[part 1 of 2: packages /CAN3/ISignalGroup to /CAN3/Cluster]
AUTOSAR XML (schema 4-3-0)
package /CAN3/ISignalGroup
  36 x i signal group:
    CAN3_SG_BMS1: i-signal=[CAN3_BMSChckSum_1, CAN3_BMSRolCnct_1, CAN3_HVBPwrAvailChrg, CAN3_HVBPwrAvailChrg30, CAN3_HVBPwrAvailChrg60, CAN3_HVBPwrAvailDchrg, CAN3_HVBPwrAvailDchrg30, CAN3_HVBPwrAvailDchrg60, CAN3_HVBattCurr, CAN3_HVBattVolt], system-signal-group=CAN3_SG_BMS1
    CAN3_SG_BMS3: i-signal=[CAN3_ACChrgCurrDis, CAN3_Battsystfail_Num, CAN3_CellType, CAN3_ChrgCurType, CAN3_ChrgLampSta, CAN3_FireDetErr, CAN3_HVBChrgPwr, CAN3_HVBChrgPwrTotal, CAN3_HVBDrvPwr, CAN3_HVBDrvPwrTotal, CAN3_HVBFullChrgPwr, CAN3_HVBIsoImpedenceN, CAN3_HVBIsoImpedenceP, CAN3_HVBSOH, CAN3_HVBattErr, CAN3_HVBattPackVolt, CAN3_HVBattSOC, CAN3_HVBattSOCDis, CAN3_RechrgCyc, CAN3_RemainChrgTime], system-signal-group=CAN3_SG_BMS3
    CAN3_SG_BMS4: i-signal=[CAN3_CellTempAvg, CAN3_HVBCellVoltMax, CAN3_HVBCellVoltMin, CAN3_HVBMTempMax, CAN3_HVBMTempMin, CAN3_MaxCellTemp_Num, CAN3_MaxCellVolt_Num, CAN3_MinCellTemp_Num, CAN3_MinCellVolt_Num, CAN3_Mtemp01, CAN3_Mtemp02, CAN3_Mtemp03, CAN3_Mtemp04, CAN3_Mtemp05, CAN3_Mtemp06, CAN3_Mtemp07, CAN3_Mtemp08, CAN3_Mtemp09, CAN3_Mtemp10, CAN3_Mtemp11, CAN3_Mtemp12, CAN3_Mtemp13, CAN3_Mtemp14, CAN3_Mtemp15, CAN3_Mtemp16, CAN3_Mtemp17, CAN3_Mtemp18, CAN3_Mtemp19, CAN3_Mtemp20], system-signal-group=CAN3_SG_BMS4
    CAN3_SG_BMS5: i-signal=[CAN3_DCPortNeg_Temp, CAN3_DCPortPos_Temp, CAN3_HVInVolt, CAN3_LVBattDet12V, CAN3_OBCACCSLimit, CAN3_OBCDCCurLm, CAN3_OBCDCVoltLm, CAN3_OBCEna, CAN3_ReChargerStaFromEvcc], system-signal-group=CAN3_SG_BMS5
    CAN3_SG_BMS6: i-signal=[CAN3_BMSChckSum, CAN3_BMSRolCnct, CAN3_BMS_READY, CAN3_BMS_Warn_1, CAN3_BMS_Warn_2, CAN3_BMS_Warn_3, CAN3_BMS_Warn_4, CAN3_BMS_Warn_5, CAN3_BMS_Warn_6, CAN3_BMS_Warn_7, CAN3_BMS_Warn_8, CAN3_CellUnconsistErr, CAN3_ChrgInLockReq, CAN3_ChrgPlugSta, CAN3_DCChrgSysShockErr, CAN3_DisChrgPlugErr, CAN3_ExtChrgSta, CAN3_HVBCellOvrVoltErr, CAN3_HVBCellOvrVoltWarn, CAN3_HVBCellUdrVoltWarn, CAN3_HVBCellUnbalanErr, CAN3_HVBCellUndrVoltErr, CAN3_HVBChrgErr, CAN3_HVBContactorSta, CAN3_HVBHVILErr, CAN3_HVBOvrChrgCurrErr, CAN3_HVBOvrDchrgCurErr, CAN3_HVBOvrSOCErr, CAN3_HVBOvrTempErr, CAN3_HVBOvrTempWarn, CAN3_HVBOvrVoltErr, CAN3_HVBPrechrgSta, CAN3_HVBPreheatPrecoolSta, CAN3_HVBSOCJumpError, CAN3_HVBShrtChrgCurrErr, CAN3_HVBShrtDischrgCurrErr, CAN3_HVBTempDiffErr, CAN3_HVBUndrSOCErr, CAN3_HVBUndrTempErr, CAN3_HVBUndrTempWarn, CAN3_HVBUndrVoltErr, CAN3_HVBattReady4Pre, CAN3_HVILSta, CAN3_IsoDetSta, CAN3_SystemUncomErr, CAN3_V2LSta], system-signal-group=CAN3_SG_BMS6
    CAN3_SG_BMS8: i-signal=[CAN3_ACChrgStop, CAN3_CurrentErrorID, CAN3_DCChrgCurrent, CAN3_DCChrgStop, CAN3_DCChrgVoltage, CAN3_G0standard, CAN3_MainChrgRlyNegDriReq, CAN3_MainChrgRlyNegOutterVoltage, CAN3_MainChrgRlyNegSta, CAN3_MainChrgRlyPosDriReq, CAN3_MainChrgRlyPosOutterVoltage, CAN3_MainChrgRlyPosSta, CAN3_MainPosstandard, CAN3_MainRlyNegDriReq, CAN3_MainRlyNegOutterVoltage, CAN3_MainRlyNegSta, CAN3_MainRlyPosDriReq, CAN3_MainRlyPosInnerVoltage, CAN3_MainRlyPosOutterVoltage, CAN3_MainRlyPosSta, CAN3_TherRunawayErrMask], system-signal-group=CAN3_SG_BMS8
    CAN3_SG_CCU1: i-signal=[CAN3_CS_CCU1, CAN3_DCDCAuxCur, CAN3_DCDCAuxVolt, CAN3_DCDCHVCur, CAN3_DCDCInVoltInf, CAN3_DCDCPreCompleted, CAN3_OBCDCCurrInf, CAN3_OBCDCVoltInf, CAN3_OBCPreCompleted, CAN3_OBCV2LINVOTP, CAN3_OBCV2LInsuFault, CAN3_OBCV2LVinOVP, CAN3_OBCV2LVinUVP, CAN3_OBCV2LVoutOCP, CAN3_OBCV2LVoutOVP, CAN3_OBCV2LVoutUVP, CAN3_OBCWakeup4Plugin, CAN3_RC_CCU1], system-signal-group=CAN3_SG_CCU1
    CAN3_SG_CCU2: i-signal=[CAN3_CS_CCU2, CAN3_DCDCEnaSta, CAN3_DCDCFaultSta, CAN3_DCDCReady4Pre, CAN3_DCDCTemp, CAN3_OBCACCurrInf, CAN3_OBCACVoltInf, CAN3_OBCDCP, CAN3_OBCEnaSta, CAN3_OBCFaultSta, CAN3_OBCPluginSta, CAN3_OBCReady4Pre, CAN3_OBCRlySta, CAN3_OBCTemp, CAN3_OBCV2LSta, CAN3_OBC_AC_Cur_Lim, CAN3_RC_CCU2], system-signal-group=CAN3_SG_CCU2
    CAN3_SG_EBM1: i-signal=[CAN3_EBM1_CS, CAN3_EBM1_RC, CAN3_EBMErrSta, CAN3_EBMRLampSta, CAN3_EBMSta], system-signal-group=CAN3_SG_EBM1
    CAN3_SG_FD3_BCM1: i-signal=[CAN3_AllDoorSW, CAN3_AntiTheftSeatFold, CAN3_AntitheftSta, CAN3_BCM_Buzzer_Req, CAN3_BCM_DoorLock_Sta, CAN3_BrakeLamp, CAN3_CTDCtrl, CAN3_CTDLockSW, CAN3_CTDUnlockSW, CAN3_CrashDetd, CAN3_Dimmer, CAN3_DimmerEN, CAN3_DoorLockIND, CAN3_DrDoorSW, CAN3_Fr_ChargingDoorCtrl, CAN3_Fr_FogLamp, CAN3_Fr_Wiper_H, CAN3_Fr_Wiper_L, CAN3_H_Beam, CAN3_HazardSW, CAN3_HoodSW, CAN3_HornCtrl, CAN3_LBSD, CAN3_LDRL, CAN3_LTurnLP, CAN3_L_APM_WdwEnable, CAN3_L_Beam, CAN3_LockSetting, CAN3_MirrorCtrl, CAN3_MirrorDefog, CAN3_PosLamp, CAN3_PsDoorSW, CAN3_RBSD, CAN3_RDRL, CAN3_RLDoorSW, CAN3_RRDoorSW, CAN3_RTurnLP, CAN3_ReverseLamp, CAN3_RoomLampH, CAN3_RoomLampL, CAN3_Rr_ChargingDoorCtrl, CAN3_Rr_Defog, CAN3_Rr_FogLamp, CAN3_Rr_Wiper, CAN3_TailgateHDSW, CAN3_TailgateRemote, CAN3_Tailgate_SW, CAN3_TrunkRel, CAN3_WasherCtrl, CAN3_WiperFixMode], system-signal-group=CAN3_SG_FD3_BCM1
    CAN3_SG_FD3_OTA1: i-signal=[CAN3_OTA_DL_Available, CAN3_OTA_DL_Speed, CAN3_OTA_Debug_Code, CAN3_OTA_Emergency_Sta, CAN3_OTA_InVehicle_FW, CAN3_OTA_Lock_Req, CAN3_OTA_MDA_Status, CAN3_OTA_Mode, CAN3_OTA_Network_Type, CAN3_OTA_Permit_Agreed, CAN3_OTA_Progress_Rate, CAN3_OTA_Remained_Time, CAN3_OTA_TBOXResetReq, CAN3_OTA_Update_Available, CAN3_OTA_Updating_ECU_8bit], system-signal-group=CAN3_SG_FD3_OTA1
    CAN3_SG_FD3_THCM1: i-signal=[CAN3_BatteryMode, CAN3_CCU_ACLampSts, CAN3_CCU_ACMaxLampSts, CAN3_CCU_AutoLampSts, CAN3_CCU_AutoMidLampSts, CAN3_CCU_Dispaly_Request, CAN3_CCU_EcoSts, CAN3_CCU_FrtOnOffLampSts, CAN3_CCU_HEATMaxLampSts, CAN3_CCU_RrOnOffLampSts, CAN3_CCU_SyncLampSts, CAN3_CabinMode, CAN3_EDriveMode, CAN3_FD_AGS_Cmd, CAN3_FD_RecyAuto_Cmd, CAN3_Fr_Coolantflow, CAN3_Fr_Coolanttemp, CAN3_HPThermalRecoveryReq, CAN3_Rr_Coolantflow, CAN3_Rr_Coolanttemp, CAN3_sigAirIntenZon1St, CAN3_sigAirIntenZon3St, CAN3_sigAmbAirT, CAN3_sigCbnAirT, CAN3_sigCbnPTCPwrAct, CAN3_sigCbnSolarLeft, CAN3_sigCbnSolarRight, CAN3_sigClmtCmprPwrAct, CAN3_sigClntTHvBattOut, CAN3_sigDfrstSt, CAN3_sigHvacSt, CAN3_sigRecircSt, CAN3_sigSetTempZon1St, CAN3_sigSetTempZon2St, CAN3_sigSetTempZon3St, CAN3_sigWindDirZon1St, CAN3_sigWindDirZon3St], system-signal-group=CAN3_SG_FD3_THCM1
    CAN3_SG_FD3_THCM2: i-signal=[CAN3_ACSubMode, CAN3_APTC_ActFrRiPwr, CAN3_BatLoopActWtFlw, CAN3_CCU_CbnPreACWkSts, CAN3_CCU_CbnPreEstimdTi, CAN3_CCU_CbnPreSts, CAN3_CCU_HiVoltageReq, CAN3_CoolgFanActDuty, CAN3_DeiceModReq, CAN3_FD_Blower_Cmd, CAN3_FD_Comp_Cmd, CAN3_FD_EWP1_Cmd, CAN3_FD_EWP2_Cmd, CAN3_FD_EWP3_Cmd, CAN3_FD_EXV1_Cmd, CAN3_FD_EXV2_Cmd, CAN3_FD_FWV_Cmd, CAN3_FD_FrLeAPTCHeatPwr_Cmd, CAN3_FD_FrRiAPTCHeatPwr_Cmd, CAN3_FD_FrWPTCHeatPwr_Cmd, CAN3_FD_RrAPTCHeatPwr_Cmd, CAN3_FD_SOTXV_Cmd, CAN3_FD_SOV1_Cmd, CAN3_FD_SOV2_Cmd, CAN3_FD_SOV3_Cmd, CAN3_FD_TWV_Cmd], system-signal-group=CAN3_SG_FD3_THCM2
    CAN3_SG_FD3_V2L1: i-signal=[CAN3_Req_OBCV2LEna, CAN3_Req_V2LSwOn, CAN3_Req_V2L_IVI_Popup], system-signal-group=CAN3_SG_FD3_V2L1
    CAN3_SG_FD3_VCU0: i-signal=[CAN3_EVCCAplusPwrUpReq, CAN3_FDADC12VDet, CAN3_FDADC12VDetAvg, CAN3_FDC_VCU_ActMaxSlideRate_Sta, CAN3_FDC_VCU_AllowMovThd_OTA_Sta, CAN3_FDC_VCU_DTCCarousel_Sta, CAN3_FDC_VCU_ForceP_Cmd, CAN3_FDC_VCU_OTAPwrReqOFFChk_Sta, CAN3_FDC_VCU_OTAPwrReqStdChk_Sta, CAN3_FDC_VCU_PwrReq_OTA_Sta, CAN3_FDC_VCU_RWDRDCActive_Sta, CAN3_FDC_VCU_RegenTqLimitEn_Sta, CAN3_FDC_VCU_SlideRegenLimTq_Sta, CAN3_FDC_VCU_VehActSpd_Sta, CAN3_FDC_VCU_VehMalfunLevel_Sta, CAN3_FDC_VMC_ActStESCYaw_Sta, CAN3_FDC_VMC_LongAcc_Sta, CAN3_FUSION_CMM1, CAN3_FUSION_CMM10, CAN3_FUSION_CMM2, CAN3_FUSION_CMM3, CAN3_FUSION_CMM4, CAN3_FUSION_CMM5, CAN3_FUSION_CMM6, CAN3_FUSION_CMM7, CAN3_FUSION_CMM8, CAN3_FUSION_CMM9, CAN3_Fr_TqSource, CAN3_HVRlyOpFail, CAN3_HVTHCMSysAvail, CAN3_LVBattChrgtimeAct, CAN3_LVBattVoltSta, CAN3_LVChrgHoldTAct, CAN3_LVSilentChrgLv, CAN3_LVSilentChrgReq, CAN3_LVSilentChrgSta, CAN3_MCUActDisFail, CAN3_PMMAllowECUSleep, CAN3_PmicBootReason, CAN3_PowerDownFault, CAN3_PowerDownState, CAN3_PowerUpFault, CAN3_PowerUpState, CAN3_PwrDownReq, CAN3_PwrStaConstraint, CAN3_PwrStaONTOIVIPopReq, CAN3_PwrStaONTOIVIPopT, CAN3_PwrStaSelect, CAN3_PwrStaTOSta, CAN3_PwrUpReq, CAN3_Rr_TqSource, CAN3_SchedChgTOSta, CAN3_SilentChkAllowSleep, CAN3_SysAllowReadySta, CAN3_SysPwrSta, CAN3_TCountSta, CAN3_TimerAllowSleep, CAN3_VCUBrkSWSta, CAN3_VCUFLDoorSta, CAN3_VCUFRDoorSta, CAN3_VCURLDoorSta, CAN3_VCURRDoorSta, CAN3_VehHVPwrAvail4THCM, CAN3_WisrBootReason], system-signal-group=CAN3_SG_FD3_VCU0
    CAN3_SG_FD3_VCU1:
      com-based-signal-group-transformations=E2E_PROFILE_01_CAN3_SG_FD3_VCU1
      i-signal=[CAN3_ActiveDischReq, CAN3_CS_VCU1, CAN3_CoastDwModeStaChk, CAN3_DCDCEnaReq, CAN3_DCDCVoltSetpoint, CAN3_DemoModeStaChk, CAN3_Dr_SeatSta, CAN3_DynoModeStaChk, CAN3_HVBatCnctReq, CAN3_HVSysReadyToCharge, CAN3_LVChrgFuncStaChk, CAN3_MSA_Crl_Sta, CAN3_P_Button_Sta, CAN3_PrkReq, CAN3_PrkReqValid, CAN3_PwrSta, CAN3_RC_VCU1, CAN3_ShiftGearPosn]
      system-signal-group=CAN3_SG_FD3_VCU1
      end-to-end-transformation-i-signal-props{transformer=Technology_E2E_PROFILE_01_CAN3_SG_FD3_VCU1, data-ids=17910, data-length=64}
    CAN3_SG_FD3_VCU1_toNIDEC:
      com-based-signal-group-transformations=E2E_PROFILE_01_CAN3_SG_FD3_VCU1_toNIDEC
      i-signal=[CAN3_ActiveDischReq_toNidec, CAN3_CS_VCU1_toNidec, CAN3_CoastDwModeStaChk_toNidec, CAN3_DCDCEnaReq_toNidec, CAN3_DCDCVoltSetpoint_toNidec, CAN3_DemoModeStaChk_toNidec, CAN3_Dr_SeatSta_toNidec, CAN3_DynoModeStaChk_toNidec, CAN3_Fr_ActvDmpDisabReq_toNidec, CAN3_Fr_MCUEnaReq_toNidec, CAN3_HVBatCnctReq_toNidec, CAN3_HVSysReadyToCharge_toNidec, CAN3_LVChrgFuncStaChk_toNidec, CAN3_MSA_Crl_Sta_toNidec, CAN3_PrkReq_toNidec, CAN3_PwrSta_toNidec, CAN3_RC_VCU1_toNidec, CAN3_Rr_ActvDmpDisabReq_toNidec, CAN3_Rr_MCUEnaReq_toNidec, CAN3_ShiftGearPosn_toNidec]
      system-signal-group=CAN3_SG_FD3_VCU1_toNIDEC
      end-to-end-transformation-i-signal-props{transformer=Technology_E2E_PROFILE_01_CAN3_SG_FD3_VCU1_toNIDEC, data-ids=13815, data-length=64}
    CAN3_SG_FD3_VCU2: i-signal=[CAN3_CS_VCU2_CAN1, CAN3_Fr_ActvDmpDisabReq, CAN3_Fr_IdcMax, CAN3_Fr_IdcMin, CAN3_Fr_MCUEnaReq, CAN3_Fr_TMTqReq, CAN3_Fr_TorqMax, CAN3_Fr_TorqMin, CAN3_Fr_UdcMax, CAN3_Fr_UdcMin, CAN3_RC_VCU2_CAN1, CAN3_Rr_ActvDmpDisabReq, CAN3_Rr_IdcMax, CAN3_Rr_IdcMin, CAN3_Rr_MCUEnaReq, CAN3_Rr_TMTqReq, CAN3_Rr_TorqMax, CAN3_Rr_TorqMin, CAN3_Rr_UdcMax, CAN3_Rr_UdcMin], system-signal-group=CAN3_SG_FD3_VCU2
    CAN3_SG_FD3_VCU2_toNIDEC: i-signal=[CAN3_CS_VCU2_CAN1_toNidec, CAN3_Fr_IdcMax_toNidec, CAN3_Fr_IdcMin_toNidec, CAN3_Fr_TMTqReq_toNidec, CAN3_Fr_TorqMax_toNidec, CAN3_Fr_TorqMin_toNidec, CAN3_Fr_UdcMax_toNidec, CAN3_Fr_UdcMin_toNidec, CAN3_RC_VCU2_CAN1_toNidec, CAN3_Rr_IdcMax_toNidec, CAN3_Rr_IdcMin_toNidec, CAN3_Rr_TMTqReq_toNidec, CAN3_Rr_TorqMax_toNidec, CAN3_Rr_TorqMin_toNidec, CAN3_Rr_UdcMax_toNidec, CAN3_Rr_UdcMin_toNidec], system-signal-group=CAN3_SG_FD3_VCU2_toNIDEC
    CAN3_SG_FD3_VCU4: i-signal=[CAN3_Fr_SpdMax, CAN3_Fr_SpdMin, CAN3_Fr_TMCtrlMode_Req, CAN3_Fr_TMSpdReq, CAN3_Rr_SpdMax, CAN3_Rr_SpdMin, CAN3_Rr_TMCtrlMode_Req, CAN3_Rr_TMSpdReq], system-signal-group=CAN3_SG_FD3_VCU4
    CAN3_SG_FD3_VCU5: i-signal=[CAN3_ActAPSPosn, CAN3_Fr_EDUSpd, CAN3_Fr_EDUSpdValid, CAN3_Rr_EDUSpd, CAN3_Rr_EDUSpdValid], system-signal-group=CAN3_SG_FD3_VCU5
    CAN3_SG_GW3_CE100_0: i-signal=[CAN3_AC_Chg_Cur_Set, CAN3_COMP_ActualPwr, CAN3_COMP_ConCur, CAN3_COMP_ConVolt, CAN3_ChargeInletLockSta, CAN3_Charge_Percent_Set, CAN3_CrashOutputSts, CAN3_DriverSeatBeltCmd, CAN3_IVI_Req_V2L, CAN3_IVI_Start_Chg_req, CAN3_IVI_Stop_Chg_req, CAN3_IVI_Time_Day, CAN3_IVI_Time_Hour, CAN3_IVI_Time_Minute, CAN3_IVI_Time_Month, CAN3_IVI_Time_Second, CAN3_IVI_Unlock_Chg_req, CAN3_PTC1_PowerConsumption, CAN3_Perd_V2L, CAN3_ReserveChargeOFF_Day, CAN3_ReserveChargeOFF_Hour, CAN3_ReserveChargeOFF_Minute, CAN3_ReserveChargeOFF_Month, CAN3_ReserveChargeOFF_Year, CAN3_ReserveChargeOn_Day, CAN3_ReserveChargeOn_Hour, CAN3_ReserveChargeOn_Minute, CAN3_ReserveChargeOn_Month, CAN3_ReserveChargeOn_Year, CAN3_SOC_ADJ_BUTT, CAN3_SOC_Limit_Set, CAN3_SOC_V2LLimit, CAN3_Sched_Chg_Start, CAN3_Sched_Chg_Stop, CAN3_Sched_Chg_butt, CAN3_Sched_Chg_limit, CAN3_VehSpeed], system-signal-group=CAN3_SG_GW3_CE100_0
    CAN3_SG_GW_ESC1_toNIDEC: i-signal=CAN3_VehSpeed_toNidec, system-signal-group=CAN3_SG_GW_ESC1_toNIDEC
    CAN3_SG_GW_IVI6_toNIDEC: i-signal=[CAN3_IVI_Time_Day_toNidec, CAN3_IVI_Time_Hour_toNidec, CAN3_IVI_Time_Minute_toNidec, CAN3_IVI_Time_Month_toNidec, CAN3_IVI_Time_Second_toNidec], system-signal-group=CAN3_SG_GW_IVI6_toNIDEC
    CAN3_SG_MCU_B_F1: i-signal=[CAN3_Fr_ActvDmpDisabSta, CAN3_Fr_EDUDrtSta, CAN3_Fr_EDUOpratingSta, CAN3_Fr_EDURealTMTq, CAN3_Fr_EDURotateDirction, CAN3_Fr_EDUTqReqFbk, CAN3_Fr_MCU1Chksum, CAN3_Fr_MCU1RolCnt, CAN3_Fr_MCUBAT, CAN3_Fr_MCUDCBusCurr, CAN3_Fr_MCUDCBusVolt, CAN3_Fr_MCUDischrgSta, CAN3_Fr_MCUEnaSta, CAN3_Fr_MCUErr, CAN3_Fr_MCUIGN_sta, CAN3_Fr_MCUReady, CAN3_Fr_MCUReady4Pre, CAN3_Fr_MCUSysSta, CAN3_Fr_MCUTemp, CAN3_Fr_MotorAvailTq, CAN3_Fr_RegenAvailTq, CAN3_Fr_Reserved_bits, CAN3_Fr_TMSpd, CAN3_Fr_TMTemp, CAN3_Fr_TMid, CAN3_Fr_TMiq, CAN3_MCUWarn_F], system-signal-group=CAN3_SG_MCU_B_F1
    CAN3_SG_MCU_B_F2: i-signal=[CAN3_Fr_CoolanttempReq, CAN3_Fr_Failcode1, CAN3_Fr_Failcode2, CAN3_Fr_Failcodehistory1, CAN3_Fr_Failcodehistory2, CAN3_Fr_LLCTemp, CAN3_Fr_LLCflowReq, CAN3_Fr_MCU2Chksum, CAN3_Fr_MCU2RolCnt, CAN3_Fr_MCUTempWarn, CAN3_Fr_MCU_HW_Ver, CAN3_Fr_MCU_SW_Ver, CAN3_Fr_TMTempWarn, CAN3_MCU_B_F_FailLv_Sta, CAN3_MCU_B_F_LLCTempWarn_Sta], system-signal-group=CAN3_SG_MCU_B_F2
    CAN3_SG_MCU_B_R1: i-signal=[CAN3_MCUWarn_R, CAN3_Rr_ActvDmpDisabSta, CAN3_Rr_EDUDrtSta, CAN3_Rr_EDUOpratingSta, CAN3_Rr_EDURealTMTq, CAN3_Rr_EDURotateDirction, CAN3_Rr_EDUTqReqFbk, CAN3_Rr_MCU1Chksum, CAN3_Rr_MCU1RolCnt, CAN3_Rr_MCUBAT, CAN3_Rr_MCUDCBusCurr, CAN3_Rr_MCUDCBusVolt, CAN3_Rr_MCUDischrgSta, CAN3_Rr_MCUEnaSta, CAN3_Rr_MCUErr, CAN3_Rr_MCUIGN_sta, CAN3_Rr_MCUReady, CAN3_Rr_MCUReady4Pre, CAN3_Rr_MCUSysSta, CAN3_Rr_MCUTemp, CAN3_Rr_MotorAvailTq, CAN3_Rr_RegenAvailTq, CAN3_Rr_Reserved_bits, CAN3_Rr_TMSpd, CAN3_Rr_TMTemp, CAN3_Rr_TMid, CAN3_Rr_TMiq], system-signal-group=CAN3_SG_MCU_B_R1
    CAN3_SG_MCU_B_R2: i-signal=[CAN3_MCU_B_R_FailLv_Sta, CAN3_MCU_B_R_LLCTempWarn_Sta, CAN3_Rr_CoolanttempReq, CAN3_Rr_Failcode1, CAN3_Rr_Failcode2, CAN3_Rr_Failcodehistory1, CAN3_Rr_Failcodehistory2, CAN3_Rr_LLCTemp, CAN3_Rr_LLCflowReq, CAN3_Rr_MCU2Chksum, CAN3_Rr_MCU2RolCnt, CAN3_Rr_MCU3_HW_Ver, CAN3_Rr_MCU3_SW_Ver, CAN3_Rr_MCUTempWarn, CAN3_Rr_TMTempWarn], system-signal-group=CAN3_SG_MCU_B_R2
    CAN3_SG_MCU_N_F1: i-signal=[CAN3_Fr_ActvDmpDisabSta_Nidec, CAN3_Fr_EDUDrtSta_Nidec, CAN3_Fr_EDUOpratingSta_Nidec, CAN3_Fr_EDURealTMTq_Nidec, CAN3_Fr_EDURotateDirction_Nidec, CAN3_Fr_EDUTqReqFbk_Nidec, CAN3_Fr_MCU1Chksum_Nidec, CAN3_Fr_MCU1RolCnt_Nidec, CAN3_Fr_MCUBAT_Nidec, CAN3_Fr_MCUDCBusCurr_Nidec, CAN3_Fr_MCUDCBusVolt_Nidec, CAN3_Fr_MCUDischrgSta_Nidec, CAN3_Fr_MCUEnaSta_Nidec, CAN3_Fr_MCUErr_Nidec, CAN3_Fr_MCUIGN_sta_Nidec, CAN3_Fr_MCUReady4Pre_Nidec, CAN3_Fr_MCUReady_Nidec, CAN3_Fr_MCUSysSta_Nidec, CAN3_Fr_MCUTemp_Nidec, CAN3_Fr_MotorAvailTq_Nidec, CAN3_Fr_RegenAvailTq_Nidec, CAN3_Fr_Reserved_bits_Nidec, CAN3_Fr_TMSpd_Nidec, CAN3_Fr_TMTemp_Nidec, CAN3_Fr_TMid_Nidec, CAN3_Fr_TMiq_Nidec, CAN3_MCUWarn_F_Nidec], system-signal-group=CAN3_SG_MCU_N_F1
    CAN3_SG_MCU_N_F2: i-signal=[CAN3_Fr_CoolanttempReq_Nidec, CAN3_Fr_EOP_SpdSet_Nidec, CAN3_Fr_Failcode1_Nidec, CAN3_Fr_Failcode2_Nidec, CAN3_Fr_Failcodehistory1_Nidec, CAN3_Fr_Failcodehistory2_Nidec, CAN3_Fr_LLCTemp_Nidec, CAN3_Fr_LLCflowReq_Nidec, CAN3_Fr_MCU2Chksum_Nidec, CAN3_Fr_MCU2RolCnt_Nidec, CAN3_Fr_MCUTempWarn_Nidec, CAN3_Fr_TMTempWarn_Nidec, CAN3_MCU_F_ResetCnt_Sta], system-signal-group=CAN3_SG_MCU_N_F2
    CAN3_SG_MCU_N_F3: i-signal=[CAN3_Fr_MCU_HW_Ver_Nidec, CAN3_Fr_MCU_SW_Ver_Nidec], system-signal-group=CAN3_SG_MCU_N_F3
    CAN3_SG_MCU_N_R1: i-signal=[CAN3_MCUWarn_R_Nidec, CAN3_Rr_ActvDmpDisabSta_Nidec, CAN3_Rr_EDUDrtSta_Nidec, CAN3_Rr_EDUOpratingSta_Nidec, CAN3_Rr_EDURealTMTq_Nidec, CAN3_Rr_EDURotateDirction_Nidec, CAN3_Rr_EDUTqReqFbk_Nidec, CAN3_Rr_MCU1Chksum_Nidec, CAN3_Rr_MCU1RolCnt_Nidec, CAN3_Rr_MCUBAT_Nidec, CAN3_Rr_MCUDCBusCurr_Nidec, CAN3_Rr_MCUDCBusVolt_Nidec, CAN3_Rr_MCUDischrgSta_Nidec, CAN3_Rr_MCUEnaSta_Nidec, CAN3_Rr_MCUErr_Nidec, CAN3_Rr_MCUIGN_sta_Nidec, CAN3_Rr_MCUReady4Pre_Nidec, CAN3_Rr_MCUReady_Nidec, CAN3_Rr_MCUSysSta_Nidec, CAN3_Rr_MCUTemp_Nidec, CAN3_Rr_MotorAvailTq_Nidec, CAN3_Rr_RegenAvailTq_Nidec, CAN3_Rr_Reserved_bits_Nidec, CAN3_Rr_TMSpd_Nidec, CAN3_Rr_TMTemp_Nidec, CAN3_Rr_TMid_Nidec, CAN3_Rr_TMiq_Nidec], system-signal-group=CAN3_SG_MCU_N_R1
    CAN3_SG_MCU_N_R2: i-signal=[CAN3_MCU_R_ResetCnt_Sta, CAN3_Rr_CoolanttempReq_Nidec, CAN3_Rr_EOP_SpdSet_Nidec, CAN3_Rr_Failcode1_Nidec, CAN3_Rr_Failcode2_Nidec, CAN3_Rr_Failcodehistory1_Nidec, CAN3_Rr_Failcodehistory2_Nidec, CAN3_Rr_LLCTemp_Nidec, CAN3_Rr_LLCflowReq_Nidec, CAN3_Rr_MCU2Chksum_Nidec, CAN3_Rr_MCU2RolCnt_Nidec, CAN3_Rr_MCUTempWarn_Nidec, CAN3_Rr_TMTempWarn_Nidec], system-signal-group=CAN3_SG_MCU_N_R2
    CAN3_SG_MCU_N_R3: i-signal=[CAN3_Rr_MCU3_HW_Ver_Nidec, CAN3_Rr_MCU3_SW_Ver_Nidec], system-signal-group=CAN3_SG_MCU_N_R3
    CAN3_SG_Shifter1: i-signal=[CAN3_Shifter_CRC8, CAN3_Shifter_Fail_sta, CAN3_Shifter_Handle_Cmd, CAN3_Shifter_RC], system-signal-group=CAN3_SG_Shifter1
    CAN3_SG_Shifter2: i-signal=[CAN3_CSW2_DimSw_Sta, CAN3_CSW2_FWasSw_Sta, CAN3_CSW2_FWipSw_Sta, CAN3_CSW2_PassSW_Sta, CAN3_CSW2_RWipWasSw_Sta, CAN3_CSW2_TurnSw_Sta], system-signal-group=CAN3_SG_Shifter2
package /CAN3/Cluster
  can cluster CAN3: baudrate=500, can-fd-baudrate=2000
    can physical channel CAN3: comm-connectors=ConnCAN3
      frame CAN3_BMS1: id 0x171, frame-length=16, can-addressing-mode=STANDARD, can-fd-frame-support=true, can-frame-rx-behavior=CAN-FD, can-frame-tx-behavior=CAN-FD
        pdu CAN3_BMS1: length=16, minimum-delay=0.0, transmission-mode-true-timing=cyclic-timing=time-period=0.01, unused-bit-pattern=0
          mapping CAN3_SG_BMS1: i-signal-group=CAN3_SG_BMS1, start-position=0, transfer-property=PENDING
          signal CAN3_BMSChckSum_1: start 7, 8 bit, big-endian, i-signal-type=PRIMITIVE, init-value=constant-reference=Init_CAN3_BMSChckSum_1, base-type=uint8, implementation-data-type=uint8, transfer-property=PENDING
          signal CAN3_BMSRolCnct_1: start 11, 4 bit, big-endian, i-signal-type=PRIMITIVE, init-value=constant-reference=Init_CAN3_BMSRolCnct_1, base-type=uint8, implementation-data-type=uint8, transfer-property=PENDING
          signal CAN3_HVBPwrAvailChrg: start 91, 12 bit, big-endian, i-signal-type=PRIMITIVE, init-value=constant-reference=Init_CAN3_HVBPwrAvailChrg, base-type=uint16, implementation-data-type=uint16, transfer-property=PENDING
          signal CAN3_HVBPwrAvailChrg30: start 115, 12 bit, big-endian, i-signal-type=PRIMITIVE, init-value=constant-reference=Init_CAN3_HVBPwrAvailChrg30, base-type=uint16, implementation-data-type=uint16, transfer-property=PENDING
          signal CAN3_HVBPwrAvailChrg60: start 67, 12 bit, big-endian, i-signal-type=PRIMITIVE, init-value=constant-reference=Init_CAN3_HVBPwrAvailChrg60, base-type=uint16, implementation-data-type=uint16, transfer-property=PENDING
          signal CAN3_HVBPwrAvailDchrg: start 87, 12 bit, big-endian, i-signal-type=PRIMITIVE, init-value=constant-reference=Init_CAN3_HVBPwrAvailDchrg, base-type=uint16, implementation-data-type=uint16, transfer-property=PENDING
          signal CAN3_HVBPwrAvailDchrg30: start 111, 12 bit, big-endian, i-signal-type=PRIMITIVE, init-value=constant-reference=Init_CAN3_HVBPwrAvailDchrg30, base-type=uint16, implementation-data-type=uint16, transfer-property=PENDING
          signal CAN3_HVBPwrAvailDchrg60: start 63, 12 bit, big-endian, i-signal-type=PRIMITIVE, init-value=constant-reference=Init_CAN3_HVBPwrAvailDchrg60, base-type=uint16, implementation-data-type=uint16, transfer-property=PENDING
          signal CAN3_HVBattCurr: start 46, 15 bit, big-endian, i-signal-type=PRIMITIVE, init-value=constant-reference=Init_CAN3_HVBattCurr, base-type=uint16, implementation-data-type=uint16, transfer-property=PENDING
          signal CAN3_HVBattVolt: start 28, 13 bit, big-endian, i-signal-type=PRIMITIVE, init-value=constant-reference=Init_CAN3_HVBattVolt, base-type=uint16, implementation-data-type=uint16, transfer-property=PENDING
      frame CAN3_BMS3: id 0x329, frame-length=32, can-addressing-mode=STANDARD, can-fd-frame-support=true, can-frame-rx-behavior=CAN-FD, can-frame-tx-behavior=CAN-FD
        pdu CAN3_BMS3: length=32, minimum-delay=0.0, transmission-mode-true-timing={cyclic-timing=time-period=1, event-controlled-timing={number-of-repetitions=0, repetition-period=0}}, unused-bit-pattern=0
          mapping CAN3_SG_BMS3: i-signal-group=CAN3_SG_BMS3, start-position=0, transfer-property=TRIGGERED-ON-CHANGE
          signal CAN3_ACChrgCurrDis: start 54, 15 bit, big-endian, i-signal-type=PRIMITIVE, init-value=constant-reference=Init_CAN3_ACChrgCurrDis, base-type=uint16, implementation-data-type=uint16, transfer-property=PENDING
          signal CAN3_Battsystfail_Num: start 95, 8 bit, big-endian, i-signal-type=PRIMITIVE, init-value=constant-reference=Init_CAN3_Battsystfail_Num, base-type=uint8, implementation-data-type=uint8, transfer-property=PENDING
          signal CAN3_CellType: start 69, 4 bit, big-endian, i-signal-type=PRIMITIVE, init-value=constant-reference=Init_CAN3_CellType, base-type=uint8, implementation-data-type=uint8, transfer-property=PENDING
          signal CAN3_ChrgCurType: start 233, 2 bit, big-endian, i-signal-type=PRIMITIVE, init-value=constant-reference=Init_CAN3_ChrgCurType, base-type=uint8, implementation-data-type=uint8, transfer-property=TRIGGERED-ON-CHANGE
          signal CAN3_ChrgLampSta: start 235, 2 bit, big-endian, i-signal-type=PRIMITIVE, init-value=constant-reference=Init_CAN3_ChrgLampSta, base-type=uint8, implementation-data-type=uint8, transfer-property=TRIGGERED-ON-CHANGE
          signal CAN3_FireDetErr: start 239, 1 bit, big-endian, i-signal-type=PRIMITIVE, init-value=constant-reference=Init_CAN3_FireDetErr, base-type=uint8, implementation-data-type=uint8, transfer-property=TRIGGERED-ON-CHANGE
          signal CAN3_HVBChrgPwr: start 185, 10 bit, big-endian, i-signal-type=PRIMITIVE, init-value=constant-reference=Init_CAN3_HVBChrgPwr, base-type=uint16, implementation-data-type=uint16, transfer-property=PENDING
          signal CAN3_HVBChrgPwrTotal: start 25, 18 bit, big-endian, i-signal-type=PRIMITIVE, init-value=constant-reference=Init_CAN3_HVBChrgPwrTotal, base-type=uint32, implementation-data-type=uint32, transfer-property=PENDING
          signal CAN3_HVBDrvPwr: start 169, 10 bit, big-endian, i-signal-type=PRIMITIVE, init-value=constant-reference=Init_CAN3_HVBDrvPwr, base-type=uint16, implementation-data-type=uint16, transfer-property=PENDING
          signal CAN3_HVBDrvPwrTotal: start 1, 18 bit, big-endian, i-signal-type=PRIMITIVE, init-value=constant-reference=Init_CAN3_HVBDrvPwrTotal, base-type=uint32, implementation-data-type=uint32, transfer-property=PENDING
          signal CAN3_HVBFullChrgPwr: start 153, 10 bit, big-endian, i-signal-type=PRIMITIVE, init-value=constant-reference=Init_CAN3_HVBFullChrgPwr, base-type=uint16, implementation-data-type=uint16, transfer-property=PENDING
          signal CAN3_HVBIsoImpedenceN: start 102, 15 bit, big-endian, i-signal-type=PRIMITIVE, init-value=constant-reference=Init_CAN3_HVBIsoImpedenceN, base-type=uint16, implementation-data-type=uint16, transfer-property=PENDING
          signal CAN3_HVBIsoImpedenceP: start 118, 15 bit, big-endian, i-signal-type=PRIMITIVE, init-value=constant-reference=Init_CAN3_HVBIsoImpedenceP, base-type=uint16, implementation-data-type=uint16, transfer-property=PENDING
          signal CAN3_HVBSOH: start 135, 8 bit, big-endian, i-signal-type=PRIMITIVE, init-value=constant-reference=Init_CAN3_HVBSOH, base-type=uint8, implementation-data-type=uint8, transfer-property=PENDING
          signal CAN3_HVBattErr: start 238, 1 bit, big-endian, i-signal-type=PRIMITIVE, init-value=constant-reference=Init_CAN3_HVBattErr, base-type=uint8, implementation-data-type=uint8, transfer-property=TRIGGERED-ON-CHANGE
          signal CAN3_HVBattPackVolt: start 204, 13 bit, big-endian, i-signal-type=PRIMITIVE, init-value=constant-reference=Init_CAN3_HVBattPackVolt, base-type=uint16, implementation-data-type=uint16, transfer-property=PENDING
          signal CAN3_HVBattSOC: start 223, 8 bit, big-endian, i-signal-type=PRIMITIVE, init-value=constant-reference=Init_CAN3_HVBattSOC, base-type=uint8, implementation-data-type=uint8, transfer-property=PENDING
          signal CAN3_HVBattSOCDis: start 231, 8 bit, big-endian, i-signal-type=PRIMITIVE, init-value=constant-reference=Init_CAN3_HVBattSOCDis, base-type=uint8, implementation-data-type=uint8, transfer-property=PENDING
          signal CAN3_RechrgCyc: start 65, 18 bit, big-endian, i-signal-type=PRIMITIVE, init-value=constant-reference=Init_CAN3_RechrgCyc, base-type=uint32, implementation-data-type=uint32, transfer-property=PENDING
          signal CAN3_RemainChrgTime: start 139, 12 bit, big-endian, i-signal-type=PRIMITIVE, init-value=constant-reference=Init_CAN3_RemainChrgTime, base-type=uint16, implementation-data-type=uint16, transfer-property=PENDING
      frame CAN3_BMS4: id 0x3E0, frame-length=48, can-addressing-mode=STANDARD, can-fd-frame-support=true, can-frame-rx-behavior=CAN-FD, can-frame-tx-behavior=CAN-FD
        pdu CAN3_BMS4: length=48, minimum-delay=0.0, transmission-mode-true-timing=cyclic-timing=time-period=0.1, unused-bit-pattern=0
          mapping CAN3_SG_BMS4: i-signal-group=CAN3_SG_BMS4, start-position=0, transfer-property=PENDING
          signal CAN3_CellTempAvg: start 351, 8 bit, big-endian, i-signal-type=PRIMITIVE, init-value=constant-reference=Init_CAN3_CellTempAvg, base-type=uint8, implementation-data-type=uint8, transfer-property=PENDING
          signal CAN3_HVBCellVoltMax: start 375, 16 bit, big-endian, i-signal-type=PRIMITIVE, init-value=constant-reference=Init_CAN3_HVBCellVoltMax, base-type=uint16, implementation-data-type=uint16, transfer-property=PENDING
          signal CAN3_HVBCellVoltMin: start 359, 16 bit, big-endian, i-signal-type=PRIMITIVE, init-value=constant-reference=Init_CAN3_HVBCellVoltMin, base-type=uint16, implementation-data-type=uint16, transfer-property=PENDING
          signal CAN3_HVBMTempMax: start 311, 8 bit, big-endian, i-signal-type=PRIMITIVE, init-value=constant-reference=Init_CAN3_HVBMTempMax, base-type=uint8, implementation-data-type=uint8, transfer-property=PENDING
          signal CAN3_HVBMTempMin: start 303, 8 bit, big-endian, i-signal-type=PRIMITIVE, init-value=constant-reference=Init_CAN3_HVBMTempMin, base-type=uint8, implementation-data-type=uint8, transfer-property=PENDING
          signal CAN3_MaxCellTemp_Num: start 327, 8 bit, big-endian, i-signal-type=PRIMITIVE, init-value=constant-reference=Init_CAN3_MaxCellTemp_Num, base-type=uint8, implementation-data-type=uint8, transfer-property=PENDING
          signal CAN3_MaxCellVolt_Num: start 343, 8 bit, big-endian, i-signal-type=PRIMITIVE, init-value=constant-reference=Init_CAN3_MaxCellVolt_Num, base-type=uint8, implementation-data-type=uint8, transfer-property=PENDING
          signal CAN3_MinCellTemp_Num: start 319, 8 bit, big-endian, i-signal-type=PRIMITIVE, init-value=constant-reference=Init_CAN3_MinCellTemp_Num, base-type=uint8, implementation-data-type=uint8, transfer-property=PENDING
          signal CAN3_MinCellVolt_Num: start 335, 8 bit, big-endian, i-signal-type=PRIMITIVE, init-value=constant-reference=Init_CAN3_MinCellVolt_Num, base-type=uint8, implementation-data-type=uint8, transfer-property=PENDING
          signal CAN3_Mtemp01: start 119, 8 bit, big-endian, i-signal-type=PRIMITIVE, init-value=constant-reference=Init_CAN3_Mtemp01, base-type=uint8, implementation-data-type=uint8, transfer-property=PENDING
          signal CAN3_Mtemp02: start 111, 8 bit, big-endian, i-signal-type=PRIMITIVE, init-value=constant-reference=Init_CAN3_Mtemp02, base-type=uint8, implementation-data-type=uint8, transfer-property=PENDING
          signal CAN3_Mtemp03: start 103, 8 bit, big-endian, i-signal-type=PRIMITIVE, init-value=constant-reference=Init_CAN3_Mtemp03, base-type=uint8, implementation-data-type=uint8, transfer-property=PENDING
          signal CAN3_Mtemp04: start 95, 8 bit, big-endian, i-signal-type=PRIMITIVE, init-value=constant-reference=Init_CAN3_Mtemp04, base-type=uint8, implementation-data-type=uint8, transfer-property=PENDING
          signal CAN3_Mtemp05: start 87, 8 bit, big-endian, i-signal-type=PRIMITIVE, init-value=constant-reference=Init_CAN3_Mtemp05, base-type=uint8, implementation-data-type=uint8, transfer-property=PENDING
          signal CAN3_Mtemp06: start 79, 8 bit, big-endian, i-signal-type=PRIMITIVE, init-value=constant-reference=Init_CAN3_Mtemp06, base-type=uint8, implementation-data-type=uint8, transfer-property=PENDING
          signal CAN3_Mtemp07: start 71, 8 bit, big-endian, i-signal-type=PRIMITIVE, init-value=constant-reference=Init_CAN3_Mtemp07, base-type=uint8, implementation-data-type=uint8, transfer-property=PENDING
          signal CAN3_Mtemp08: start 63, 8 bit, big-endian, i-signal-type=PRIMITIVE, init-value=constant-reference=Init_CAN3_Mtemp08, base-type=uint8, implementation-data-type=uint8, transfer-property=PENDING
          signal CAN3_Mtemp09: start 55, 8 bit, big-endian, i-signal-type=PRIMITIVE, init-value=constant-reference=Init_CAN3_Mtemp09, base-type=uint8, implementation-data-type=uint8, transfer-property=PENDING
          signal CAN3_Mtemp10: start 47, 8 bit, big-endian, i-signal-type=PRIMITIVE, init-value=constant-reference=Init_CAN3_Mtemp10, base-type=uint8, implementation-data-type=uint8, transfer-property=PENDING
          signal CAN3_Mtemp11: start 39, 8 bit, big-endian, i-signal-type=PRIMITIVE, init-value=constant-reference=Init_CAN3_Mtemp11, base-type=uint8, implementation-data-type=uint8, transfer-property=PENDING
          signal CAN3_Mtemp12: start 31, 8 bit, big-endian, i-signal-type=PRIMITIVE, init-value=constant-reference=Init_CAN3_Mtemp12, base-type=uint8, implementation-data-type=uint8, transfer-property=PENDING
          signal CAN3_Mtemp13: start 23, 8 bit, big-endian, i-signal-type=PRIMITIVE, init-value=constant-reference=Init_CAN3_Mtemp13, base-type=uint8, implementation-data-type=uint8, transfer-property=PENDING
          signal CAN3_Mtemp14: start 15, 8 bit, big-endian, i-signal-type=PRIMITIVE, init-value=constant-reference=Init_CAN3_Mtemp14, base-type=uint8, implementation-data-type=uint8, transfer-property=PENDING
          signal CAN3_Mtemp15: start 7, 8 bit, big-endian, i-signal-type=PRIMITIVE, init-value=constant-reference=Init_CAN3_Mtemp15, base-type=uint8, implementation-data-type=uint8, transfer-property=PENDING
          signal CAN3_Mtemp16: start 159, 8 bit, big-endian, i-signal-type=PRIMITIVE, init-value=constant-reference=Init_CAN3_Mtemp16, base-type=uint8, implementation-data-type=uint8, transfer-property=PENDING
          signal CAN3_Mtemp17: start 151, 8 bit, big-endian, i-signal-type=PRIMITIVE, init-value=constant-reference=Init_CAN3_Mtemp17, base-type=uint8, implementation-data-type=uint8, transfer-property=PENDING
          signal CAN3_Mtemp18: start 143, 8 bit, big-endian, i-signal-type=PRIMITIVE, init-value=constant-reference=Init_CAN3_Mtemp18, base-type=uint8, implementation-data-type=uint8, transfer-property=PENDING
          signal CAN3_Mtemp19: start 135, 8 bit, big-endian, i-signal-type=PRIMITIVE, init-value=constant-reference=Init_CAN3_Mtemp19, base-type=uint8, implementation-data-type=uint8, transfer-property=PENDING
          signal CAN3_Mtemp20: start 127, 8 bit, big-endian, i-signal-type=PRIMITIVE, init-value=constant-reference=Init_CAN3_Mtemp20, base-type=uint8, implementation-data-type=uint8, transfer-property=PENDING
      frame CAN3_BMS5: id 0x276, frame-length=12, can-addressing-mode=STANDARD, can-fd-frame-support=true, can-frame-rx-behavior=CAN-FD, can-frame-tx-behavior=CAN-FD
        pdu CAN3_BMS5: length=12, minimum-delay=0.0, transmission-mode-true-timing={cyclic-timing=time-period=0.1, event-controlled-timing={number-of-repetitions=0, repetition-period=0}}, unused-bit-pattern=0
          mapping CAN3_SG_BMS5: i-signal-group=CAN3_SG_BMS5, start-position=0, transfer-property=TRIGGERED-ON-CHANGE
          signal CAN3_DCPortNeg_Temp: start 7, 8 bit, big-endian, i-signal-type=PRIMITIVE, init-value=constant-reference=Init_CAN3_DCPortNeg_Temp, base-type=uint8, implementation-data-type=uint8, transfer-property=PENDING
          signal CAN3_DCPortPos_Temp: start 15, 8 bit, big-endian, i-signal-type=PRIMITIVE, init-value=constant-reference=Init_CAN3_DCPortPos_Temp, base-type=uint8, implementation-data-type=uint8, transfer-property=PENDING
          signal CAN3_HVInVolt: start 28, 13 bit, big-endian, i-signal-type=PRIMITIVE, init-value=constant-reference=Init_CAN3_HVInVolt, base-type=uint16, implementation-data-type=uint16, transfer-property=PENDING
          signal CAN3_LVBattDet12V: start 79, 8 bit, big-endian, i-signal-type=PRIMITIVE, init-value=constant-reference=Init_CAN3_LVBattDet12V, base-type=uint8, implementation-data-type=uint8, transfer-property=PENDING
          signal CAN3_OBCACCSLimit: start 23, 8 bit, big-endian, i-signal-type=PRIMITIVE, init-value=constant-reference=Init_CAN3_OBCACCSLimit, base-type=uint8, implementation-data-type=uint8, transfer-property=TRIGGERED-ON-CHANGE
          signal CAN3_OBCDCCurLm: start 57, 10 bit, big-endian, i-signal-type=PRIMITIVE, init-value=constant-reference=Init_CAN3_OBCDCCurLm, base-type=uint16, implementation-data-type=uint16, transfer-property=PENDING
          signal CAN3_OBCDCVoltLm: start 44, 13 bit, big-endian, i-signal-type=PRIMITIVE, init-value=constant-reference=Init_CAN3_OBCDCVoltLm, base-type=uint16, implementation-data-type=uint16, transfer-property=PENDING
          signal CAN3_OBCEna: start 60, 1 bit, big-endian, i-signal-type=PRIMITIVE, init-value=constant-reference=Init_CAN3_OBCEna, base-type=uint8, implementation-data-type=uint8, transfer-property=TRIGGERED-ON-CHANGE
          signal CAN3_ReChargerStaFromEvcc: start 59, 2 bit, big-endian, i-signal-type=PRIMITIVE, init-value=constant-reference=Init_CAN3_ReChargerStaFromEvcc, base-type=uint8, implementation-data-type=uint8, transfer-property=TRIGGERED-ON-CHANGE
      frame CAN3_BMS6: id 0x17A, frame-length=12, can-addressing-mode=STANDARD, can-fd-frame-support=true, can-frame-rx-behavior=CAN-FD, can-frame-tx-behavior=CAN-FD
        pdu CAN3_BMS6: length=12, minimum-delay=0.0, transmission-mode-true-timing={cyclic-timing=time-period=0.1, event-controlled-timing={number-of-repetitions=0, repetition-period=0}}, unused-bit-pattern=0
          mapping CAN3_SG_BMS6: i-signal-group=CAN3_SG_BMS6, start-position=0, transfer-property=TRIGGERED-ON-CHANGE
          signal CAN3_BMSChckSum: start 7, 8 bit, big-endian, i-signal-type=PRIMITIVE, init-value=constant-reference=Init_CAN3_BMSChckSum, base-type=uint8, implementation-data-type=uint8, transfer-property=PENDING
          signal CAN3_BMSRolCnct: start 11, 4 bit, big-endian, i-signal-type=PRIMITIVE, init-value=constant-reference=Init_CAN3_BMSRolCnct, base-type=uint8, implementation-data-type=uint8, transfer-property=PENDING
          signal CAN3_BMS_READY: start 65, 1 bit, big-endian, i-signal-type=PRIMITIVE, init-value=constant-reference=Init_CAN3_BMS_READY, base-type=uint8, implementation-data-type=uint8, transfer-property=TRIGGERED-ON-CHANGE
          signal CAN3_BMS_Warn_1: start 88, 1 bit, big-endian, i-signal-type=PRIMITIVE, init-value=constant-reference=Init_CAN3_BMS_Warn_1, base-type=uint8, implementation-data-type=uint8, transfer-property=TRIGGERED-ON-CHANGE
          signal CAN3_BMS_Warn_2: start 89, 1 bit, big-endian, i-signal-type=PRIMITIVE, init-value=constant-reference=Init_CAN3_BMS_Warn_2, base-type=uint8, implementation-data-type=uint8, transfer-property=TRIGGERED-ON-CHANGE
          signal CAN3_BMS_Warn_3: start 90, 1 bit, big-endian, i-signal-type=PRIMITIVE, init-value=constant-reference=Init_CAN3_BMS_Warn_3, base-type=uint8, implementation-data-type=uint8, transfer-property=TRIGGERED-ON-CHANGE
          signal CAN3_BMS_Warn_4: start 91, 1 bit, big-endian, i-signal-type=PRIMITIVE, init-value=constant-reference=Init_CAN3_BMS_Warn_4, base-type=uint8, implementation-data-type=uint8, transfer-property=TRIGGERED-ON-CHANGE
          signal CAN3_BMS_Warn_5: start 92, 1 bit, big-endian, i-signal-type=PRIMITIVE, init-value=constant-reference=Init_CAN3_BMS_Warn_5, base-type=uint8, implementation-data-type=uint8, transfer-property=TRIGGERED-ON-CHANGE
          signal CAN3_BMS_Warn_6: start 93, 1 bit, big-endian, i-signal-type=PRIMITIVE, init-value=constant-reference=Init_CAN3_BMS_Warn_6, base-type=uint8, implementation-data-type=uint8, transfer-property=TRIGGERED-ON-CHANGE
          signal CAN3_BMS_Warn_7: start 94, 1 bit, big-endian, i-signal-type=PRIMITIVE, init-value=constant-reference=Init_CAN3_BMS_Warn_7, base-type=uint8, implementation-data-type=uint8, transfer-property=TRIGGERED-ON-CHANGE
          signal CAN3_BMS_Warn_8: start 95, 1 bit, big-endian, i-signal-type=PRIMITIVE, init-value=constant-reference=Init_CAN3_BMS_Warn_8, base-type=uint8, implementation-data-type=uint8, transfer-property=TRIGGERED-ON-CHANGE
          signal CAN3_CellUnconsistErr: start 50, 1 bit, big-endian, i-signal-type=PRIMITIVE, init-value=constant-reference=Init_CAN3_CellUnconsistErr, base-type=uint8, implementation-data-type=uint8, transfer-property=TRIGGERED-ON-CHANGE
          signal CAN3_ChrgInLockReq: start 45, 2 bit, big-endian, i-signal-type=PRIMITIVE, init-value=constant-reference=Init_CAN3_ChrgInLockReq, base-type=uint8, implementation-data-type=uint8, transfer-property=TRIGGERED-ON-CHANGE
          signal CAN3_ChrgPlugSta: start 59, 2 bit, big-endian, i-signal-type=PRIMITIVE, init-value=constant-reference=Init_CAN3_ChrgPlugSta, base-type=uint8, implementation-data-type=uint8, transfer-property=TRIGGERED-ON-CHANGE
          signal CAN3_DCChrgSysShockErr: start 64, 1 bit, big-endian, i-signal-type=PRIMITIVE, init-value=constant-reference=Init_CAN3_DCChrgSysShockErr, base-type=uint8, implementation-data-type=uint8, transfer-property=TRIGGERED-ON-CHANGE
          signal CAN3_DisChrgPlugErr: start 47, 2 bit, big-endian, i-signal-type=PRIMITIVE, init-value=constant-reference=Init_CAN3_DisChrgPlugErr, base-type=uint8, implementation-data-type=uint8, transfer-property=TRIGGERED-ON-CHANGE
          signal CAN3_ExtChrgSta: start 61, 2 bit, big-endian, i-signal-type=PRIMITIVE, init-value=constant-reference=Init_CAN3_ExtChrgSta, base-type=uint8, implementation-data-type=uint8, transfer-property=TRIGGERED-ON-CHANGE
          signal CAN3_HVBCellOvrVoltErr: start 40, 1 bit, big-endian, i-signal-type=PRIMITIVE, init-value=constant-reference=Init_CAN3_HVBCellOvrVoltErr, base-type=uint8, implementation-data-type=uint8, transfer-property=TRIGGERED-ON-CHANGE
          signal CAN3_HVBCellOvrVoltWarn: start 53, 2 bit, big-endian, i-signal-type=PRIMITIVE, init-value=constant-reference=Init_CAN3_HVBCellOvrVoltWarn, base-type=uint8, implementation-data-type=uint8, transfer-property=TRIGGERED-ON-CHANGE
          signal CAN3_HVBCellUdrVoltWarn: start 55, 2 bit, big-endian, i-signal-type=PRIMITIVE, init-value=constant-reference=Init_CAN3_HVBCellUdrVoltWarn, base-type=uint8, implementation-data-type=uint8, transfer-property=TRIGGERED-ON-CHANGE
          signal CAN3_HVBCellUnbalanErr: start 42, 1 bit, big-endian, i-signal-type=PRIMITIVE, init-value=constant-reference=Init_CAN3_HVBCellUnbalanErr, base-type=uint8, implementation-data-type=uint8, transfer-property=TRIGGERED-ON-CHANGE
          signal CAN3_HVBCellUndrVoltErr: start 41, 1 bit, big-endian, i-signal-type=PRIMITIVE, init-value=constant-reference=Init_CAN3_HVBCellUndrVoltErr, base-type=uint8, implementation-data-type=uint8, transfer-property=TRIGGERED-ON-CHANGE
          signal CAN3_HVBChrgErr: start 39, 8 bit, big-endian, i-signal-type=PRIMITIVE, init-value=constant-reference=Init_CAN3_HVBChrgErr, base-type=uint8, implementation-data-type=uint8, transfer-property=TRIGGERED-ON-CHANGE
          signal CAN3_HVBContactorSta: start 66, 1 bit, big-endian, i-signal-type=PRIMITIVE, init-value=constant-reference=Init_CAN3_HVBContactorSta, base-type=uint8, implementation-data-type=uint8, transfer-property=TRIGGERED-ON-CHANGE
          signal CAN3_HVBHVILErr: start 79, 1 bit, big-endian, i-signal-type=PRIMITIVE, init-value=constant-reference=Init_CAN3_HVBHVILErr, base-type=uint8, implementation-data-type=uint8, transfer-property=TRIGGERED-ON-CHANGE
          signal CAN3_HVBOvrChrgCurrErr: start 72, 1 bit, big-endian, i-signal-type=PRIMITIVE, init-value=constant-reference=Init_CAN3_HVBOvrChrgCurrErr, base-type=uint8, implementation-data-type=uint8, transfer-property=TRIGGERED-ON-CHANGE
          signal CAN3_HVBOvrDchrgCurErr: start 73, 1 bit, big-endian, i-signal-type=PRIMITIVE, init-value=constant-reference=Init_CAN3_HVBOvrDchrgCurErr, base-type=uint8, implementation-data-type=uint8, transfer-property=TRIGGERED-ON-CHANGE
          signal CAN3_HVBOvrSOCErr: start 76, 1 bit, big-endian, i-signal-type=PRIMITIVE, init-value=constant-reference=Init_CAN3_HVBOvrSOCErr, base-type=uint8, implementation-data-type=uint8, transfer-property=TRIGGERED-ON-CHANGE
          signal CAN3_HVBOvrTempErr: start 74, 1 bit, big-endian, i-signal-type=PRIMITIVE, init-value=constant-reference=Init_CAN3_HVBOvrTempErr, base-type=uint8, implementation-data-type=uint8, transfer-property=TRIGGERED-ON-CHANGE
          signal CAN3_HVBOvrTempWarn: start 81, 2 bit, big-endian, i-signal-type=PRIMITIVE, init-value=constant-reference=Init_CAN3_HVBOvrTempWarn, base-type=uint8, implementation-data-type=uint8, transfer-property=TRIGGERED-ON-CHANGE
          signal CAN3_HVBOvrVoltErr: start 84, 1 bit, big-endian, i-signal-type=PRIMITIVE, init-value=constant-reference=Init_CAN3_HVBOvrVoltErr, base-type=uint8, implementation-data-type=uint8, transfer-property=TRIGGERED-ON-CHANGE
          signal CAN3_HVBPrechrgSta: start 69, 2 bit, big-endian, i-signal-type=PRIMITIVE, init-value=constant-reference=Init_CAN3_HVBPrechrgSta, base-type=uint8, implementation-data-type=uint8, transfer-property=TRIGGERED-ON-CHANGE
          signal CAN3_HVBPreheatPrecoolSta: start 63, 2 bit, big-endian, i-signal-type=PRIMITIVE, init-value=constant-reference=Init_CAN3_HVBPreheatPrecoolSta, base-type=uint8, implementation-data-type=uint8, transfer-property=TRIGGERED-ON-CHANGE
          signal CAN3_HVBSOCJumpError: start 78, 1 bit, big-endian, i-signal-type=PRIMITIVE, init-value=constant-reference=Init_CAN3_HVBSOCJumpError, base-type=uint8, implementation-data-type=uint8, transfer-property=TRIGGERED-ON-CHANGE
          signal CAN3_HVBShrtChrgCurrErr: start 86, 1 bit, big-endian, i-signal-type=PRIMITIVE, init-value=constant-reference=Init_CAN3_HVBShrtChrgCurrErr, base-type=uint8, implementation-data-type=uint8, transfer-property=TRIGGERED-ON-CHANGE
          signal CAN3_HVBShrtDischrgCurrErr: start 87, 1 bit, big-endian, i-signal-type=PRIMITIVE, init-value=constant-reference=Init_CAN3_HVBShrtDischrgCurrErr, base-type=uint8, implementation-data-type=uint8, transfer-property=TRIGGERED-ON-CHANGE
          signal CAN3_HVBTempDiffErr: start 70, 1 bit, big-endian, i-signal-type=PRIMITIVE, init-value=constant-reference=Init_CAN3_HVBTempDiffErr, base-type=uint8, implementation-data-type=uint8, transfer-property=TRIGGERED-ON-CHANGE
          signal CAN3_HVBUndrSOCErr: start 77, 1 bit, big-endian, i-signal-type=PRIMITIVE, init-value=constant-reference=Init_CAN3_HVBUndrSOCErr, base-type=uint8, implementation-data-type=uint8, transfer-property=TRIGGERED-ON-CHANGE
          signal CAN3_HVBUndrTempErr: start 75, 1 bit, big-endian, i-signal-type=PRIMITIVE, init-value=constant-reference=Init_CAN3_HVBUndrTempErr, base-type=uint8, implementation-data-type=uint8, transfer-property=TRIGGERED-ON-CHANGE
          signal CAN3_HVBUndrTempWarn: start 83, 2 bit, big-endian, i-signal-type=PRIMITIVE, init-value=constant-reference=Init_CAN3_HVBUndrTempWarn, base-type=uint8, implementation-data-type=uint8, transfer-property=TRIGGERED-ON-CHANGE
          signal CAN3_HVBUndrVoltErr: start 85, 1 bit, big-endian, i-signal-type=PRIMITIVE, init-value=constant-reference=Init_CAN3_HVBUndrVoltErr, base-type=uint8, implementation-data-type=uint8, transfer-property=TRIGGERED-ON-CHANGE
          signal CAN3_HVBattReady4Pre: start 57, 2 bit, big-endian, i-signal-type=PRIMITIVE, init-value=constant-reference=Init_CAN3_HVBattReady4Pre, base-type=uint8, implementation-data-type=uint8, transfer-property=TRIGGERED-ON-CHANGE
          signal CAN3_HVILSta: start 71, 1 bit, big-endian, i-signal-type=PRIMITIVE, init-value=constant-reference=Init_CAN3_HVILSta, base-type=uint8, implementation-data-type=uint8, transfer-property=TRIGGERED-ON-CHANGE
          signal CAN3_IsoDetSta: start 48, 1 bit, big-endian, i-signal-type=PRIMITIVE, init-value=constant-reference=Init_CAN3_IsoDetSta, base-type=uint8, implementation-data-type=uint8, transfer-property=TRIGGERED-ON-CHANGE
          signal CAN3_SystemUncomErr: start 49, 1 bit, big-endian, i-signal-type=PRIMITIVE, init-value=constant-reference=Init_CAN3_SystemUncomErr, base-type=uint8, implementation-data-type=uint8, transfer-property=TRIGGERED-ON-CHANGE
          signal CAN3_V2LSta: start 25, 2 bit, big-endian, i-signal-type=PRIMITIVE, init-value=constant-reference=Init_CAN3_V2LSta, base-type=uint8, implementation-data-type=uint8, transfer-property=TRIGGERED-ON-CHANGE
      frame CAN3_BMS8: id 0x334, frame-length=48, can-addressing-mode=STANDARD, can-fd-frame-support=true, can-frame-rx-behavior=CAN-FD, can-frame-tx-behavior=CAN-FD
        pdu CAN3_BMS8: length=48, minimum-delay=0.0, transmission-mode-true-timing=cyclic-timing=time-period=0.1, unused-bit-pattern=0
          mapping CAN3_SG_BMS8: i-signal-group=CAN3_SG_BMS8, start-position=0, transfer-property=PENDING
          signal CAN3_ACChrgStop: start 31, 8 bit, big-endian, i-signal-type=PRIMITIVE, init-value=constant-reference=Init_CAN3_ACChrgStop, base-type=uint8, implementation-data-type=uint8, transfer-property=PENDING
          signal CAN3_CurrentErrorID: start 7, 16 bit, big-endian, i-signal-type=PRIMITIVE, init-value=constant-reference=Init_CAN3_CurrentErrorID, base-type=uint16, implementation-data-type=uint16, transfer-property=PENDING
          signal CAN3_DCChrgCurrent: start 55, 32 bit, big-endian, i-signal-type=PRIMITIVE, init-value=constant-reference=Init_CAN3_DCChrgCurrent, base-type=uint32, implementation-data-type=uint32, transfer-property=PENDING
          signal CAN3_DCChrgStop: start 23, 8 bit, big-endian, i-signal-type=PRIMITIVE, init-value=constant-reference=Init_CAN3_DCChrgStop, base-type=uint8, implementation-data-type=uint8, transfer-property=PENDING
          signal CAN3_DCChrgVoltage: start 39, 16 bit, big-endian, i-signal-type=PRIMITIVE, init-value=constant-reference=Init_CAN3_DCChrgVoltage, base-type=uint16, implementation-data-type=uint16, transfer-property=PENDING
          signal CAN3_G0standard: start 215, 16 bit, big-endian, i-signal-type=PRIMITIVE, init-value=constant-reference=Init_CAN3_G0standard, base-type=uint16, implementation-data-type=uint16, transfer-property=PENDING
          signal CAN3_MainChrgRlyNegDriReq: start 143, 8 bit, big-endian, i-signal-type=PRIMITIVE, init-value=constant-reference=Init_CAN3_MainChrgRlyNegDriReq, base-type=uint8, implementation-data-type=uint8, transfer-property=PENDING
          signal CAN3_MainChrgRlyNegOutterVoltage: start 263, 16 bit, big-endian, i-signal-type=PRIMITIVE, init-value=constant-reference=Init_CAN3_MainChrgRlyNegOutterVoltage, base-type=uint16, implementation-data-type=uint16, transfer-property=PENDING
          signal CAN3_MainChrgRlyNegSta: start 167, 8 bit, big-endian, i-signal-type=PRIMITIVE, init-value=constant-reference=Init_CAN3_MainChrgRlyNegSta, base-type=uint8, implementation-data-type=uint8, transfer-property=PENDING
          signal CAN3_MainChrgRlyPosDriReq: start 135, 8 bit, big-endian, i-signal-type=PRIMITIVE, init-value=constant-reference=Init_CAN3_MainChrgRlyPosDriReq, base-type=uint8, implementation-data-type=uint8, transfer-property=PENDING
          signal CAN3_MainChrgRlyPosOutterVoltage: start 247, 16 bit, big-endian, i-signal-type=PRIMITIVE, init-value=constant-reference=Init_CAN3_MainChrgRlyPosOutterVoltage, base-type=uint16, implementation-data-type=uint16, transfer-property=PENDING
          signal CAN3_MainChrgRlyPosSta: start 175, 8 bit, big-endian, i-signal-type=PRIMITIVE, init-value=constant-reference=Init_CAN3_MainChrgRlyPosSta, base-type=uint8, implementation-data-type=uint8, transfer-property=PENDING
          signal CAN3_MainPosstandard: start 279, 16 bit, big-endian, i-signal-type=PRIMITIVE, init-value=constant-reference=Init_CAN3_MainPosstandard, base-type=uint16, implementation-data-type=uint16, transfer-property=PENDING
          signal CAN3_MainRlyNegDriReq: start 127, 8 bit, big-endian, i-signal-type=PRIMITIVE, init-value=constant-reference=Init_CAN3_MainRlyNegDriReq, base-type=uint8, implementation-data-type=uint8, transfer-property=PENDING
          signal CAN3_MainRlyNegOutterVoltage: start 231, 16 bit, big-endian, i-signal-type=PRIMITIVE, init-value=constant-reference=Init_CAN3_MainRlyNegOutterVoltage, base-type=uint16, implementation-data-type=uint16, transfer-property=PENDING
          signal CAN3_MainRlyNegSta: start 159, 8 bit, big-endian, i-signal-type=PRIMITIVE, init-value=constant-reference=Init_CAN3_MainRlyNegSta, base-type=uint8, implementation-data-type=uint8, transfer-property=PENDING
          signal CAN3_MainRlyPosDriReq: start 119, 8 bit, big-endian, i-signal-type=PRIMITIVE, init-value=constant-reference=Init_CAN3_MainRlyPosDriReq, base-type=uint8, implementation-data-type=uint8, transfer-property=PENDING
          signal CAN3_MainRlyPosInnerVoltage: start 183, 16 bit, big-endian, i-signal-type=PRIMITIVE, init-value=constant-reference=Init_CAN3_MainRlyPosInnerVoltage, base-type=uint16, implementation-data-type=uint16, transfer-property=PENDING
          signal CAN3_MainRlyPosOutterVoltage: start 199, 16 bit, big-endian, i-signal-type=PRIMITIVE, init-value=constant-reference=Init_CAN3_MainRlyPosOutterVoltage, base-type=uint16, implementation-data-type=uint16, transfer-property=PENDING
          signal CAN3_MainRlyPosSta: start 151, 8 bit, big-endian, i-signal-type=PRIMITIVE, init-value=constant-reference=Init_CAN3_MainRlyPosSta, base-type=uint8, implementation-data-type=uint8, transfer-property=PENDING
          signal CAN3_TherRunawayErrMask: start 87, 32 bit, big-endian, i-signal-type=PRIMITIVE, init-value=constant-reference=Init_CAN3_TherRunawayErrMask, base-type=uint32, implementation-data-type=uint32, transfer-property=PENDING
      frame CAN3_CCU1: id 0x185, frame-length=12, can-addressing-mode=STANDARD, can-fd-frame-support=true, can-frame-rx-behavior=CAN-FD, can-frame-tx-behavior=CAN-FD
        pdu CAN3_CCU1: length=12, minimum-delay=0.0, transmission-mode-true-timing={cyclic-timing=time-period=0.01, event-controlled-timing={number-of-repetitions=0, repetition-period=0}}, unused-bit-pattern=0
          mapping CAN3_SG_CCU1: i-signal-group=CAN3_SG_CCU1, start-position=0, transfer-property=TRIGGERED-ON-CHANGE
          signal CAN3_CS_CCU1: start 7, 8 bit, big-endian, i-signal-type=PRIMITIVE, init-value=constant-reference=Init_CAN3_CS_CCU1, base-type=uint8, implementation-data-type=uint8, transfer-property=PENDING
          signal CAN3_DCDCAuxCur: start 87, 12 bit, big-endian, i-signal-type=PRIMITIVE, init-value=constant-reference=Init_CAN3_DCDCAuxCur, base-type=uint16, implementation-data-type=uint16, transfer-property=PENDING
          signal CAN3_DCDCAuxVolt: start 48, 8 bit, big-endian, i-signal-type=PRIMITIVE, init-value=constant-reference=Init_CAN3_DCDCAuxVolt, base-type=uint8, implementation-data-type=uint8, transfer-property=PENDING
          signal CAN3_DCDCHVCur: start 65, 10 bit, big-endian, i-signal-type=PRIMITIVE, init-value=constant-reference=Init_CAN3_DCDCHVCur, base-type=uint16, implementation-data-type=uint16, transfer-property=PENDING
          signal CAN3_DCDCInVoltInf: start 44, 12 bit, big-endian, i-signal-type=PRIMITIVE, init-value=constant-reference=Init_CAN3_DCDCInVoltInf, base-type=uint16, implementation-data-type=uint16, transfer-property=PENDING
          signal CAN3_DCDCPreCompleted: start 46, 2 bit, big-endian, i-signal-type=PRIMITIVE, init-value=constant-reference=Init_CAN3_DCDCPreCompleted, base-type=uint8, implementation-data-type=uint8, transfer-property=PENDING
          signal CAN3_OBCDCCurrInf: start 26, 10 bit, big-endian, i-signal-type=PRIMITIVE, init-value=constant-reference=Init_CAN3_OBCDCCurrInf, base-type=uint16, implementation-data-type=uint16, transfer-property=PENDING
          signal CAN3_OBCDCVoltInf: start 23, 12 bit, big-endian, i-signal-type=PRIMITIVE, init-value=constant-reference=Init_CAN3_OBCDCVoltInf, base-type=uint16, implementation-data-type=uint16, transfer-property=PENDING
          signal CAN3_OBCPreCompleted: start 32, 2 bit, big-endian, i-signal-type=PRIMITIVE, init-value=constant-reference=Init_CAN3_OBCPreCompleted, base-type=uint8, implementation-data-type=uint8, transfer-property=PENDING
          signal CAN3_OBCV2LINVOTP: start 68, 1 bit, big-endian, i-signal-type=PRIMITIVE, init-value=constant-reference=Init_CAN3_OBCV2LINVOTP, base-type=uint8, implementation-data-type=uint8, transfer-property=TRIGGERED-ON-CHANGE
          signal CAN3_OBCV2LInsuFault: start 69, 1 bit, big-endian, i-signal-type=PRIMITIVE, init-value=constant-reference=Init_CAN3_OBCV2LInsuFault, base-type=uint8, implementation-data-type=uint8, transfer-property=TRIGGERED-ON-CHANGE
          signal CAN3_OBCV2LVinOVP: start 67, 1 bit, big-endian, i-signal-type=PRIMITIVE, init-value=constant-reference=Init_CAN3_OBCV2LVinOVP, base-type=uint8, implementation-data-type=uint8, transfer-property=PENDING
          signal CAN3_OBCV2LVinUVP: start 66, 1 bit, big-endian, i-signal-type=PRIMITIVE, init-value=constant-reference=Init_CAN3_OBCV2LVinUVP, base-type=uint8, implementation-data-type=uint8, transfer-property=PENDING
          signal CAN3_OBCV2LVoutOCP: start 70, 1 bit, big-endian, i-signal-type=PRIMITIVE, init-value=constant-reference=Init_CAN3_OBCV2LVoutOCP, base-type=uint8, implementation-data-type=uint8, transfer-property=TRIGGERED-ON-CHANGE
          signal CAN3_OBCV2LVoutOVP: start 71, 1 bit, big-endian, i-signal-type=PRIMITIVE, init-value=constant-reference=Init_CAN3_OBCV2LVoutOVP, base-type=uint8, implementation-data-type=uint8, transfer-property=TRIGGERED-ON-CHANGE
          signal CAN3_OBCV2LVoutUVP: start 56, 1 bit, big-endian, i-signal-type=PRIMITIVE, init-value=constant-reference=Init_CAN3_OBCV2LVoutUVP, base-type=uint8, implementation-data-type=uint8, transfer-property=TRIGGERED-ON-CHANGE
          signal CAN3_OBCWakeup4Plugin: start 27, 1 bit, big-endian, i-signal-type=PRIMITIVE, init-value=constant-reference=Init_CAN3_OBCWakeup4Plugin, base-type=uint8, implementation-data-type=uint8, transfer-property=PENDING
          signal CAN3_RC_CCU1: start 11, 4 bit, big-endian, i-signal-type=PRIMITIVE, init-value=constant-reference=Init_CAN3_RC_CCU1, base-type=uint8, implementation-data-type=uint8, transfer-property=PENDING
      frame CAN3_CCU2: id 0x1D6, frame-length=12, can-addressing-mode=STANDARD, can-fd-frame-support=true, can-frame-rx-behavior=CAN-FD, can-frame-tx-behavior=CAN-FD
        pdu CAN3_CCU2: length=12, minimum-delay=0.0, transmission-mode-true-timing={cyclic-timing=time-period=0.1, event-controlled-timing={number-of-repetitions=0, repetition-period=0}}, unused-bit-pattern=0
          mapping CAN3_SG_CCU2: i-signal-group=CAN3_SG_CCU2, start-position=0, transfer-property=TRIGGERED-ON-CHANGE
          signal CAN3_CS_CCU2: start 7, 8 bit, big-endian, i-signal-type=PRIMITIVE, init-value=constant-reference=Init_CAN3_CS_CCU2, base-type=uint8, implementation-data-type=uint8, transfer-property=PENDING
          signal CAN3_DCDCEnaSta: start 58, 1 bit, big-endian, i-signal-type=PRIMITIVE, init-value=constant-reference=Init_CAN3_DCDCEnaSta, base-type=uint8, implementation-data-type=uint8, transfer-property=TRIGGERED-ON-CHANGE
          signal CAN3_DCDCFaultSta: start 91, 2 bit, big-endian, i-signal-type=PRIMITIVE, init-value=constant-reference=Init_CAN3_DCDCFaultSta, base-type=uint8, implementation-data-type=uint8, transfer-property=TRIGGERED-ON-CHANGE
          signal CAN3_DCDCReady4Pre: start 93, 1 bit, big-endian, i-signal-type=PRIMITIVE, init-value=constant-reference=Init_CAN3_DCDCReady4Pre, base-type=uint8, implementation-data-type=uint8, transfer-property=TRIGGERED-ON-CHANGE
          signal CAN3_DCDCTemp: start 79, 8 bit, big-endian, i-signal-type=PRIMITIVE, init-value=constant-reference=Init_CAN3_DCDCTemp, base-type=uint8, implementation-data-type=uint8, transfer-property=TRIGGERED-ON-CHANGE
          signal CAN3_OBCACCurrInf: start 55, 10 bit, big-endian, i-signal-type=PRIMITIVE, init-value=constant-reference=Init_CAN3_OBCACCurrInf, base-type=uint16, implementation-data-type=uint16, transfer-property=PENDING
          signal CAN3_OBCACVoltInf: start 35, 12 bit, big-endian, i-signal-type=PRIMITIVE, init-value=constant-reference=Init_CAN3_OBCACVoltInf, base-type=uint16, implementation-data-type=uint16, transfer-property=PENDING
          signal CAN3_OBCDCP: start 57, 10 bit, big-endian, i-signal-type=PRIMITIVE, init-value=constant-reference=Init_CAN3_OBCDCP, base-type=uint16, implementation-data-type=uint16, transfer-property=PENDING
          signal CAN3_OBCEnaSta: start 60, 1 bit, big-endian, i-signal-type=PRIMITIVE, init-value=constant-reference=Init_CAN3_OBCEnaSta, base-type=uint8, implementation-data-type=uint8, transfer-property=TRIGGERED-ON-CHANGE
          signal CAN3_OBCFaultSta: start 89, 2 bit, big-endian, i-signal-type=PRIMITIVE, init-value=constant-reference=Init_CAN3_OBCFaultSta, base-type=uint8, implementation-data-type=uint8, transfer-property=TRIGGERED-ON-CHANGE
          signal CAN3_OBCPluginSta: start 59, 1 bit, big-endian, i-signal-type=PRIMITIVE, init-value=constant-reference=Init_CAN3_OBCPluginSta, base-type=uint8, implementation-data-type=uint8, transfer-property=PENDING
          signal CAN3_OBCReady4Pre: start 92, 1 bit, big-endian, i-signal-type=PRIMITIVE, init-value=constant-reference=Init_CAN3_OBCReady4Pre, base-type=uint8, implementation-data-type=uint8, transfer-property=TRIGGERED-ON-CHANGE
          signal CAN3_OBCRlySta: start 39, 2 bit, big-endian, i-signal-type=PRIMITIVE, init-value=constant-reference=Init_CAN3_OBCRlySta, base-type=uint8, implementation-data-type=uint8, transfer-property=TRIGGERED-ON-CHANGE
          signal CAN3_OBCTemp: start 87, 9 bit, big-endian, i-signal-type=PRIMITIVE, init-value=constant-reference=Init_CAN3_OBCTemp, base-type=uint16, implementation-data-type=uint16, transfer-property=PENDING
          signal CAN3_OBCV2LSta: start 31, 2 bit, big-endian, i-signal-type=PRIMITIVE, init-value=constant-reference=Init_CAN3_OBCV2LSta, base-type=uint8, implementation-data-type=uint8, transfer-property=TRIGGERED-ON-CHANGE
          signal CAN3_OBC_AC_Cur_Lim: start 37, 2 bit, big-endian, i-signal-type=PRIMITIVE, init-value=constant-reference=Init_CAN3_OBC_AC_Cur_Lim, base-type=uint8, implementation-data-type=uint8, transfer-property=TRIGGERED-ON-CHANGE
          signal CAN3_RC_CCU2: start 11, 4 bit, big-endian, i-signal-type=PRIMITIVE, init-value=constant-reference=Init_CAN3_RC_CCU2, base-type=uint8, implementation-data-type=uint8, transfer-property=PENDING
      frame CAN3_DiagFuncReqFT: id 0x7D0, frame-length=8, can-addressing-mode=STANDARD, can-fd-frame-support=true, can-frame-rx-behavior=CAN-FD, can-frame-tx-behavior=CAN-FD
        n pdu CAN3_DiagFuncReqFT: length=8
      frame CAN3_DiagPhysReqToBMS: id 0x6B0, frame-length=8, can-addressing-mode=STANDARD, can-fd-frame-support=true, can-frame-rx-behavior=CAN-FD, can-frame-tx-behavior=CAN-FD
        n pdu CAN3_DiagPhysReqToBMS: length=8
      frame CAN3_DiagPhysReqToCCU: id 0x6B3, frame-length=8, can-addressing-mode=STANDARD, can-fd-frame-support=true, can-frame-rx-behavior=CAN-FD, can-frame-tx-behavior=CAN-FD
        n pdu CAN3_DiagPhysReqToCCU: length=8
      frame CAN3_DiagPhysReqToEBM: id 0x6A3, frame-length=8, can-addressing-mode=STANDARD, can-fd-frame-support=false, can-frame-rx-behavior=CAN-20, can-frame-tx-behavior=CAN-20
        n pdu CAN3_DiagPhysReqToEBM: length=8
      frame CAN3_DiagPhysReqToEOP_F: id 0x698, frame-length=64, can-addressing-mode=STANDARD, can-fd-frame-support=true, can-frame-rx-behavior=CAN-FD, can-frame-tx-behavior=CAN-FD
        n pdu CAN3_DiagPhysReqToEOP_F: length=8
      frame CAN3_DiagPhysReqToEOP_R: id 0x693, frame-length=64, can-addressing-mode=STANDARD, can-fd-frame-support=true, can-frame-rx-behavior=CAN-FD, can-frame-tx-behavior=CAN-FD
        n pdu CAN3_DiagPhysReqToEOP_R: length=8
      frame CAN3_DiagPhysReqToMCU_B_F: id 0x68A, frame-length=64, can-addressing-mode=STANDARD, can-fd-frame-support=true, can-frame-rx-behavior=CAN-FD, can-frame-tx-behavior=CAN-FD
        n pdu CAN3_DiagPhysReqToMCU_B_F: length=8
      frame CAN3_DiagPhysReqToMCU_B_R: id 0x689, frame-length=64, can-addressing-mode=STANDARD, can-fd-frame-support=true, can-frame-rx-behavior=CAN-FD, can-frame-tx-behavior=CAN-FD
        n pdu CAN3_DiagPhysReqToMCU_B_R: length=8
      frame CAN3_DiagPhysReqToMCU_N_F: id 0x688, frame-length=8, can-addressing-mode=STANDARD, can-fd-frame-support=true, can-frame-rx-behavior=CAN-FD, can-frame-tx-behavior=CAN-FD
        n pdu CAN3_DiagPhysReqToMCU_N_F: length=8
      frame CAN3_DiagPhysReqToMCU_N_R: id 0x683, frame-length=8, can-addressing-mode=STANDARD, can-fd-frame-support=true, can-frame-rx-behavior=CAN-FD, can-frame-tx-behavior=CAN-FD
        n pdu CAN3_DiagPhysReqToMCU_N_R: length=8
      frame CAN3_DiagPhysReqToShifter: id 0x6B8, frame-length=8, can-addressing-mode=STANDARD, can-fd-frame-support=true, can-frame-rx-behavior=CAN-FD, can-frame-tx-behavior=CAN-FD
        n pdu CAN3_DiagPhysReqToShifter: length=8
      frame CAN3_DiagRespFromBMS: id 0x630, frame-length=8, can-addressing-mode=STANDARD, can-fd-frame-support=true, can-frame-rx-behavior=CAN-FD, can-frame-tx-behavior=CAN-FD
        n pdu CAN3_DiagRespFromBMS: length=8
      frame CAN3_DiagRespFromCCU: id 0x633, frame-length=8, can-addressing-mode=STANDARD, can-fd-frame-support=true, can-frame-rx-behavior=CAN-FD, can-frame-tx-behavior=CAN-FD
        n pdu CAN3_DiagRespFromCCU: length=8
      frame CAN3_DiagRespFromEBM: id 0x623, frame-length=8, can-addressing-mode=STANDARD, can-fd-frame-support=false, can-frame-rx-behavior=CAN-20, can-frame-tx-behavior=CAN-20
        n pdu CAN3_DiagRespFromEBM: length=8
      frame CAN3_DiagRespFromEOP_F: id 0x618, frame-length=64, can-addressing-mode=STANDARD, can-fd-frame-support=true, can-frame-rx-behavior=CAN-FD, can-frame-tx-behavior=CAN-FD
        n pdu CAN3_DiagRespFromEOP_F: length=8
      frame CAN3_DiagRespFromEOP_R: id 0x613, frame-length=64, can-addressing-mode=STANDARD, can-fd-frame-support=true, can-frame-rx-behavior=CAN-FD, can-frame-tx-behavior=CAN-FD
        n pdu CAN3_DiagRespFromEOP_R: length=8
      frame CAN3_DiagRespFromMCU_B_F: id 0x60A, frame-length=64, can-addressing-mode=STANDARD, can-fd-frame-support=true, can-frame-rx-behavior=CAN-FD, can-frame-tx-behavior=CAN-FD
        n pdu CAN3_DiagRespFromMCU_B_F: length=8
      frame CAN3_DiagRespFromMCU_B_R: id 0x609, frame-length=64, can-addressing-mode=STANDARD, can-fd-frame-support=true, can-frame-rx-behavior=CAN-FD, can-frame-tx-behavior=CAN-FD
        n pdu CAN3_DiagRespFromMCU_B_R: length=8
      frame CAN3_DiagRespFromMCU_N_F: id 0x608, frame-length=8, can-addressing-mode=STANDARD, can-fd-frame-support=true, can-frame-rx-behavior=CAN-FD, can-frame-tx-behavior=CAN-FD
        n pdu CAN3_DiagRespFromMCU_N_F: length=8
      frame CAN3_DiagRespFromMCU_N_R: id 0x603, frame-length=8, can-addressing-mode=STANDARD, can-fd-frame-support=true, can-frame-rx-behavior=CAN-FD, can-frame-tx-behavior=CAN-FD
        n pdu CAN3_DiagRespFromMCU_N_R: length=8
      frame CAN3_DiagRespFromShifter: id 0x638, frame-length=8, can-addressing-mode=STANDARD, can-fd-frame-support=true, can-frame-rx-behavior=CAN-FD, can-frame-tx-behavior=CAN-FD
        n pdu CAN3_DiagRespFromShifter: length=8
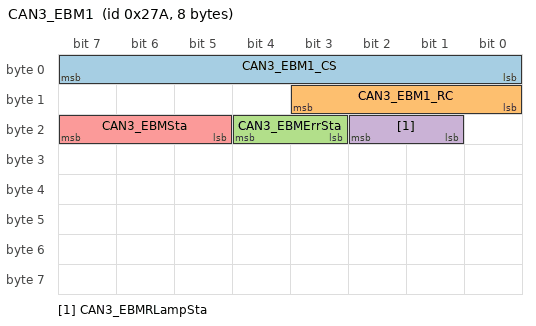
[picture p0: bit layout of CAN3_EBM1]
      frame CAN3_EBM1: id 0x27A, frame-length=8, can-addressing-mode=STANDARD, can-fd-frame-support=true, can-frame-rx-behavior=CAN-FD, can-frame-tx-behavior=CAN-FD
        pdu CAN3_EBM1: length=8, minimum-delay=0.0, transmission-mode-true-timing=cyclic-timing=time-period=0.04, unused-bit-pattern=0
          mapping CAN3_SG_EBM1: i-signal-group=CAN3_SG_EBM1, start-position=0, transfer-property=PENDING
          signal CAN3_EBM1_CS: start 7, 8 bit, big-endian, i-signal-type=PRIMITIVE, init-value=constant-reference=Init_CAN3_EBM1_CS, base-type=uint8, implementation-data-type=uint8, transfer-property=PENDING
          signal CAN3_EBM1_RC: start 11, 4 bit, big-endian, i-signal-type=PRIMITIVE, init-value=constant-reference=Init_CAN3_EBM1_RC, base-type=uint8, implementation-data-type=uint8, transfer-property=PENDING
          signal CAN3_EBMErrSta: start 20, 2 bit, big-endian, i-signal-type=PRIMITIVE, init-value=constant-reference=Init_CAN3_EBMErrSta, base-type=uint8, implementation-data-type=uint8, transfer-property=PENDING
          signal CAN3_EBMRLampSta: start 18, 2 bit, big-endian, i-signal-type=PRIMITIVE, init-value=constant-reference=Init_CAN3_EBMRLampSta, base-type=uint8, implementation-data-type=uint8, transfer-property=PENDING
          signal CAN3_EBMSta: start 23, 3 bit, big-endian, i-signal-type=PRIMITIVE, init-value=constant-reference=Init_CAN3_EBMSta, base-type=uint8, implementation-data-type=uint8, transfer-property=PENDING
      frame CAN3_FD3_BCM1: id 0x216, frame-length=16, can-addressing-mode=STANDARD, can-fd-frame-support=true, can-frame-rx-behavior=CAN-FD, can-frame-tx-behavior=CAN-FD
        pdu CAN3_FD3_BCM1: length=16, minimum-delay=0.0, transmission-mode-true-timing={cyclic-timing=time-period=0.2, event-controlled-timing={number-of-repetitions=0, repetition-period=0}}, unused-bit-pattern=0
          mapping CAN3_SG_FD3_BCM1: i-signal-group=CAN3_SG_FD3_BCM1, start-position=0, transfer-property=TRIGGERED-ON-CHANGE
          signal CAN3_AllDoorSW: start 124, 1 bit, big-endian, i-signal-type=PRIMITIVE, init-value=constant-reference=Init_CAN3_AllDoorSW, base-type=uint8, implementation-data-type=uint8, transfer-property=TRIGGERED-ON-CHANGE
          signal CAN3_AntiTheftSeatFold: start 84, 1 bit, big-endian, i-signal-type=PRIMITIVE, init-value=constant-reference=Init_CAN3_AntiTheftSeatFold, base-type=uint8, implementation-data-type=uint8, transfer-property=TRIGGERED-ON-CHANGE
          signal CAN3_AntitheftSta: start 83, 2 bit, big-endian, i-signal-type=PRIMITIVE, init-value=constant-reference=Init_CAN3_AntitheftSta, base-type=uint8, implementation-data-type=uint8, transfer-property=TRIGGERED-ON-CHANGE
          signal CAN3_BCM_Buzzer_Req: start 64, 1 bit, big-endian, i-signal-type=PRIMITIVE, init-value=constant-reference=Init_CAN3_BCM_Buzzer_Req, base-type=uint8, implementation-data-type=uint8, transfer-property=TRIGGERED-ON-CHANGE
          signal CAN3_BCM_DoorLock_Sta: start 70, 1 bit, big-endian, i-signal-type=PRIMITIVE, init-value=constant-reference=Init_CAN3_BCM_DoorLock_Sta, base-type=uint8, implementation-data-type=uint8, transfer-property=TRIGGERED-ON-CHANGE
          signal CAN3_BrakeLamp: start 90, 1 bit, big-endian, i-signal-type=PRIMITIVE, init-value=constant-reference=Init_CAN3_BrakeLamp, base-type=uint8, implementation-data-type=uint8, transfer-property=TRIGGERED-ON-CHANGE
          signal CAN3_CTDCtrl: start 113, 2 bit, big-endian, i-signal-type=PRIMITIVE, init-value=constant-reference=Init_CAN3_CTDCtrl, base-type=uint8, implementation-data-type=uint8, transfer-property=TRIGGERED-ON-CHANGE
          signal CAN3_CTDLockSW: start 118, 1 bit, big-endian, i-signal-type=PRIMITIVE, init-value=constant-reference=Init_CAN3_CTDLockSW, base-type=uint8, implementation-data-type=uint8, transfer-property=TRIGGERED-ON-CHANGE
          signal CAN3_CTDUnlockSW: start 119, 1 bit, big-endian, i-signal-type=PRIMITIVE, init-value=constant-reference=Init_CAN3_CTDUnlockSW, base-type=uint8, implementation-data-type=uint8, transfer-property=TRIGGERED-ON-CHANGE
          signal CAN3_CrashDetd: start 85, 1 bit, big-endian, i-signal-type=PRIMITIVE, init-value=constant-reference=Init_CAN3_CrashDetd, base-type=uint8, implementation-data-type=uint8, transfer-property=TRIGGERED-ON-CHANGE
          signal CAN3_Dimmer: start 78, 7 bit, big-endian, i-signal-type=PRIMITIVE, init-value=constant-reference=Init_CAN3_Dimmer, base-type=uint8, implementation-data-type=uint8, transfer-property=TRIGGERED-ON-CHANGE
          signal CAN3_DimmerEN: start 69, 1 bit, big-endian, i-signal-type=PRIMITIVE, init-value=constant-reference=Init_CAN3_DimmerEN, base-type=uint8, implementation-data-type=uint8, transfer-property=TRIGGERED-ON-CHANGE
          signal CAN3_DoorLockIND: start 125, 1 bit, big-endian, i-signal-type=PRIMITIVE, init-value=constant-reference=Init_CAN3_DoorLockIND, base-type=uint8, implementation-data-type=uint8, transfer-property=TRIGGERED-ON-CHANGE
          signal CAN3_DrDoorSW: start 120, 1 bit, big-endian, i-signal-type=PRIMITIVE, init-value=constant-reference=Init_CAN3_DrDoorSW, base-type=uint8, implementation-data-type=uint8, transfer-property=TRIGGERED-ON-CHANGE
          signal CAN3_Fr_ChargingDoorCtrl: start 115, 2 bit, big-endian, i-signal-type=PRIMITIVE, init-value=constant-reference=Init_CAN3_Fr_ChargingDoorCtrl, base-type=uint8, implementation-data-type=uint8, transfer-property=TRIGGERED-ON-CHANGE
          signal CAN3_Fr_FogLamp: start 93, 1 bit, big-endian, i-signal-type=PRIMITIVE, init-value=constant-reference=Init_CAN3_Fr_FogLamp, base-type=uint8, implementation-data-type=uint8, transfer-property=TRIGGERED-ON-CHANGE
          signal CAN3_Fr_Wiper_H: start 110, 1 bit, big-endian, i-signal-type=PRIMITIVE, init-value=constant-reference=Init_CAN3_Fr_Wiper_H, base-type=uint8, implementation-data-type=uint8, transfer-property=TRIGGERED-ON-CHANGE
          signal CAN3_Fr_Wiper_L: start 111, 1 bit, big-endian, i-signal-type=PRIMITIVE, init-value=constant-reference=Init_CAN3_Fr_Wiper_L, base-type=uint8, implementation-data-type=uint8, transfer-property=TRIGGERED-ON-CHANGE
          signal CAN3_H_Beam: start 101, 1 bit, big-endian, i-signal-type=PRIMITIVE, init-value=constant-reference=Init_CAN3_H_Beam, base-type=uint8, implementation-data-type=uint8, transfer-property=TRIGGERED-ON-CHANGE
          signal CAN3_HazardSW: start 95, 1 bit, big-endian, i-signal-type=PRIMITIVE, init-value=constant-reference=Init_CAN3_HazardSW, base-type=uint8, implementation-data-type=uint8, transfer-property=TRIGGERED-ON-CHANGE
          signal CAN3_HoodSW: start 126, 1 bit, big-endian, i-signal-type=PRIMITIVE, init-value=constant-reference=Init_CAN3_HoodSW, base-type=uint8, implementation-data-type=uint8, transfer-property=TRIGGERED-ON-CHANGE
          signal CAN3_HornCtrl: start 71, 1 bit, big-endian, i-signal-type=PRIMITIVE, init-value=constant-reference=Init_CAN3_HornCtrl, base-type=uint8, implementation-data-type=uint8, transfer-property=TRIGGERED-ON-CHANGE
          signal CAN3_LBSD: start 91, 1 bit, big-endian, i-signal-type=PRIMITIVE, init-value=constant-reference=Init_CAN3_LBSD, base-type=uint8, implementation-data-type=uint8, transfer-property=TRIGGERED-ON-CHANGE
          signal CAN3_LDRL: start 103, 1 bit, big-endian, i-signal-type=PRIMITIVE, init-value=constant-reference=Init_CAN3_LDRL, base-type=uint8, implementation-data-type=uint8, transfer-property=TRIGGERED-ON-CHANGE
          signal CAN3_LTurnLP: start 80, 1 bit, big-endian, i-signal-type=PRIMITIVE, init-value=constant-reference=Init_CAN3_LTurnLP, base-type=uint8, implementation-data-type=uint8, transfer-property=TRIGGERED-ON-CHANGE
          signal CAN3_L_APM_WdwEnable: start 87, 1 bit, big-endian, i-signal-type=PRIMITIVE, init-value=constant-reference=Init_CAN3_L_APM_WdwEnable, base-type=uint8, implementation-data-type=uint8, transfer-property=TRIGGERED-ON-CHANGE
          signal CAN3_L_Beam: start 100, 1 bit, big-endian, i-signal-type=PRIMITIVE, init-value=constant-reference=Init_CAN3_L_Beam, base-type=uint8, implementation-data-type=uint8, transfer-property=TRIGGERED-ON-CHANGE
          signal CAN3_LockSetting: start 79, 1 bit, big-endian, i-signal-type=PRIMITIVE, init-value=constant-reference=Init_CAN3_LockSetting, base-type=uint8, implementation-data-type=uint8, transfer-property=TRIGGERED-ON-CHANGE
          signal CAN3_MirrorCtrl: start 109, 2 bit, big-endian, i-signal-type=PRIMITIVE, init-value=constant-reference=Init_CAN3_MirrorCtrl, base-type=uint8, implementation-data-type=uint8, transfer-property=TRIGGERED-ON-CHANGE
          signal CAN3_MirrorDefog: start 104, 1 bit, big-endian, i-signal-type=PRIMITIVE, init-value=constant-reference=Init_CAN3_MirrorDefog, base-type=uint8, implementation-data-type=uint8, transfer-property=TRIGGERED-ON-CHANGE
          signal CAN3_PosLamp: start 102, 1 bit, big-endian, i-signal-type=PRIMITIVE, init-value=constant-reference=Init_CAN3_PosLamp, base-type=uint8, implementation-data-type=uint8, transfer-property=TRIGGERED-ON-CHANGE
          signal CAN3_PsDoorSW: start 121, 1 bit, big-endian, i-signal-type=PRIMITIVE, init-value=constant-reference=Init_CAN3_PsDoorSW, base-type=uint8, implementation-data-type=uint8, transfer-property=TRIGGERED-ON-CHANGE
          signal CAN3_RBSD: start 92, 1 bit, big-endian, i-signal-type=PRIMITIVE, init-value=constant-reference=Init_CAN3_RBSD, base-type=uint8, implementation-data-type=uint8, transfer-property=TRIGGERED-ON-CHANGE
          signal CAN3_RDRL: start 88, 1 bit, big-endian, i-signal-type=PRIMITIVE, init-value=constant-reference=Init_CAN3_RDRL, base-type=uint8, implementation-data-type=uint8, transfer-property=TRIGGERED-ON-CHANGE
          signal CAN3_RLDoorSW: start 122, 1 bit, big-endian, i-signal-type=PRIMITIVE, init-value=constant-reference=Init_CAN3_RLDoorSW, base-type=uint8, implementation-data-type=uint8, transfer-property=TRIGGERED-ON-CHANGE
          signal CAN3_RRDoorSW: start 123, 1 bit, big-endian, i-signal-type=PRIMITIVE, init-value=constant-reference=Init_CAN3_RRDoorSW, base-type=uint8, implementation-data-type=uint8, transfer-property=TRIGGERED-ON-CHANGE
          signal CAN3_RTurnLP: start 81, 1 bit, big-endian, i-signal-type=PRIMITIVE, init-value=constant-reference=Init_CAN3_RTurnLP, base-type=uint8, implementation-data-type=uint8, transfer-property=TRIGGERED-ON-CHANGE
          signal CAN3_ReverseLamp: start 89, 1 bit, big-endian, i-signal-type=PRIMITIVE, init-value=constant-reference=Init_CAN3_ReverseLamp, base-type=uint8, implementation-data-type=uint8, transfer-property=TRIGGERED-ON-CHANGE
          signal CAN3_RoomLampH: start 68, 1 bit, big-endian, i-signal-type=PRIMITIVE, init-value=constant-reference=Init_CAN3_RoomLampH, base-type=uint8, implementation-data-type=uint8, transfer-property=TRIGGERED-ON-CHANGE
          signal CAN3_RoomLampL: start 67, 1 bit, big-endian, i-signal-type=PRIMITIVE, init-value=constant-reference=Init_CAN3_RoomLampL, base-type=uint8, implementation-data-type=uint8, transfer-property=TRIGGERED-ON-CHANGE
          signal CAN3_Rr_ChargingDoorCtrl: start 117, 2 bit, big-endian, i-signal-type=PRIMITIVE, init-value=constant-reference=Init_CAN3_Rr_ChargingDoorCtrl, base-type=uint8, implementation-data-type=uint8, transfer-property=TRIGGERED-ON-CHANGE
          signal CAN3_Rr_Defog: start 105, 1 bit, big-endian, i-signal-type=PRIMITIVE, init-value=constant-reference=Init_CAN3_Rr_Defog, base-type=uint8, implementation-data-type=uint8, transfer-property=TRIGGERED-ON-CHANGE
          signal CAN3_Rr_FogLamp: start 94, 1 bit, big-endian, i-signal-type=PRIMITIVE, init-value=constant-reference=Init_CAN3_Rr_FogLamp, base-type=uint8, implementation-data-type=uint8, transfer-property=TRIGGERED-ON-CHANGE
          signal CAN3_Rr_Wiper: start 96, 1 bit, big-endian, i-signal-type=PRIMITIVE, init-value=constant-reference=Init_CAN3_Rr_Wiper, base-type=uint8, implementation-data-type=uint8, transfer-property=TRIGGERED-ON-CHANGE
          signal CAN3_TailgateHDSW: start 107, 1 bit, big-endian, i-signal-type=PRIMITIVE, init-value=constant-reference=Init_CAN3_TailgateHDSW, base-type=uint8, implementation-data-type=uint8, transfer-property=TRIGGERED-ON-CHANGE
          signal CAN3_TailgateRemote: start 66, 2 bit, big-endian, i-signal-type=PRIMITIVE, init-value=constant-reference=Init_CAN3_TailgateRemote, base-type=uint8, implementation-data-type=uint8, transfer-property=TRIGGERED-ON-CHANGE
          signal CAN3_Tailgate_SW: start 127, 1 bit, big-endian, i-signal-type=PRIMITIVE, init-value=constant-reference=Init_CAN3_Tailgate_SW, base-type=uint8, implementation-data-type=uint8, transfer-property=TRIGGERED-ON-CHANGE
          signal CAN3_TrunkRel: start 106, 1 bit, big-endian, i-signal-type=PRIMITIVE, init-value=constant-reference=Init_CAN3_TrunkRel, base-type=uint8, implementation-data-type=uint8, transfer-property=TRIGGERED-ON-CHANGE
          signal CAN3_WasherCtrl: start 99, 2 bit, big-endian, i-signal-type=PRIMITIVE, init-value=constant-reference=Init_CAN3_WasherCtrl, base-type=uint8, implementation-data-type=uint8, transfer-property=TRIGGERED-ON-CHANGE
          signal CAN3_WiperFixMode: start 97, 1 bit, big-endian, i-signal-type=PRIMITIVE, init-value=constant-reference=Init_CAN3_WiperFixMode, base-type=uint8, implementation-data-type=uint8, transfer-property=TRIGGERED-ON-CHANGE
      frame CAN3_FD3_OTA1: id 0x438, frame-length=12, can-addressing-mode=STANDARD, can-fd-frame-support=true, can-frame-rx-behavior=CAN-FD, can-frame-tx-behavior=CAN-FD
        pdu CAN3_FD3_OTA1: length=12, minimum-delay=0.0, transmission-mode-true-timing={cyclic-timing=time-period=0.2, event-controlled-timing={number-of-repetitions=0, repetition-period=0}}, unused-bit-pattern=0
          mapping CAN3_SG_FD3_OTA1: i-signal-group=CAN3_SG_FD3_OTA1, start-position=0, transfer-property=TRIGGERED-ON-CHANGE
          signal CAN3_OTA_DL_Available: start 8, 1 bit, big-endian, i-signal-type=PRIMITIVE, init-value=constant-reference=Init_CAN3_OTA_DL_Available, base-type=uint8, implementation-data-type=uint8, transfer-property=TRIGGERED-ON-CHANGE
          signal CAN3_OTA_DL_Speed: start 27, 20 bit, big-endian, i-signal-type=PRIMITIVE, init-value=constant-reference=Init_CAN3_OTA_DL_Speed, base-type=uint32, implementation-data-type=uint32, transfer-property=TRIGGERED-ON-CHANGE
          signal CAN3_OTA_Debug_Code: start 79, 8 bit, big-endian, i-signal-type=PRIMITIVE, init-value=constant-reference=Init_CAN3_OTA_Debug_Code, base-type=uint8, implementation-data-type=uint8, transfer-property=PENDING
          signal CAN3_OTA_Emergency_Sta: start 61, 2 bit, big-endian, i-signal-type=PRIMITIVE, init-value=constant-reference=Init_CAN3_OTA_Emergency_Sta, base-type=uint8, implementation-data-type=uint8, transfer-property=TRIGGERED-ON-CHANGE
          signal CAN3_OTA_InVehicle_FW: start 29, 2 bit, big-endian, i-signal-type=PRIMITIVE, init-value=constant-reference=Init_CAN3_OTA_InVehicle_FW, base-type=uint8, implementation-data-type=uint8, transfer-property=TRIGGERED-ON-CHANGE
          signal CAN3_OTA_Lock_Req: start 31, 1 bit, big-endian, i-signal-type=PRIMITIVE, init-value=constant-reference=Init_CAN3_OTA_Lock_Req, base-type=uint8, implementation-data-type=uint8, transfer-property=TRIGGERED-ON-CHANGE
          signal CAN3_OTA_MDA_Status: start 52, 5 bit, big-endian, i-signal-type=PRIMITIVE, init-value=constant-reference=Init_CAN3_OTA_MDA_Status, base-type=uint8, implementation-data-type=uint8, transfer-property=TRIGGERED-ON-CHANGE
          signal CAN3_OTA_Mode: start 9, 1 bit, big-endian, i-signal-type=PRIMITIVE, init-value=constant-reference=Init_CAN3_OTA_Mode, base-type=uint8, implementation-data-type=uint8, transfer-property=TRIGGERED-ON-CHANGE
          signal CAN3_OTA_Network_Type: start 11, 2 bit, big-endian, i-signal-type=PRIMITIVE, init-value=constant-reference=Init_CAN3_OTA_Network_Type, base-type=uint8, implementation-data-type=uint8, transfer-property=TRIGGERED-ON-CHANGE
          signal CAN3_OTA_Permit_Agreed: start 63, 1 bit, big-endian, i-signal-type=PRIMITIVE, init-value=constant-reference=Init_CAN3_OTA_Permit_Agreed, base-type=uint8, implementation-data-type=uint8, transfer-property=PENDING
          signal CAN3_OTA_Progress_Rate: start 7, 8 bit, big-endian, i-signal-type=PRIMITIVE, init-value=constant-reference=Init_CAN3_OTA_Progress_Rate, base-type=uint8, implementation-data-type=uint8, transfer-property=TRIGGERED-ON-CHANGE
          signal CAN3_OTA_Remained_Time: start 58, 11 bit, big-endian, i-signal-type=PRIMITIVE, init-value=constant-reference=Init_CAN3_OTA_Remained_Time, base-type=uint16, implementation-data-type=uint16, transfer-property=PENDING
          signal CAN3_OTA_TBOXResetReq: start 30, 1 bit, big-endian, i-signal-type=PRIMITIVE, init-value=constant-reference=Init_CAN3_OTA_TBOXResetReq, base-type=uint8, implementation-data-type=uint8, transfer-property=TRIGGERED-ON-CHANGE
          signal CAN3_OTA_Update_Available: start 62, 1 bit, big-endian, i-signal-type=PRIMITIVE, init-value=constant-reference=Init_CAN3_OTA_Update_Available, base-type=uint8, implementation-data-type=uint8, transfer-property=TRIGGERED-ON-CHANGE
          signal CAN3_OTA_Updating_ECU_8bit: start 23, 8 bit, big-endian, i-signal-type=PRIMITIVE, init-value=constant-reference=Init_CAN3_OTA_Updating_ECU_8bit, base-type=uint8, implementation-data-type=uint8, transfer-property=TRIGGERED-ON-CHANGE
      frame CAN3_FD3_THCM1: id 0x182, frame-length=20, can-addressing-mode=STANDARD, can-fd-frame-support=true, can-frame-rx-behavior=CAN-FD, can-frame-tx-behavior=CAN-FD
        pdu CAN3_FD3_THCM1: length=20, minimum-delay=0.0, transmission-mode-true-timing=cyclic-timing=time-period=0.1, unused-bit-pattern=0
          mapping CAN3_SG_FD3_THCM1: i-signal-group=CAN3_SG_FD3_THCM1, start-position=0, transfer-property=PENDING
          signal CAN3_BatteryMode: start 118, 3 bit, big-endian, i-signal-type=PRIMITIVE, init-value=constant-reference=Init_CAN3_BatteryMode, base-type=uint8, implementation-data-type=uint8, transfer-property=PENDING
          signal CAN3_CCU_ACLampSts: start 6, 1 bit, big-endian, i-signal-type=PRIMITIVE, init-value=constant-reference=Init_CAN3_CCU_ACLampSts, base-type=uint8, implementation-data-type=uint8, transfer-property=PENDING
          signal CAN3_CCU_ACMaxLampSts: start 1, 1 bit, big-endian, i-signal-type=PRIMITIVE, init-value=constant-reference=Init_CAN3_CCU_ACMaxLampSts, base-type=uint8, implementation-data-type=uint8, transfer-property=PENDING
          signal CAN3_CCU_AutoLampSts: start 2, 1 bit, big-endian, i-signal-type=PRIMITIVE, init-value=constant-reference=Init_CAN3_CCU_AutoLampSts, base-type=uint8, implementation-data-type=uint8, transfer-property=PENDING
          signal CAN3_CCU_AutoMidLampSts: start 3, 1 bit, big-endian, i-signal-type=PRIMITIVE, init-value=constant-reference=Init_CAN3_CCU_AutoMidLampSts, base-type=uint8, implementation-data-type=uint8, transfer-property=PENDING
          signal CAN3_CCU_Dispaly_Request: start 5, 1 bit, big-endian, i-signal-type=PRIMITIVE, init-value=constant-reference=Init_CAN3_CCU_Dispaly_Request, base-type=uint8, implementation-data-type=uint8, transfer-property=PENDING
          signal CAN3_CCU_EcoSts: start 4, 1 bit, big-endian, i-signal-type=PRIMITIVE, init-value=constant-reference=Init_CAN3_CCU_EcoSts, base-type=uint8, implementation-data-type=uint8, transfer-property=PENDING
          signal CAN3_CCU_FrtOnOffLampSts: start 19, 1 bit, big-endian, i-signal-type=PRIMITIVE, init-value=constant-reference=Init_CAN3_CCU_FrtOnOffLampSts, base-type=uint8, implementation-data-type=uint8, transfer-property=PENDING
          signal CAN3_CCU_HEATMaxLampSts: start 7, 1 bit, big-endian, i-signal-type=PRIMITIVE, init-value=constant-reference=Init_CAN3_CCU_HEATMaxLampSts, base-type=uint8, implementation-data-type=uint8, transfer-property=PENDING
          signal CAN3_CCU_RrOnOffLampSts: start 23, 1 bit, big-endian, i-signal-type=PRIMITIVE, init-value=constant-reference=Init_CAN3_CCU_RrOnOffLampSts, base-type=uint8, implementation-data-type=uint8, transfer-property=PENDING
          signal CAN3_CCU_SyncLampSts: start 39, 1 bit, big-endian, i-signal-type=PRIMITIVE, init-value=constant-reference=Init_CAN3_CCU_SyncLampSts, base-type=uint8, implementation-data-type=uint8, transfer-property=PENDING
          signal CAN3_CabinMode: start 115, 4 bit, big-endian, i-signal-type=PRIMITIVE, init-value=constant-reference=Init_CAN3_CabinMode, base-type=uint8, implementation-data-type=uint8, transfer-property=PENDING
          signal CAN3_EDriveMode: start 63, 2 bit, big-endian, i-signal-type=PRIMITIVE, init-value=constant-reference=Init_CAN3_EDriveMode, base-type=uint8, implementation-data-type=uint8, transfer-property=PENDING
          signal CAN3_FD_AGS_Cmd: start 143, 8 bit, big-endian, i-signal-type=PRIMITIVE, init-value=constant-reference=Init_CAN3_FD_AGS_Cmd, base-type=uint8, implementation-data-type=uint8, transfer-property=PENDING
          signal CAN3_FD_RecyAuto_Cmd: start 111, 3 bit, big-endian, i-signal-type=PRIMITIVE, init-value=constant-reference=Init_CAN3_FD_RecyAuto_Cmd, base-type=uint8, implementation-data-type=uint8, transfer-property=PENDING
          signal CAN3_Fr_Coolantflow: start 61, 6 bit, big-endian, i-signal-type=PRIMITIVE, init-value=constant-reference=Init_CAN3_Fr_Coolantflow, base-type=uint8, implementation-data-type=uint8, transfer-property=PENDING
          signal CAN3_Fr_Coolanttemp: start 0, 9 bit, big-endian, i-signal-type=PRIMITIVE, init-value=constant-reference=Init_CAN3_Fr_Coolanttemp, base-type=uint16, implementation-data-type=uint16, transfer-property=PENDING
          signal CAN3_HPThermalRecoveryReq: start 55, 2 bit, big-endian, i-signal-type=PRIMITIVE, init-value=constant-reference=Init_CAN3_HPThermalRecoveryReq, base-type=uint8, implementation-data-type=uint8, transfer-property=PENDING
          signal CAN3_Rr_Coolantflow: start 150, 6 bit, big-endian, i-signal-type=PRIMITIVE, init-value=constant-reference=Init_CAN3_Rr_Coolantflow, base-type=uint8, implementation-data-type=uint8, transfer-property=PENDING
          signal CAN3_Rr_Coolanttemp: start 144, 9 bit, big-endian, i-signal-type=PRIMITIVE, init-value=constant-reference=Init_CAN3_Rr_Coolanttemp, base-type=uint16, implementation-data-type=uint16, transfer-property=PENDING
          signal CAN3_sigAirIntenZon1St: start 31, 4 bit, big-endian, i-signal-type=PRIMITIVE, init-value=constant-reference=Init_CAN3_sigAirIntenZon1St, base-type=uint8, implementation-data-type=uint8, transfer-property=PENDING
          signal CAN3_sigAirIntenZon3St: start 27, 4 bit, big-endian, i-signal-type=PRIMITIVE, init-value=constant-reference=Init_CAN3_sigAirIntenZon3St, base-type=uint8, implementation-data-type=uint8, transfer-property=PENDING
          signal CAN3_sigAmbAirT: start 95, 8 bit, big-endian, i-signal-type=PRIMITIVE, init-value=constant-reference=Init_CAN3_sigAmbAirT, base-type=uint8, implementation-data-type=uint8, transfer-property=PENDING
          signal CAN3_sigCbnAirT: start 87, 8 bit, big-endian, i-signal-type=PRIMITIVE, init-value=constant-reference=Init_CAN3_sigCbnAirT, base-type=uint8, implementation-data-type=uint8, transfer-property=PENDING
          signal CAN3_sigCbnPTCPwrAct: start 79, 8 bit, big-endian, i-signal-type=PRIMITIVE, init-value=constant-reference=Init_CAN3_sigCbnPTCPwrAct, base-type=uint8, implementation-data-type=uint8, transfer-property=PENDING
          signal CAN3_sigCbnSolarLeft: start 127, 8 bit, big-endian, i-signal-type=PRIMITIVE, init-value=constant-reference=Init_CAN3_sigCbnSolarLeft, base-type=uint8, implementation-data-type=uint8, transfer-property=PENDING
          signal CAN3_sigCbnSolarRight: start 103, 8 bit, big-endian, i-signal-type=PRIMITIVE, init-value=constant-reference=Init_CAN3_sigCbnSolarRight, base-type=uint8, implementation-data-type=uint8, transfer-property=PENDING
          signal CAN3_sigClmtCmprPwrAct: start 71, 8 bit, big-endian, i-signal-type=PRIMITIVE, init-value=constant-reference=Init_CAN3_sigClmtCmprPwrAct, base-type=uint8, implementation-data-type=uint8, transfer-property=PENDING
          signal CAN3_sigClntTHvBattOut: start 135, 8 bit, big-endian, i-signal-type=PRIMITIVE, init-value=constant-reference=Init_CAN3_sigClntTHvBattOut, base-type=uint8, implementation-data-type=uint8, transfer-property=PENDING
          signal CAN3_sigDfrstSt: start 38, 1 bit, big-endian, i-signal-type=PRIMITIVE, init-value=constant-reference=Init_CAN3_sigDfrstSt, base-type=uint8, implementation-data-type=uint8, transfer-property=PENDING
          signal CAN3_sigHvacSt: start 46, 1 bit, big-endian, i-signal-type=PRIMITIVE, init-value=constant-reference=Init_CAN3_sigHvacSt, base-type=uint8, implementation-data-type=uint8, transfer-property=PENDING
          signal CAN3_sigRecircSt: start 47, 1 bit, big-endian, i-signal-type=PRIMITIVE, init-value=constant-reference=Init_CAN3_sigRecircSt, base-type=uint8, implementation-data-type=uint8, transfer-property=PENDING
          signal CAN3_sigSetTempZon1St: start 53, 6 bit, big-endian, i-signal-type=PRIMITIVE, init-value=constant-reference=Init_CAN3_sigSetTempZon1St, base-type=uint8, implementation-data-type=uint8, transfer-property=PENDING
          signal CAN3_sigSetTempZon2St: start 45, 6 bit, big-endian, i-signal-type=PRIMITIVE, init-value=constant-reference=Init_CAN3_sigSetTempZon2St, base-type=uint8, implementation-data-type=uint8, transfer-property=PENDING
          signal CAN3_sigSetTempZon3St: start 37, 6 bit, big-endian, i-signal-type=PRIMITIVE, init-value=constant-reference=Init_CAN3_sigSetTempZon3St, base-type=uint8, implementation-data-type=uint8, transfer-property=PENDING
          signal CAN3_sigWindDirZon1St: start 22, 3 bit, big-endian, i-signal-type=PRIMITIVE, init-value=constant-reference=Init_CAN3_sigWindDirZon1St, base-type=uint8, implementation-data-type=uint8, transfer-property=PENDING
          signal CAN3_sigWindDirZon3St: start 18, 3 bit, big-endian, i-signal-type=PRIMITIVE, init-value=constant-reference=Init_CAN3_sigWindDirZon3St, base-type=uint8, implementation-data-type=uint8, transfer-property=PENDING
      frame CAN3_FD3_THCM2: id 0x186, frame-length=20, can-addressing-mode=STANDARD, can-fd-frame-support=true, can-frame-rx-behavior=CAN-FD, can-frame-tx-behavior=CAN-FD
        pdu CAN3_FD3_THCM2: length=20, minimum-delay=0.0, transmission-mode-true-timing={cyclic-timing=time-period=0.1, event-controlled-timing={number-of-repetitions=0, repetition-period=0}}, unused-bit-pattern=0
          mapping CAN3_SG_FD3_THCM2: i-signal-group=CAN3_SG_FD3_THCM2, start-position=0, transfer-property=TRIGGERED-ON-CHANGE
          signal CAN3_ACSubMode: start 11, 3 bit, big-endian, i-signal-type=PRIMITIVE, init-value=constant-reference=Init_CAN3_ACSubMode, base-type=uint8, implementation-data-type=uint8, transfer-property=PENDING
          signal CAN3_APTC_ActFrRiPwr: start 143, 8 bit, big-endian, i-signal-type=PRIMITIVE, init-value=constant-reference=Init_CAN3_APTC_ActFrRiPwr, base-type=uint8, implementation-data-type=uint8, transfer-property=TRIGGERED-ON-CHANGE
          signal CAN3_BatLoopActWtFlw: start 151, 8 bit, big-endian, i-signal-type=PRIMITIVE, init-value=constant-reference=Init_CAN3_BatLoopActWtFlw, base-type=uint8, implementation-data-type=uint8, transfer-property=PENDING
          signal CAN3_CCU_CbnPreACWkSts: start 35, 2 bit, big-endian, i-signal-type=PRIMITIVE, init-value=constant-reference=Init_CAN3_CCU_CbnPreACWkSts, base-type=uint8, implementation-data-type=uint8, transfer-property=PENDING
          signal CAN3_CCU_CbnPreEstimdTi: start 55, 6 bit, big-endian, i-signal-type=PRIMITIVE, init-value=constant-reference=Init_CAN3_CCU_CbnPreEstimdTi, base-type=uint8, implementation-data-type=uint8, transfer-property=PENDING
          signal CAN3_CCU_CbnPreSts: start 39, 2 bit, big-endian, i-signal-type=PRIMITIVE, init-value=constant-reference=Init_CAN3_CCU_CbnPreSts, base-type=uint8, implementation-data-type=uint8, transfer-property=PENDING
          signal CAN3_CCU_HiVoltageReq: start 23, 1 bit, big-endian, i-signal-type=PRIMITIVE, init-value=constant-reference=Init_CAN3_CCU_HiVoltageReq, base-type=uint8, implementation-data-type=uint8, transfer-property=PENDING
          signal CAN3_CoolgFanActDuty: start 159, 8 bit, big-endian, i-signal-type=PRIMITIVE, init-value=constant-reference=Init_CAN3_CoolgFanActDuty, base-type=uint8, implementation-data-type=uint8, transfer-property=TRIGGERED-ON-CHANGE
          signal CAN3_DeiceModReq: start 37, 2 bit, big-endian, i-signal-type=PRIMITIVE, init-value=constant-reference=Init_CAN3_DeiceModReq, base-type=uint8, implementation-data-type=uint8, transfer-property=PENDING
          signal CAN3_FD_Blower_Cmd: start 7, 8 bit, big-endian, i-signal-type=PRIMITIVE, init-value=constant-reference=Init_CAN3_FD_Blower_Cmd, base-type=uint8, implementation-data-type=uint8, transfer-property=TRIGGERED-ON-CHANGE
          signal CAN3_FD_Comp_Cmd: start 22, 15 bit, big-endian, i-signal-type=PRIMITIVE, init-value=constant-reference=Init_CAN3_FD_Comp_Cmd, base-type=uint16, implementation-data-type=uint16, transfer-property=TRIGGERED-ON-CHANGE
          signal CAN3_FD_EWP1_Cmd: start 135, 8 bit, big-endian, i-signal-type=PRIMITIVE, init-value=constant-reference=Init_CAN3_FD_EWP1_Cmd, base-type=uint8, implementation-data-type=uint8, transfer-property=PENDING
          signal CAN3_FD_EWP2_Cmd: start 127, 8 bit, big-endian, i-signal-type=PRIMITIVE, init-value=constant-reference=Init_CAN3_FD_EWP2_Cmd, base-type=uint8, implementation-data-type=uint8, transfer-property=PENDING
          signal CAN3_FD_EWP3_Cmd: start 119, 8 bit, big-endian, i-signal-type=PRIMITIVE, init-value=constant-reference=Init_CAN3_FD_EWP3_Cmd, base-type=uint8, implementation-data-type=uint8, transfer-property=PENDING
          signal CAN3_FD_EXV1_Cmd: start 33, 10 bit, big-endian, i-signal-type=PRIMITIVE, init-value=constant-reference=Init_CAN3_FD_EXV1_Cmd, base-type=uint16, implementation-data-type=uint16, transfer-property=PENDING
          signal CAN3_FD_EXV2_Cmd: start 49, 10 bit, big-endian, i-signal-type=PRIMITIVE, init-value=constant-reference=Init_CAN3_FD_EXV2_Cmd, base-type=uint16, implementation-data-type=uint16, transfer-property=PENDING
          signal CAN3_FD_FWV_Cmd: start 8, 1 bit, big-endian, i-signal-type=PRIMITIVE, init-value=constant-reference=Init_CAN3_FD_FWV_Cmd, base-type=uint8, implementation-data-type=uint8, transfer-property=PENDING
          signal CAN3_FD_FrLeAPTCHeatPwr_Cmd: start 87, 8 bit, big-endian, i-signal-type=PRIMITIVE, init-value=constant-reference=Init_CAN3_FD_FrLeAPTCHeatPwr_Cmd, base-type=uint8, implementation-data-type=uint8, transfer-property=TRIGGERED-ON-CHANGE
          signal CAN3_FD_FrRiAPTCHeatPwr_Cmd: start 79, 8 bit, big-endian, i-signal-type=PRIMITIVE, init-value=constant-reference=Init_CAN3_FD_FrRiAPTCHeatPwr_Cmd, base-type=uint8, implementation-data-type=uint8, transfer-property=TRIGGERED-ON-CHANGE
          signal CAN3_FD_FrWPTCHeatPwr_Cmd: start 103, 16 bit, big-endian, i-signal-type=PRIMITIVE, init-value=constant-reference=Init_CAN3_FD_FrWPTCHeatPwr_Cmd, base-type=uint16, implementation-data-type=uint16, transfer-property=TRIGGERED-ON-CHANGE
          signal CAN3_FD_RrAPTCHeatPwr_Cmd: start 95, 8 bit, big-endian, i-signal-type=PRIMITIVE, init-value=constant-reference=Init_CAN3_FD_RrAPTCHeatPwr_Cmd, base-type=uint8, implementation-data-type=uint8, transfer-property=TRIGGERED-ON-CHANGE
          signal CAN3_FD_SOTXV_Cmd: start 12, 1 bit, big-endian, i-signal-type=PRIMITIVE, init-value=constant-reference=Init_CAN3_FD_SOTXV_Cmd, base-type=uint8, implementation-data-type=uint8, transfer-property=PENDING
          signal CAN3_FD_SOV1_Cmd: start 13, 1 bit, big-endian, i-signal-type=PRIMITIVE, init-value=constant-reference=Init_CAN3_FD_SOV1_Cmd, base-type=uint8, implementation-data-type=uint8, transfer-property=PENDING
          signal CAN3_FD_SOV2_Cmd: start 14, 1 bit, big-endian, i-signal-type=PRIMITIVE, init-value=constant-reference=Init_CAN3_FD_SOV2_Cmd, base-type=uint8, implementation-data-type=uint8, transfer-property=PENDING
          signal CAN3_FD_SOV3_Cmd: start 15, 1 bit, big-endian, i-signal-type=PRIMITIVE, init-value=constant-reference=Init_CAN3_FD_SOV3_Cmd, base-type=uint8, implementation-data-type=uint8, transfer-property=PENDING
          signal CAN3_FD_TWV_Cmd: start 71, 8 bit, big-endian, i-signal-type=PRIMITIVE, init-value=constant-reference=Init_CAN3_FD_TWV_Cmd, base-type=uint8, implementation-data-type=uint8, transfer-property=PENDING
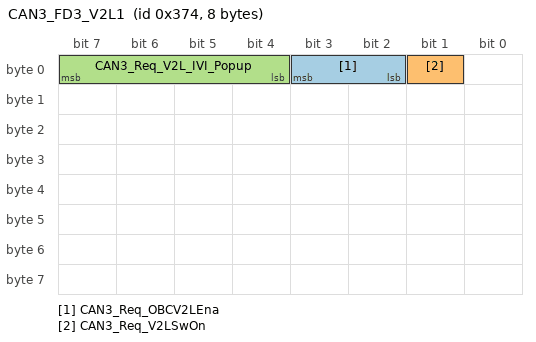
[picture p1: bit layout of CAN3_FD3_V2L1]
      frame CAN3_FD3_V2L1: id 0x374, frame-length=8, can-addressing-mode=STANDARD, can-fd-frame-support=true, can-frame-rx-behavior=CAN-FD, can-frame-tx-behavior=CAN-FD
        pdu CAN3_FD3_V2L1: length=8, minimum-delay=0.0, transmission-mode-true-timing={cyclic-timing=time-period=0.1, event-controlled-timing={number-of-repetitions=0, repetition-period=0}}, unused-bit-pattern=0
          mapping CAN3_SG_FD3_V2L1: i-signal-group=CAN3_SG_FD3_V2L1, start-position=0, transfer-property=TRIGGERED-ON-CHANGE
          signal CAN3_Req_OBCV2LEna: start 3, 2 bit, big-endian, i-signal-type=PRIMITIVE, init-value=constant-reference=Init_CAN3_Req_OBCV2LEna, base-type=uint8, implementation-data-type=uint8, transfer-property=PENDING
          signal CAN3_Req_V2LSwOn: start 1, 1 bit, big-endian, i-signal-type=PRIMITIVE, init-value=constant-reference=Init_CAN3_Req_V2LSwOn, base-type=uint8, implementation-data-type=uint8, transfer-property=TRIGGERED-ON-CHANGE
          signal CAN3_Req_V2L_IVI_Popup: start 7, 4 bit, big-endian, i-signal-type=PRIMITIVE, init-value=constant-reference=Init_CAN3_Req_V2L_IVI_Popup, base-type=uint8, implementation-data-type=uint8, transfer-property=TRIGGERED-ON-CHANGE
      frame CAN3_FD3_VCU0: id 0x1F0, frame-length=64, can-addressing-mode=STANDARD, can-fd-frame-support=true, can-frame-rx-behavior=CAN-FD, can-frame-tx-behavior=CAN-FD
        pdu CAN3_FD3_VCU0: length=64, minimum-delay=0.0, transmission-mode-true-timing=cyclic-timing=time-period=0.01, unused-bit-pattern=0
          mapping CAN3_SG_FD3_VCU0: i-signal-group=CAN3_SG_FD3_VCU0, start-position=0, transfer-property=PENDING
          signal CAN3_EVCCAplusPwrUpReq: start 94, 1 bit, big-endian, i-signal-type=PRIMITIVE, init-value=constant-reference=Init_CAN3_EVCCAplusPwrUpReq, base-type=uint8, implementation-data-type=uint8, transfer-property=PENDING
          signal CAN3_FDADC12VDet: start 215, 8 bit, big-endian, i-signal-type=PRIMITIVE, init-value=constant-reference=Init_CAN3_FDADC12VDet, base-type=uint8, implementation-data-type=uint8, transfer-property=PENDING
          signal CAN3_FDADC12VDetAvg: start 127, 8 bit, big-endian, i-signal-type=PRIMITIVE, init-value=constant-reference=Init_CAN3_FDADC12VDetAvg, base-type=uint8, implementation-data-type=uint8, transfer-property=PENDING
          signal CAN3_FDC_VCU_ActMaxSlideRate_Sta: start 311, 16 bit, big-endian, i-signal-type=PRIMITIVE, init-value=constant-reference=Init_CAN3_FDC_VCU_ActMaxSlideRate_Sta, base-type=uint16, implementation-data-type=uint16, transfer-property=PENDING
          signal CAN3_FDC_VCU_AllowMovThd_OTA_Sta: start 111, 2 bit, big-endian, i-signal-type=PRIMITIVE, init-value=constant-reference=Init_CAN3_FDC_VCU_AllowMovThd_OTA_Sta, base-type=uint8, implementation-data-type=uint8, transfer-property=PENDING
          signal CAN3_FDC_VCU_DTCCarousel_Sta: start 343, 8 bit, big-endian, i-signal-type=PRIMITIVE, init-value=constant-reference=Init_CAN3_FDC_VCU_DTCCarousel_Sta, base-type=uint8, implementation-data-type=uint8, transfer-property=PENDING
          signal CAN3_FDC_VCU_ForceP_Cmd: start 24, 1 bit, big-endian, i-signal-type=PRIMITIVE, init-value=constant-reference=Init_CAN3_FDC_VCU_ForceP_Cmd, base-type=uint8, implementation-data-type=uint8, transfer-property=PENDING
          signal CAN3_FDC_VCU_OTAPwrReqOFFChk_Sta: start 351, 2 bit, big-endian, i-signal-type=PRIMITIVE, init-value=constant-reference=Init_CAN3_FDC_VCU_OTAPwrReqOFFChk_Sta, base-type=uint8, implementation-data-type=uint8, transfer-property=PENDING
          signal CAN3_FDC_VCU_OTAPwrReqStdChk_Sta: start 349, 2 bit, big-endian, i-signal-type=PRIMITIVE, init-value=constant-reference=Init_CAN3_FDC_VCU_OTAPwrReqStdChk_Sta, base-type=uint8, implementation-data-type=uint8, transfer-property=PENDING
          signal CAN3_FDC_VCU_PwrReq_OTA_Sta: start 109, 2 bit, big-endian, i-signal-type=PRIMITIVE, init-value=constant-reference=Init_CAN3_FDC_VCU_PwrReq_OTA_Sta, base-type=uint8, implementation-data-type=uint8, transfer-property=PENDING
          signal CAN3_FDC_VCU_RWDRDCActive_Sta: start 93, 2 bit, big-endian, i-signal-type=PRIMITIVE, init-value=constant-reference=Init_CAN3_FDC_VCU_RWDRDCActive_Sta, base-type=uint8, implementation-data-type=uint8, transfer-property=PENDING
          signal CAN3_FDC_VCU_RegenTqLimitEn_Sta: start 23, 1 bit, big-endian, i-signal-type=PRIMITIVE, init-value=constant-reference=Init_CAN3_FDC_VCU_RegenTqLimitEn_Sta, base-type=uint8, implementation-data-type=uint8, transfer-property=PENDING
          signal CAN3_FDC_VCU_SlideRegenLimTq_Sta: start 327, 16 bit, big-endian, i-signal-type=PRIMITIVE, init-value=constant-reference=Init_CAN3_FDC_VCU_SlideRegenLimTq_Sta, base-type=uint16, implementation-data-type=uint16, transfer-property=PENDING
          signal CAN3_FDC_VCU_VehActSpd_Sta: start 295, 16 bit, big-endian, i-signal-type=PRIMITIVE, init-value=constant-reference=Init_CAN3_FDC_VCU_VehActSpd_Sta, base-type=uint16, implementation-data-type=uint16, transfer-property=PENDING
          signal CAN3_FDC_VCU_VehMalfunLevel_Sta: start 3, 4 bit, big-endian, i-signal-type=PRIMITIVE, init-value=constant-reference=Init_CAN3_FDC_VCU_VehMalfunLevel_Sta, base-type=uint8, implementation-data-type=uint8, transfer-property=PENDING
          signal CAN3_FDC_VMC_ActStESCYaw_Sta: start 263, 16 bit, big-endian, i-signal-type=PRIMITIVE, init-value=constant-reference=Init_CAN3_FDC_VMC_ActStESCYaw_Sta, base-type=uint16, implementation-data-type=uint16, transfer-property=PENDING
          signal CAN3_FDC_VMC_LongAcc_Sta: start 279, 16 bit, big-endian, i-signal-type=PRIMITIVE, init-value=constant-reference=Init_CAN3_FDC_VMC_LongAcc_Sta, base-type=uint16, implementation-data-type=uint16, transfer-property=PENDING
          signal CAN3_FUSION_CMM1: start 135, 8 bit, big-endian, i-signal-type=PRIMITIVE, init-value=constant-reference=Init_CAN3_FUSION_CMM1, base-type=uint8, implementation-data-type=uint8, transfer-property=PENDING
          signal CAN3_FUSION_CMM10: start 207, 8 bit, big-endian, i-signal-type=PRIMITIVE, init-value=constant-reference=Init_CAN3_FUSION_CMM10, base-type=uint8, implementation-data-type=uint8, transfer-property=PENDING
          signal CAN3_FUSION_CMM2: start 143, 8 bit, big-endian, i-signal-type=PRIMITIVE, init-value=constant-reference=Init_CAN3_FUSION_CMM2, base-type=uint8, implementation-data-type=uint8, transfer-property=PENDING
          signal CAN3_FUSION_CMM3: start 151, 8 bit, big-endian, i-signal-type=PRIMITIVE, init-value=constant-reference=Init_CAN3_FUSION_CMM3, base-type=uint8, implementation-data-type=uint8, transfer-property=PENDING
          signal CAN3_FUSION_CMM4: start 159, 8 bit, big-endian, i-signal-type=PRIMITIVE, init-value=constant-reference=Init_CAN3_FUSION_CMM4, base-type=uint8, implementation-data-type=uint8, transfer-property=PENDING
          signal CAN3_FUSION_CMM5: start 167, 8 bit, big-endian, i-signal-type=PRIMITIVE, init-value=constant-reference=Init_CAN3_FUSION_CMM5, base-type=uint8, implementation-data-type=uint8, transfer-property=PENDING
          signal CAN3_FUSION_CMM6: start 175, 8 bit, big-endian, i-signal-type=PRIMITIVE, init-value=constant-reference=Init_CAN3_FUSION_CMM6, base-type=uint8, implementation-data-type=uint8, transfer-property=PENDING
          signal CAN3_FUSION_CMM7: start 183, 8 bit, big-endian, i-signal-type=PRIMITIVE, init-value=constant-reference=Init_CAN3_FUSION_CMM7, base-type=uint8, implementation-data-type=uint8, transfer-property=PENDING
          signal CAN3_FUSION_CMM8: start 191, 8 bit, big-endian, i-signal-type=PRIMITIVE, init-value=constant-reference=Init_CAN3_FUSION_CMM8, base-type=uint8, implementation-data-type=uint8, transfer-property=PENDING
          signal CAN3_FUSION_CMM9: start 199, 8 bit, big-endian, i-signal-type=PRIMITIVE, init-value=constant-reference=Init_CAN3_FUSION_CMM9, base-type=uint8, implementation-data-type=uint8, transfer-property=PENDING
          signal CAN3_Fr_TqSource: start 47, 4 bit, big-endian, i-signal-type=PRIMITIVE, init-value=constant-reference=Init_CAN3_Fr_TqSource, base-type=uint8, implementation-data-type=uint8, transfer-property=PENDING
          signal CAN3_HVRlyOpFail: start 56, 1 bit, big-endian, i-signal-type=PRIMITIVE, init-value=constant-reference=Init_CAN3_HVRlyOpFail, base-type=uint8, implementation-data-type=uint8, transfer-property=PENDING
          signal CAN3_HVTHCMSysAvail: start 41, 2 bit, big-endian, i-signal-type=PRIMITIVE, init-value=constant-reference=Init_CAN3_HVTHCMSysAvail, base-type=uint8, implementation-data-type=uint8, transfer-property=PENDING
          signal CAN3_LVBattChrgtimeAct: start 107, 12 bit, big-endian, i-signal-type=PRIMITIVE, init-value=constant-reference=Init_CAN3_LVBattChrgtimeAct, base-type=uint16, implementation-data-type=uint16, transfer-property=PENDING
          signal CAN3_LVBattVoltSta: start 43, 2 bit, big-endian, i-signal-type=PRIMITIVE, init-value=constant-reference=Init_CAN3_LVBattVoltSta, base-type=uint8, implementation-data-type=uint8, transfer-property=PENDING
          signal CAN3_LVChrgHoldTAct: start 91, 12 bit, big-endian, i-signal-type=PRIMITIVE, init-value=constant-reference=Init_CAN3_LVChrgHoldTAct, base-type=uint16, implementation-data-type=uint16, transfer-property=PENDING
          signal CAN3_LVSilentChrgLv: start 83, 2 bit, big-endian, i-signal-type=PRIMITIVE, init-value=constant-reference=Init_CAN3_LVSilentChrgLv, base-type=uint8, implementation-data-type=uint8, transfer-property=PENDING
          signal CAN3_LVSilentChrgReq: start 81, 1 bit, big-endian, i-signal-type=PRIMITIVE, init-value=constant-reference=Init_CAN3_LVSilentChrgReq, base-type=uint8, implementation-data-type=uint8, transfer-property=PENDING
          signal CAN3_LVSilentChrgSta: start 85, 2 bit, big-endian, i-signal-type=PRIMITIVE, init-value=constant-reference=Init_CAN3_LVSilentChrgSta, base-type=uint8, implementation-data-type=uint8, transfer-property=PENDING
          signal CAN3_MCUActDisFail: start 71, 1 bit, big-endian, i-signal-type=PRIMITIVE, init-value=constant-reference=Init_CAN3_MCUActDisFail, base-type=uint8, implementation-data-type=uint8, transfer-property=PENDING
          signal CAN3_PMMAllowECUSleep: start 95, 1 bit, big-endian, i-signal-type=PRIMITIVE, init-value=constant-reference=Init_CAN3_PMMAllowECUSleep, base-type=uint8, implementation-data-type=uint8, transfer-property=PENDING
          signal CAN3_PmicBootReason: start 223, 8 bit, big-endian, i-signal-type=PRIMITIVE, init-value=constant-reference=Init_CAN3_PmicBootReason, base-type=uint8, implementation-data-type=uint8, transfer-property=PENDING
          signal CAN3_PowerDownFault: start 19, 4 bit, big-endian, i-signal-type=PRIMITIVE, init-value=constant-reference=Init_CAN3_PowerDownFault, base-type=uint8, implementation-data-type=uint8, transfer-property=PENDING
          signal CAN3_PowerDownState: start 22, 3 bit, big-endian, i-signal-type=PRIMITIVE, init-value=constant-reference=Init_CAN3_PowerDownState, base-type=uint8, implementation-data-type=uint8, transfer-property=PENDING
          signal CAN3_PowerUpFault: start 11, 4 bit, big-endian, i-signal-type=PRIMITIVE, init-value=constant-reference=Init_CAN3_PowerUpFault, base-type=uint8, implementation-data-type=uint8, transfer-property=PENDING
          signal CAN3_PowerUpState: start 15, 4 bit, big-endian, i-signal-type=PRIMITIVE, init-value=constant-reference=Init_CAN3_PowerUpState, base-type=uint8, implementation-data-type=uint8, transfer-property=PENDING
          signal CAN3_PwrDownReq: start 37, 2 bit, big-endian, i-signal-type=PRIMITIVE, init-value=constant-reference=Init_CAN3_PwrDownReq, base-type=uint8, implementation-data-type=uint8, transfer-property=PENDING
          signal CAN3_PwrStaConstraint: start 29, 3 bit, big-endian, i-signal-type=PRIMITIVE, init-value=constant-reference=Init_CAN3_PwrStaConstraint, base-type=uint8, implementation-data-type=uint8, transfer-property=PENDING
          signal CAN3_PwrStaONTOIVIPopReq: start 70, 1 bit, big-endian, i-signal-type=PRIMITIVE, init-value=constant-reference=Init_CAN3_PwrStaONTOIVIPopReq, base-type=uint8, implementation-data-type=uint8, transfer-property=PENDING
          signal CAN3_PwrStaONTOIVIPopT: start 67, 12 bit, big-endian, i-signal-type=PRIMITIVE, init-value=constant-reference=Init_CAN3_PwrStaONTOIVIPopT, base-type=uint16, implementation-data-type=uint16, transfer-property=PENDING
          signal CAN3_PwrStaSelect: start 31, 2 bit, big-endian, i-signal-type=PRIMITIVE, init-value=constant-reference=Init_CAN3_PwrStaSelect, base-type=uint8, implementation-data-type=uint8, transfer-property=PENDING
          signal CAN3_PwrStaTOSta: start 69, 1 bit, big-endian, i-signal-type=PRIMITIVE, init-value=constant-reference=Init_CAN3_PwrStaTOSta, base-type=uint8, implementation-data-type=uint8, transfer-property=PENDING
          signal CAN3_PwrUpReq: start 39, 2 bit, big-endian, i-signal-type=PRIMITIVE, init-value=constant-reference=Init_CAN3_PwrUpReq, base-type=uint8, implementation-data-type=uint8, transfer-property=PENDING
          signal CAN3_Rr_TqSource: start 35, 4 bit, big-endian, i-signal-type=PRIMITIVE, init-value=constant-reference=Init_CAN3_Rr_TqSource, base-type=uint8, implementation-data-type=uint8, transfer-property=PENDING
          signal CAN3_SchedChgTOSta: start 87, 1 bit, big-endian, i-signal-type=PRIMITIVE, init-value=constant-reference=Init_CAN3_SchedChgTOSta, base-type=uint8, implementation-data-type=uint8, transfer-property=PENDING
          signal CAN3_SilentChkAllowSleep: start 86, 1 bit, big-endian, i-signal-type=PRIMITIVE, init-value=constant-reference=Init_CAN3_SilentChkAllowSleep, base-type=uint8, implementation-data-type=uint8, transfer-property=PENDING
          signal CAN3_SysAllowReadySta: start 57, 1 bit, big-endian, i-signal-type=PRIMITIVE, init-value=constant-reference=Init_CAN3_SysAllowReadySta, base-type=uint8, implementation-data-type=uint8, transfer-property=PENDING
          signal CAN3_SysPwrSta: start 7, 4 bit, big-endian, i-signal-type=PRIMITIVE, init-value=constant-reference=Init_CAN3_SysPwrSta, base-type=uint8, implementation-data-type=uint8, transfer-property=PENDING
          signal CAN3_TCountSta: start 26, 2 bit, big-endian, i-signal-type=PRIMITIVE, init-value=constant-reference=Init_CAN3_TCountSta, base-type=uint8, implementation-data-type=uint8, transfer-property=PENDING
          signal CAN3_TimerAllowSleep: start 80, 1 bit, big-endian, i-signal-type=PRIMITIVE, init-value=constant-reference=Init_CAN3_TimerAllowSleep, base-type=uint8, implementation-data-type=uint8, transfer-property=PENDING
          signal CAN3_VCUBrkSWSta: start 63, 2 bit, big-endian, i-signal-type=PRIMITIVE, init-value=constant-reference=Init_CAN3_VCUBrkSWSta, base-type=uint8, implementation-data-type=uint8, transfer-property=PENDING
          signal CAN3_VCUFLDoorSta: start 61, 1 bit, big-endian, i-signal-type=PRIMITIVE, init-value=constant-reference=Init_CAN3_VCUFLDoorSta, base-type=uint8, implementation-data-type=uint8, transfer-property=PENDING
          signal CAN3_VCUFRDoorSta: start 60, 1 bit, big-endian, i-signal-type=PRIMITIVE, init-value=constant-reference=Init_CAN3_VCUFRDoorSta, base-type=uint8, implementation-data-type=uint8, transfer-property=PENDING
          signal CAN3_VCURLDoorSta: start 59, 1 bit, big-endian, i-signal-type=PRIMITIVE, init-value=constant-reference=Init_CAN3_VCURLDoorSta, base-type=uint8, implementation-data-type=uint8, transfer-property=PENDING
          signal CAN3_VCURRDoorSta: start 58, 1 bit, big-endian, i-signal-type=PRIMITIVE, init-value=constant-reference=Init_CAN3_VCURRDoorSta, base-type=uint8, implementation-data-type=uint8, transfer-property=PENDING
          signal CAN3_VehHVPwrAvail4THCM: start 55, 8 bit, big-endian, i-signal-type=PRIMITIVE, init-value=constant-reference=Init_CAN3_VehHVPwrAvail4THCM, base-type=uint8, implementation-data-type=uint8, transfer-property=PENDING
          signal CAN3_WisrBootReason: start 231, 32 bit, big-endian, i-signal-type=PRIMITIVE, init-value=constant-reference=Init_CAN3_WisrBootReason, base-type=uint32, implementation-data-type=uint32, transfer-property=PENDING
      frame CAN3_FD3_VCU1: id 0x115, frame-length=8, can-addressing-mode=STANDARD, can-fd-frame-support=true, can-frame-rx-behavior=CAN-FD, can-frame-tx-behavior=CAN-FD
        pdu CAN3_FD3_VCU1: length=8, minimum-delay=0.0, transmission-mode-true-timing=event-controlled-timing={number-of-repetitions=0, repetition-period=0}, unused-bit-pattern=0
          mapping CAN3_SG_FD3_VCU1: i-signal-group=CAN3_SG_FD3_VCU1, start-position=0, transfer-property=TRIGGERED
          signal CAN3_ActiveDischReq: start 44, 1 bit, big-endian, i-signal-type=PRIMITIVE, init-value=constant-reference=Init_CAN3_ActiveDischReq, base-type=uint8, implementation-data-type=uint8, transfer-property=TRIGGERED
          signal CAN3_CS_VCU1: start 7, 8 bit, big-endian, i-signal-type=PRIMITIVE, init-value=constant-reference=Init_CAN3_CS_VCU1, base-type=uint8, implementation-data-type=uint8, transfer-property=TRIGGERED
          signal CAN3_CoastDwModeStaChk: start 19, 2 bit, big-endian, i-signal-type=PRIMITIVE, init-value=constant-reference=Init_CAN3_CoastDwModeStaChk, base-type=uint8, implementation-data-type=uint8, transfer-property=TRIGGERED
          signal CAN3_DCDCEnaReq: start 40, 1 bit, big-endian, i-signal-type=PRIMITIVE, init-value=constant-reference=Init_CAN3_DCDCEnaReq, base-type=uint8, implementation-data-type=uint8, transfer-property=TRIGGERED
          signal CAN3_DCDCVoltSetpoint: start 55, 8 bit, big-endian, i-signal-type=PRIMITIVE, init-value=constant-reference=Init_CAN3_DCDCVoltSetpoint, base-type=uint8, implementation-data-type=uint8, transfer-property=TRIGGERED
          signal CAN3_DemoModeStaChk: start 17, 2 bit, big-endian, i-signal-type=PRIMITIVE, init-value=constant-reference=Init_CAN3_DemoModeStaChk, base-type=uint8, implementation-data-type=uint8, transfer-property=TRIGGERED
          signal CAN3_Dr_SeatSta: start 23, 2 bit, big-endian, i-signal-type=PRIMITIVE, init-value=constant-reference=Init_CAN3_Dr_SeatSta, base-type=uint8, implementation-data-type=uint8, transfer-property=TRIGGERED
          signal CAN3_DynoModeStaChk: start 21, 2 bit, big-endian, i-signal-type=PRIMITIVE, init-value=constant-reference=Init_CAN3_DynoModeStaChk, base-type=uint8, implementation-data-type=uint8, transfer-property=TRIGGERED
          signal CAN3_HVBatCnctReq: start 43, 1 bit, big-endian, i-signal-type=PRIMITIVE, init-value=constant-reference=Init_CAN3_HVBatCnctReq, base-type=uint8, implementation-data-type=uint8, transfer-property=TRIGGERED
          signal CAN3_HVSysReadyToCharge: start 33, 2 bit, big-endian, i-signal-type=PRIMITIVE, init-value=constant-reference=Init_CAN3_HVSysReadyToCharge, base-type=uint8, implementation-data-type=uint8, transfer-property=TRIGGERED
          signal CAN3_LVChrgFuncStaChk: start 25, 2 bit, big-endian, i-signal-type=PRIMITIVE, init-value=constant-reference=Init_CAN3_LVChrgFuncStaChk, base-type=uint8, implementation-data-type=uint8, transfer-property=TRIGGERED
          signal CAN3_MSA_Crl_Sta: start 31, 3 bit, big-endian, i-signal-type=PRIMITIVE, init-value=constant-reference=Init_CAN3_MSA_Crl_Sta, base-type=uint8, implementation-data-type=uint8, transfer-property=TRIGGERED
          signal CAN3_P_Button_Sta: start 35, 2 bit, big-endian, i-signal-type=PRIMITIVE, init-value=constant-reference=Init_CAN3_P_Button_Sta, base-type=uint8, implementation-data-type=uint8, transfer-property=TRIGGERED
          signal CAN3_PrkReq: start 45, 1 bit, big-endian, i-signal-type=PRIMITIVE, init-value=constant-reference=Init_CAN3_PrkReq, base-type=uint8, implementation-data-type=uint8, transfer-property=TRIGGERED
          signal CAN3_PrkReqValid: start 39, 1 bit, big-endian, i-signal-type=PRIMITIVE, init-value=constant-reference=Init_CAN3_PrkReqValid, base-type=uint8, implementation-data-type=uint8, transfer-property=TRIGGERED
          signal CAN3_PwrSta: start 63, 3 bit, big-endian, i-signal-type=PRIMITIVE, init-value=constant-reference=Init_CAN3_PwrSta, base-type=uint8, implementation-data-type=uint8, transfer-property=TRIGGERED
          signal CAN3_RC_VCU1: start 11, 4 bit, big-endian, i-signal-type=PRIMITIVE, init-value=constant-reference=Init_CAN3_RC_VCU1, base-type=uint8, implementation-data-type=uint8, transfer-property=TRIGGERED
          signal CAN3_ShiftGearPosn: start 38, 3 bit, big-endian, i-signal-type=PRIMITIVE, init-value=constant-reference=Init_CAN3_ShiftGearPosn, base-type=uint8, implementation-data-type=uint8, transfer-property=TRIGGERED
      frame CAN3_FD3_VCU1_toNIDEC: id 0x116, frame-length=8, can-addressing-mode=STANDARD, can-fd-frame-support=true, can-frame-rx-behavior=CAN-FD, can-frame-tx-behavior=CAN-FD
        pdu CAN3_FD3_VCU1_toNIDEC: length=8, minimum-delay=0.0, transmission-mode-true-timing=event-controlled-timing={number-of-repetitions=0, repetition-period=0}, unused-bit-pattern=0
          mapping CAN3_SG_FD3_VCU1_toNIDEC: i-signal-group=CAN3_SG_FD3_VCU1_toNIDEC, start-position=0, transfer-property=TRIGGERED
          signal CAN3_ActiveDischReq_toNidec: start 44, 1 bit, big-endian, i-signal-type=PRIMITIVE, init-value=constant-reference=Init_CAN3_ActiveDischReq_toNidec, base-type=uint8, implementation-data-type=uint8, transfer-property=TRIGGERED
          signal CAN3_CS_VCU1_toNidec: start 7, 8 bit, big-endian, i-signal-type=PRIMITIVE, init-value=constant-reference=Init_CAN3_CS_VCU1_toNidec, base-type=uint8, implementation-data-type=uint8, transfer-property=TRIGGERED
          signal CAN3_CoastDwModeStaChk_toNidec: start 19, 2 bit, big-endian, i-signal-type=PRIMITIVE, init-value=constant-reference=Init_CAN3_CoastDwModeStaChk_toNidec, base-type=uint8, implementation-data-type=uint8, transfer-property=TRIGGERED
          signal CAN3_DCDCEnaReq_toNidec: start 40, 1 bit, big-endian, i-signal-type=PRIMITIVE, init-value=constant-reference=Init_CAN3_DCDCEnaReq_toNidec, base-type=uint8, implementation-data-type=uint8, transfer-property=TRIGGERED
          signal CAN3_DCDCVoltSetpoint_toNidec: start 55, 8 bit, big-endian, i-signal-type=PRIMITIVE, init-value=constant-reference=Init_CAN3_DCDCVoltSetpoint_toNidec, base-type=uint8, implementation-data-type=uint8, transfer-property=TRIGGERED
          signal CAN3_DemoModeStaChk_toNidec: start 17, 2 bit, big-endian, i-signal-type=PRIMITIVE, init-value=constant-reference=Init_CAN3_DemoModeStaChk_toNidec, base-type=uint8, implementation-data-type=uint8, transfer-property=TRIGGERED
          signal CAN3_Dr_SeatSta_toNidec: start 23, 2 bit, big-endian, i-signal-type=PRIMITIVE, init-value=constant-reference=Init_CAN3_Dr_SeatSta_toNidec, base-type=uint8, implementation-data-type=uint8, transfer-property=TRIGGERED
          signal CAN3_DynoModeStaChk_toNidec: start 21, 2 bit, big-endian, i-signal-type=PRIMITIVE, init-value=constant-reference=Init_CAN3_DynoModeStaChk_toNidec, base-type=uint8, implementation-data-type=uint8, transfer-property=TRIGGERED
          signal CAN3_Fr_ActvDmpDisabReq_toNidec: start 46, 1 bit, big-endian, i-signal-type=PRIMITIVE, init-value=constant-reference=Init_CAN3_Fr_ActvDmpDisabReq_toNidec, base-type=uint8, implementation-data-type=uint8, transfer-property=TRIGGERED
          signal CAN3_Fr_MCUEnaReq_toNidec: start 41, 1 bit, big-endian, i-signal-type=PRIMITIVE, init-value=constant-reference=Init_CAN3_Fr_MCUEnaReq_toNidec, base-type=uint8, implementation-data-type=uint8, transfer-property=TRIGGERED
          signal CAN3_HVBatCnctReq_toNidec: start 43, 1 bit, big-endian, i-signal-type=PRIMITIVE, init-value=constant-reference=Init_CAN3_HVBatCnctReq_toNidec, base-type=uint8, implementation-data-type=uint8, transfer-property=TRIGGERED
          signal CAN3_HVSysReadyToCharge_toNidec: start 33, 2 bit, big-endian, i-signal-type=PRIMITIVE, init-value=constant-reference=Init_CAN3_HVSysReadyToCharge_toNidec, base-type=uint8, implementation-data-type=uint8, transfer-property=TRIGGERED
          signal CAN3_LVChrgFuncStaChk_toNidec: start 25, 2 bit, big-endian, i-signal-type=PRIMITIVE, init-value=constant-reference=Init_CAN3_LVChrgFuncStaChk_toNidec, base-type=uint8, implementation-data-type=uint8, transfer-property=TRIGGERED
          signal CAN3_MSA_Crl_Sta_toNidec: start 31, 3 bit, big-endian, i-signal-type=PRIMITIVE, init-value=constant-reference=Init_CAN3_MSA_Crl_Sta_toNidec, base-type=uint8, implementation-data-type=uint8, transfer-property=TRIGGERED
          signal CAN3_PrkReq_toNidec: start 45, 1 bit, big-endian, i-signal-type=PRIMITIVE, init-value=constant-reference=Init_CAN3_PrkReq_toNidec, base-type=uint8, implementation-data-type=uint8, transfer-property=TRIGGERED
          signal CAN3_PwrSta_toNidec: start 63, 3 bit, big-endian, i-signal-type=PRIMITIVE, init-value=constant-reference=Init_CAN3_PwrSta_toNidec, base-type=uint8, implementation-data-type=uint8, transfer-property=TRIGGERED
          signal CAN3_RC_VCU1_toNidec: start 15, 4 bit, big-endian, i-signal-type=PRIMITIVE, init-value=constant-reference=Init_CAN3_RC_VCU1_toNidec, base-type=uint8, implementation-data-type=uint8, transfer-property=TRIGGERED
          signal CAN3_Rr_ActvDmpDisabReq_toNidec: start 47, 1 bit, big-endian, i-signal-type=PRIMITIVE, init-value=constant-reference=Init_CAN3_Rr_ActvDmpDisabReq_toNidec, base-type=uint8, implementation-data-type=uint8, transfer-property=TRIGGERED
          signal CAN3_Rr_MCUEnaReq_toNidec: start 42, 1 bit, big-endian, i-signal-type=PRIMITIVE, init-value=constant-reference=Init_CAN3_Rr_MCUEnaReq_toNidec, base-type=uint8, implementation-data-type=uint8, transfer-property=TRIGGERED
          signal CAN3_ShiftGearPosn_toNidec: start 38, 3 bit, big-endian, i-signal-type=PRIMITIVE, init-value=constant-reference=Init_CAN3_ShiftGearPosn_toNidec, base-type=uint8, implementation-data-type=uint8, transfer-property=TRIGGERED
      frame CAN3_FD3_VCU2: id 0x153, frame-length=32, can-addressing-mode=STANDARD, can-fd-frame-support=true, can-frame-rx-behavior=CAN-FD, can-frame-tx-behavior=CAN-FD
        pdu CAN3_FD3_VCU2: length=32, minimum-delay=0.0, transmission-mode-true-timing=cyclic-timing=time-period=0.01, unused-bit-pattern=0
          mapping CAN3_SG_FD3_VCU2: i-signal-group=CAN3_SG_FD3_VCU2, start-position=0, transfer-property=PENDING
          signal CAN3_CS_VCU2_CAN1: start 7, 8 bit, big-endian, i-signal-type=PRIMITIVE, init-value=constant-reference=Init_CAN3_CS_VCU2_CAN1, base-type=uint8, implementation-data-type=uint8, transfer-property=PENDING
          signal CAN3_Fr_ActvDmpDisabReq: start 198, 1 bit, big-endian, i-signal-type=PRIMITIVE, init-value=constant-reference=Init_CAN3_Fr_ActvDmpDisabReq, base-type=uint8, implementation-data-type=uint8, transfer-property=PENDING
          signal CAN3_Fr_IdcMax: start 151, 12 bit, big-endian, i-signal-type=PRIMITIVE, init-value=constant-reference=Init_CAN3_Fr_IdcMax, base-type=uint16, implementation-data-type=uint16, transfer-property=PENDING
          signal CAN3_Fr_IdcMin: start 155, 12 bit, big-endian, i-signal-type=PRIMITIVE, init-value=constant-reference=Init_CAN3_Fr_IdcMin, base-type=uint16, implementation-data-type=uint16, transfer-property=PENDING
          signal CAN3_Fr_MCUEnaReq: start 199, 1 bit, big-endian, i-signal-type=PRIMITIVE, init-value=constant-reference=Init_CAN3_Fr_MCUEnaReq, base-type=uint8, implementation-data-type=uint8, transfer-property=PENDING
          signal CAN3_Fr_TMTqReq: start 135, 16 bit, big-endian, i-signal-type=PRIMITIVE, init-value=constant-reference=Init_CAN3_Fr_TMTqReq, base-type=uint16, implementation-data-type=uint16, transfer-property=PENDING
          signal CAN3_Fr_TorqMax: start 175, 12 bit, big-endian, i-signal-type=PRIMITIVE, init-value=constant-reference=Init_CAN3_Fr_TorqMax, base-type=uint16, implementation-data-type=uint16, transfer-property=PENDING
          signal CAN3_Fr_TorqMin: start 179, 12 bit, big-endian, i-signal-type=PRIMITIVE, init-value=constant-reference=Init_CAN3_Fr_TorqMin, base-type=uint16, implementation-data-type=uint16, transfer-property=PENDING
          signal CAN3_Fr_UdcMax: start 95, 12 bit, big-endian, i-signal-type=PRIMITIVE, init-value=constant-reference=Init_CAN3_Fr_UdcMax, base-type=uint16, implementation-data-type=uint16, transfer-property=PENDING
          signal CAN3_Fr_UdcMin: start 99, 12 bit, big-endian, i-signal-type=PRIMITIVE, init-value=constant-reference=Init_CAN3_Fr_UdcMin, base-type=uint16, implementation-data-type=uint16, transfer-property=PENDING
          signal CAN3_RC_VCU2_CAN1: start 11, 4 bit, big-endian, i-signal-type=PRIMITIVE, init-value=constant-reference=Init_CAN3_RC_VCU2_CAN1, base-type=uint8, implementation-data-type=uint8, transfer-property=PENDING
          signal CAN3_Rr_ActvDmpDisabReq: start 196, 1 bit, big-endian, i-signal-type=PRIMITIVE, init-value=constant-reference=Init_CAN3_Rr_ActvDmpDisabReq, base-type=uint8, implementation-data-type=uint8, transfer-property=PENDING
          signal CAN3_Rr_IdcMax: start 23, 12 bit, big-endian, i-signal-type=PRIMITIVE, init-value=constant-reference=Init_CAN3_Rr_IdcMax, base-type=uint16, implementation-data-type=uint16, transfer-property=PENDING
          signal CAN3_Rr_IdcMin: start 27, 12 bit, big-endian, i-signal-type=PRIMITIVE, init-value=constant-reference=Init_CAN3_Rr_IdcMin, base-type=uint16, implementation-data-type=uint16, transfer-property=PENDING
          signal CAN3_Rr_MCUEnaReq: start 197, 1 bit, big-endian, i-signal-type=PRIMITIVE, init-value=constant-reference=Init_CAN3_Rr_MCUEnaReq, base-type=uint8, implementation-data-type=uint8, transfer-property=PENDING
          signal CAN3_Rr_TMTqReq: start 119, 16 bit, big-endian, i-signal-type=PRIMITIVE, init-value=constant-reference=Init_CAN3_Rr_TMTqReq, base-type=uint16, implementation-data-type=uint16, transfer-property=PENDING
          signal CAN3_Rr_TorqMax: start 47, 12 bit, big-endian, i-signal-type=PRIMITIVE, init-value=constant-reference=Init_CAN3_Rr_TorqMax, base-type=uint16, implementation-data-type=uint16, transfer-property=PENDING
          signal CAN3_Rr_TorqMin: start 51, 12 bit, big-endian, i-signal-type=PRIMITIVE, init-value=constant-reference=Init_CAN3_Rr_TorqMin, base-type=uint16, implementation-data-type=uint16, transfer-property=PENDING
          signal CAN3_Rr_UdcMax: start 71, 12 bit, big-endian, i-signal-type=PRIMITIVE, init-value=constant-reference=Init_CAN3_Rr_UdcMax, base-type=uint16, implementation-data-type=uint16, transfer-property=PENDING
          signal CAN3_Rr_UdcMin: start 75, 12 bit, big-endian, i-signal-type=PRIMITIVE, init-value=constant-reference=Init_CAN3_Rr_UdcMin, base-type=uint16, implementation-data-type=uint16, transfer-property=PENDING
      frame CAN3_FD3_VCU2_toNIDEC: id 0x154, frame-length=24, can-addressing-mode=STANDARD, can-fd-frame-support=true, can-frame-rx-behavior=CAN-FD, can-frame-tx-behavior=CAN-FD
        pdu CAN3_FD3_VCU2_toNIDEC: length=24, minimum-delay=0.0, transmission-mode-true-timing=cyclic-timing=time-period=0.01, unused-bit-pattern=0
          mapping CAN3_SG_FD3_VCU2_toNIDEC: i-signal-group=CAN3_SG_FD3_VCU2_toNIDEC, start-position=0, transfer-property=PENDING
          signal CAN3_CS_VCU2_CAN1_toNidec: start 7, 8 bit, big-endian, i-signal-type=PRIMITIVE, init-value=constant-reference=Init_CAN3_CS_VCU2_CAN1_toNidec, base-type=uint8, implementation-data-type=uint8, transfer-property=PENDING
          signal CAN3_Fr_IdcMax_toNidec: start 151, 12 bit, big-endian, i-signal-type=PRIMITIVE, init-value=constant-reference=Init_CAN3_Fr_IdcMax_toNidec, base-type=uint16, implementation-data-type=uint16, transfer-property=PENDING
          signal CAN3_Fr_IdcMin_toNidec: start 155, 12 bit, big-endian, i-signal-type=PRIMITIVE, init-value=constant-reference=Init_CAN3_Fr_IdcMin_toNidec, base-type=uint16, implementation-data-type=uint16, transfer-property=PENDING
          signal CAN3_Fr_TMTqReq_toNidec: start 135, 16 bit, big-endian, i-signal-type=PRIMITIVE, init-value=constant-reference=Init_CAN3_Fr_TMTqReq_toNidec, base-type=uint16, implementation-data-type=uint16, transfer-property=PENDING
          signal CAN3_Fr_TorqMax_toNidec: start 175, 12 bit, big-endian, i-signal-type=PRIMITIVE, init-value=constant-reference=Init_CAN3_Fr_TorqMax_toNidec, base-type=uint16, implementation-data-type=uint16, transfer-property=PENDING
          signal CAN3_Fr_TorqMin_toNidec: start 179, 12 bit, big-endian, i-signal-type=PRIMITIVE, init-value=constant-reference=Init_CAN3_Fr_TorqMin_toNidec, base-type=uint16, implementation-data-type=uint16, transfer-property=PENDING
          signal CAN3_Fr_UdcMax_toNidec: start 95, 12 bit, big-endian, i-signal-type=PRIMITIVE, init-value=constant-reference=Init_CAN3_Fr_UdcMax_toNidec, base-type=uint16, implementation-data-type=uint16, transfer-property=PENDING
          signal CAN3_Fr_UdcMin_toNidec: start 99, 12 bit, big-endian, i-signal-type=PRIMITIVE, init-value=constant-reference=Init_CAN3_Fr_UdcMin_toNidec, base-type=uint16, implementation-data-type=uint16, transfer-property=PENDING
          signal CAN3_RC_VCU2_CAN1_toNidec: start 15, 4 bit, big-endian, i-signal-type=PRIMITIVE, init-value=constant-reference=Init_CAN3_RC_VCU2_CAN1_toNidec, base-type=uint8, implementation-data-type=uint8, transfer-property=PENDING
          signal CAN3_Rr_IdcMax_toNidec: start 23, 12 bit, big-endian, i-signal-type=PRIMITIVE, init-value=constant-reference=Init_CAN3_Rr_IdcMax_toNidec, base-type=uint16, implementation-data-type=uint16, transfer-property=PENDING
          signal CAN3_Rr_IdcMin_toNidec: start 27, 12 bit, big-endian, i-signal-type=PRIMITIVE, init-value=constant-reference=Init_CAN3_Rr_IdcMin_toNidec, base-type=uint16, implementation-data-type=uint16, transfer-property=PENDING
          signal CAN3_Rr_TMTqReq_toNidec: start 119, 16 bit, big-endian, i-signal-type=PRIMITIVE, init-value=constant-reference=Init_CAN3_Rr_TMTqReq_toNidec, base-type=uint16, implementation-data-type=uint16, transfer-property=PENDING
          signal CAN3_Rr_TorqMax_toNidec: start 47, 12 bit, big-endian, i-signal-type=PRIMITIVE, init-value=constant-reference=Init_CAN3_Rr_TorqMax_toNidec, base-type=uint16, implementation-data-type=uint16, transfer-property=PENDING
          signal CAN3_Rr_TorqMin_toNidec: start 51, 12 bit, big-endian, i-signal-type=PRIMITIVE, init-value=constant-reference=Init_CAN3_Rr_TorqMin_toNidec, base-type=uint16, implementation-data-type=uint16, transfer-property=PENDING
          signal CAN3_Rr_UdcMax_toNidec: start 71, 12 bit, big-endian, i-signal-type=PRIMITIVE, init-value=constant-reference=Init_CAN3_Rr_UdcMax_toNidec, base-type=uint16, implementation-data-type=uint16, transfer-property=PENDING
          signal CAN3_Rr_UdcMin_toNidec: start 75, 12 bit, big-endian, i-signal-type=PRIMITIVE, init-value=constant-reference=Init_CAN3_Rr_UdcMin_toNidec, base-type=uint16, implementation-data-type=uint16, transfer-property=PENDING
      frame CAN3_FD3_VCU4: id 0x15A, frame-length=32, can-addressing-mode=STANDARD, can-fd-frame-support=true, can-frame-rx-behavior=CAN-FD, can-frame-tx-behavior=CAN-FD
        pdu CAN3_FD3_VCU4: length=32, minimum-delay=0.0, transmission-mode-true-timing=cyclic-timing=time-period=0.01, unused-bit-pattern=0
          mapping CAN3_SG_FD3_VCU4: i-signal-group=CAN3_SG_FD3_VCU4, start-position=0, transfer-property=PENDING
          signal CAN3_Fr_SpdMax: start 55, 16 bit, big-endian, i-signal-type=PRIMITIVE, init-value=constant-reference=Init_CAN3_Fr_SpdMax, base-type=uint16, implementation-data-type=uint16, transfer-property=PENDING
          signal CAN3_Fr_SpdMin: start 87, 16 bit, big-endian, i-signal-type=PRIMITIVE, init-value=constant-reference=Init_CAN3_Fr_SpdMin, base-type=uint16, implementation-data-type=uint16, transfer-property=PENDING
          signal CAN3_Fr_TMCtrlMode_Req: start 119, 1 bit, big-endian, i-signal-type=PRIMITIVE, init-value=constant-reference=Init_CAN3_Fr_TMCtrlMode_Req, base-type=uint8, implementation-data-type=uint8, transfer-property=PENDING
          signal CAN3_Fr_TMSpdReq: start 23, 16 bit, big-endian, i-signal-type=PRIMITIVE, init-value=constant-reference=Init_CAN3_Fr_TMSpdReq, base-type=uint16, implementation-data-type=uint16, transfer-property=PENDING
          signal CAN3_Rr_SpdMax: start 71, 16 bit, big-endian, i-signal-type=PRIMITIVE, init-value=constant-reference=Init_CAN3_Rr_SpdMax, base-type=uint16, implementation-data-type=uint16, transfer-property=PENDING
          signal CAN3_Rr_SpdMin: start 103, 16 bit, big-endian, i-signal-type=PRIMITIVE, init-value=constant-reference=Init_CAN3_Rr_SpdMin, base-type=uint16, implementation-data-type=uint16, transfer-property=PENDING
          signal CAN3_Rr_TMCtrlMode_Req: start 118, 1 bit, big-endian, i-signal-type=PRIMITIVE, init-value=constant-reference=Init_CAN3_Rr_TMCtrlMode_Req, base-type=uint8, implementation-data-type=uint8, transfer-property=PENDING
          signal CAN3_Rr_TMSpdReq: start 39, 16 bit, big-endian, i-signal-type=PRIMITIVE, init-value=constant-reference=Init_CAN3_Rr_TMSpdReq, base-type=uint16, implementation-data-type=uint16, transfer-property=PENDING
      frame CAN3_FD3_VCU5: id 0x155, frame-length=32, can-addressing-mode=STANDARD, can-fd-frame-support=true, can-frame-rx-behavior=CAN-FD, can-frame-tx-behavior=CAN-FD
        pdu CAN3_FD3_VCU5: length=32, minimum-delay=0.0, transmission-mode-true-timing=cyclic-timing=time-period=0.01, unused-bit-pattern=0
          mapping CAN3_SG_FD3_VCU5: i-signal-group=CAN3_SG_FD3_VCU5, start-position=0, transfer-property=PENDING
          signal CAN3_ActAPSPosn: start 39, 8 bit, big-endian, i-signal-type=PRIMITIVE, init-value=constant-reference=Init_CAN3_ActAPSPosn, base-type=uint8, implementation-data-type=uint8, transfer-property=PENDING
          signal CAN3_Fr_EDUSpd: start 19, 12 bit, big-endian, i-signal-type=PRIMITIVE, init-value=constant-reference=Init_CAN3_Fr_EDUSpd, base-type=uint16, implementation-data-type=uint16, transfer-property=PENDING
          signal CAN3_Fr_EDUSpdValid: start 20, 1 bit, big-endian, i-signal-type=PRIMITIVE, init-value=constant-reference=Init_CAN3_Fr_EDUSpdValid, base-type=uint8, implementation-data-type=uint8, transfer-property=PENDING
          signal CAN3_Rr_EDUSpd: start 43, 12 bit, big-endian, i-signal-type=PRIMITIVE, init-value=constant-reference=Init_CAN3_Rr_EDUSpd, base-type=uint16, implementation-data-type=uint16, transfer-property=PENDING
          signal CAN3_Rr_EDUSpdValid: start 21, 1 bit, big-endian, i-signal-type=PRIMITIVE, init-value=constant-reference=Init_CAN3_Rr_EDUSpdValid, base-type=uint8, implementation-data-type=uint8, transfer-property=PENDING
      frame CAN3_GW3_CE100_0: id 0x1C3, frame-length=32, can-addressing-mode=STANDARD, can-fd-frame-support=true, can-frame-rx-behavior=CAN-FD, can-frame-tx-behavior=CAN-FD
        pdu CAN3_GW3_CE100_0: length=32, minimum-delay=0.0, transmission-mode-true-timing={cyclic-timing=time-period=0.1, event-controlled-timing={number-of-repetitions=0, repetition-period=0}}, unused-bit-pattern=0
          mapping CAN3_SG_GW3_CE100_0: i-signal-group=CAN3_SG_GW3_CE100_0, start-position=0, transfer-property=TRIGGERED-ON-CHANGE
          signal CAN3_AC_Chg_Cur_Set: start 102, 7 bit, big-endian, i-signal-type=PRIMITIVE, init-value=constant-reference=Init_CAN3_AC_Chg_Cur_Set, base-type=uint8, implementation-data-type=uint8, transfer-property=TRIGGERED-ON-CHANGE
          signal CAN3_COMP_ActualPwr: start 68, 13 bit, big-endian, i-signal-type=PRIMITIVE, init-value=constant-reference=Init_CAN3_COMP_ActualPwr, base-type=uint16, implementation-data-type=uint16, transfer-property=PENDING
          signal CAN3_COMP_ConCur: start 55, 16 bit, big-endian, i-signal-type=PRIMITIVE, init-value=constant-reference=Init_CAN3_COMP_ConCur, base-type=uint16, implementation-data-type=uint16, transfer-property=PENDING
          signal CAN3_COMP_ConVolt: start 87, 16 bit, big-endian, i-signal-type=PRIMITIVE, init-value=constant-reference=Init_CAN3_COMP_ConVolt, base-type=uint16, implementation-data-type=uint16, transfer-property=PENDING
          signal CAN3_ChargeInletLockSta: start 183, 1 bit, big-endian, i-signal-type=PRIMITIVE, init-value=constant-reference=Init_CAN3_ChargeInletLockSta, base-type=uint8, implementation-data-type=uint8, transfer-property=TRIGGERED-ON-CHANGE
          signal CAN3_Charge_Percent_Set: start 135, 8 bit, big-endian, i-signal-type=PRIMITIVE, init-value=constant-reference=Init_CAN3_Charge_Percent_Set, base-type=uint8, implementation-data-type=uint8, transfer-property=TRIGGERED-ON-CHANGE
          signal CAN3_CrashOutputSts: start 39, 8 bit, big-endian, i-signal-type=PRIMITIVE, init-value=constant-reference=Init_CAN3_CrashOutputSts, base-type=uint8, implementation-data-type=uint8, transfer-property=TRIGGERED-ON-CHANGE
          signal CAN3_DriverSeatBeltCmd: start 148, 1 bit, big-endian, i-signal-type=PRIMITIVE, init-value=constant-reference=Init_CAN3_DriverSeatBeltCmd, base-type=uint8, implementation-data-type=uint8, transfer-property=TRIGGERED-ON-CHANGE
          signal CAN3_IVI_Req_V2L: start 175, 2 bit, big-endian, i-signal-type=PRIMITIVE, init-value=constant-reference=Init_CAN3_IVI_Req_V2L, base-type=uint8, implementation-data-type=uint8, transfer-property=TRIGGERED-ON-CHANGE
          signal CAN3_IVI_Start_Chg_req: start 103, 1 bit, big-endian, i-signal-type=PRIMITIVE, init-value=constant-reference=Init_CAN3_IVI_Start_Chg_req, base-type=uint8, implementation-data-type=uint8, transfer-property=TRIGGERED-ON-CHANGE
          signal CAN3_IVI_Stop_Chg_req: start 143, 1 bit, big-endian, i-signal-type=PRIMITIVE, init-value=constant-reference=Init_CAN3_IVI_Stop_Chg_req, base-type=uint8, implementation-data-type=uint8, transfer-property=TRIGGERED-ON-CHANGE
          signal CAN3_IVI_Time_Day: start 228, 5 bit, big-endian, i-signal-type=PRIMITIVE, init-value=constant-reference=Init_CAN3_IVI_Time_Day, base-type=uint8, implementation-data-type=uint8, transfer-property=PENDING
          signal CAN3_IVI_Time_Hour: start 236, 5 bit, big-endian, i-signal-type=PRIMITIVE, init-value=constant-reference=Init_CAN3_IVI_Time_Hour, base-type=uint8, implementation-data-type=uint8, transfer-property=PENDING
          signal CAN3_IVI_Time_Minute: start 245, 6 bit, big-endian, i-signal-type=PRIMITIVE, init-value=constant-reference=Init_CAN3_IVI_Time_Minute, base-type=uint8, implementation-data-type=uint8, transfer-property=PENDING
          signal CAN3_IVI_Time_Month: start 219, 4 bit, big-endian, i-signal-type=PRIMITIVE, init-value=constant-reference=Init_CAN3_IVI_Time_Month, base-type=uint8, implementation-data-type=uint8, transfer-property=PENDING
          signal CAN3_IVI_Time_Second: start 253, 6 bit, big-endian, i-signal-type=PRIMITIVE, init-value=constant-reference=Init_CAN3_IVI_Time_Second, base-type=uint8, implementation-data-type=uint8, transfer-property=PENDING
          signal CAN3_IVI_Unlock_Chg_req: start 127, 1 bit, big-endian, i-signal-type=PRIMITIVE, init-value=constant-reference=Init_CAN3_IVI_Unlock_Chg_req, base-type=uint8, implementation-data-type=uint8, transfer-property=TRIGGERED-ON-CHANGE
          signal CAN3_PTC1_PowerConsumption: start 47, 8 bit, big-endian, i-signal-type=PRIMITIVE, init-value=constant-reference=Init_CAN3_PTC1_PowerConsumption, base-type=uint8, implementation-data-type=uint8, transfer-property=PENDING
          signal CAN3_Perd_V2L: start 119, 4 bit, big-endian, i-signal-type=PRIMITIVE, init-value=constant-reference=Init_CAN3_Perd_V2L, base-type=uint8, implementation-data-type=uint8, transfer-property=PENDING
          signal CAN3_ReserveChargeOFF_Day: start 156, 5 bit, big-endian, i-signal-type=PRIMITIVE, init-value=constant-reference=Init_CAN3_ReserveChargeOFF_Day, base-type=uint8, implementation-data-type=uint8, transfer-property=PENDING
          signal CAN3_ReserveChargeOFF_Hour: start 164, 5 bit, big-endian, i-signal-type=PRIMITIVE, init-value=constant-reference=Init_CAN3_ReserveChargeOFF_Hour, base-type=uint8, implementation-data-type=uint8, transfer-property=PENDING
          signal CAN3_ReserveChargeOFF_Minute: start 173, 6 bit, big-endian, i-signal-type=PRIMITIVE, init-value=constant-reference=Init_CAN3_ReserveChargeOFF_Minute, base-type=uint8, implementation-data-type=uint8, transfer-property=PENDING
          signal CAN3_ReserveChargeOFF_Month: start 147, 4 bit, big-endian, i-signal-type=PRIMITIVE, init-value=constant-reference=Init_CAN3_ReserveChargeOFF_Month, base-type=uint8, implementation-data-type=uint8, transfer-property=PENDING
          signal CAN3_ReserveChargeOFF_Year: start 142, 7 bit, big-endian, i-signal-type=PRIMITIVE, init-value=constant-reference=Init_CAN3_ReserveChargeOFF_Year, base-type=uint8, implementation-data-type=uint8, transfer-property=PENDING
          signal CAN3_ReserveChargeOn_Day: start 196, 5 bit, big-endian, i-signal-type=PRIMITIVE, init-value=constant-reference=Init_CAN3_ReserveChargeOn_Day, base-type=uint8, implementation-data-type=uint8, transfer-property=PENDING
          signal CAN3_ReserveChargeOn_Hour: start 204, 5 bit, big-endian, i-signal-type=PRIMITIVE, init-value=constant-reference=Init_CAN3_ReserveChargeOn_Hour, base-type=uint8, implementation-data-type=uint8, transfer-property=PENDING
          signal CAN3_ReserveChargeOn_Minute: start 213, 6 bit, big-endian, i-signal-type=PRIMITIVE, init-value=constant-reference=Init_CAN3_ReserveChargeOn_Minute, base-type=uint8, implementation-data-type=uint8, transfer-property=PENDING
          signal CAN3_ReserveChargeOn_Month: start 187, 4 bit, big-endian, i-signal-type=PRIMITIVE, init-value=constant-reference=Init_CAN3_ReserveChargeOn_Month, base-type=uint8, implementation-data-type=uint8, transfer-property=PENDING
          signal CAN3_ReserveChargeOn_Year: start 182, 7 bit, big-endian, i-signal-type=PRIMITIVE, init-value=constant-reference=Init_CAN3_ReserveChargeOn_Year, base-type=uint8, implementation-data-type=uint8, transfer-property=PENDING
          signal CAN3_SOC_ADJ_BUTT: start 125, 1 bit, big-endian, i-signal-type=PRIMITIVE, init-value=constant-reference=Init_CAN3_SOC_ADJ_BUTT, base-type=uint8, implementation-data-type=uint8, transfer-property=TRIGGERED-ON-CHANGE
          signal CAN3_SOC_Limit_Set: start 108, 5 bit, big-endian, i-signal-type=PRIMITIVE, init-value=constant-reference=Init_CAN3_SOC_Limit_Set, base-type=uint8, implementation-data-type=uint8, transfer-property=PENDING
          signal CAN3_SOC_V2LLimit: start 115, 4 bit, big-endian, i-signal-type=PRIMITIVE, init-value=constant-reference=Init_CAN3_SOC_V2LLimit, base-type=uint8, implementation-data-type=uint8, transfer-property=PENDING
          signal CAN3_Sched_Chg_Start: start 109, 1 bit, big-endian, i-signal-type=PRIMITIVE, init-value=constant-reference=Init_CAN3_Sched_Chg_Start, base-type=uint8, implementation-data-type=uint8, transfer-property=TRIGGERED-ON-CHANGE
          signal CAN3_Sched_Chg_Stop: start 111, 1 bit, big-endian, i-signal-type=PRIMITIVE, init-value=constant-reference=Init_CAN3_Sched_Chg_Stop, base-type=uint8, implementation-data-type=uint8, transfer-property=TRIGGERED-ON-CHANGE
          signal CAN3_Sched_Chg_butt: start 110, 1 bit, big-endian, i-signal-type=PRIMITIVE, init-value=constant-reference=Init_CAN3_Sched_Chg_butt, base-type=uint8, implementation-data-type=uint8, transfer-property=TRIGGERED-ON-CHANGE
          signal CAN3_Sched_Chg_limit: start 124, 5 bit, big-endian, i-signal-type=PRIMITIVE, init-value=constant-reference=Init_CAN3_Sched_Chg_limit, base-type=uint8, implementation-data-type=uint8, transfer-property=PENDING
          signal CAN3_VehSpeed: start 19, 12 bit, big-endian, i-signal-type=PRIMITIVE, init-value=constant-reference=Init_CAN3_VehSpeed, base-type=uint16, implementation-data-type=uint16, transfer-property=PENDING
      frame CAN3_GW_ESC1_toNIDEC: id 0x152, frame-length=8, can-addressing-mode=STANDARD, can-fd-frame-support=true, can-frame-rx-behavior=CAN-FD, can-frame-tx-behavior=CAN-FD
        pdu CAN3_GW_ESC1_toNIDEC: length=8, minimum-delay=0.0, transmission-mode-true-timing=cyclic-timing=time-period=0.01, unused-bit-pattern=0
          mapping CAN3_SG_GW_ESC1_toNIDEC: i-signal-group=CAN3_SG_GW_ESC1_toNIDEC, start-position=0, transfer-property=PENDING
          signal CAN3_VehSpeed_toNidec: start 19, 12 bit, big-endian, i-signal-type=PRIMITIVE, init-value=constant-reference=Init_CAN3_VehSpeed_toNidec, base-type=uint16, implementation-data-type=uint16, transfer-property=PENDING
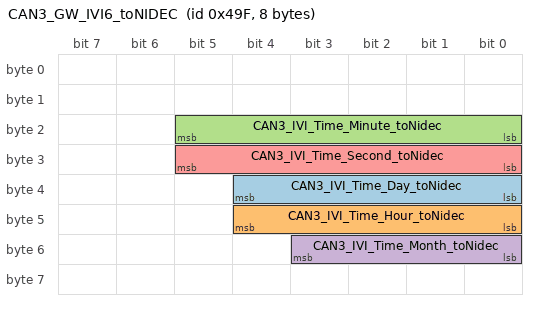
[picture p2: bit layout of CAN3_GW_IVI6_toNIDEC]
      frame CAN3_GW_IVI6_toNIDEC: id 0x49F, frame-length=8, can-addressing-mode=STANDARD, can-fd-frame-support=true, can-frame-rx-behavior=CAN-FD, can-frame-tx-behavior=CAN-FD
        pdu CAN3_GW_IVI6_toNIDEC: length=8, minimum-delay=0.0, transmission-mode-true-timing=cyclic-timing=time-period=1, unused-bit-pattern=0
          mapping CAN3_SG_GW_IVI6_toNIDEC: i-signal-group=CAN3_SG_GW_IVI6_toNIDEC, start-position=0, transfer-property=PENDING
          signal CAN3_IVI_Time_Day_toNidec: start 36, 5 bit, big-endian, i-signal-type=PRIMITIVE, init-value=constant-reference=Init_CAN3_IVI_Time_Day_toNidec, base-type=uint8, implementation-data-type=uint8, transfer-property=PENDING
          signal CAN3_IVI_Time_Hour_toNidec: start 44, 5 bit, big-endian, i-signal-type=PRIMITIVE, init-value=constant-reference=Init_CAN3_IVI_Time_Hour_toNidec, base-type=uint8, implementation-data-type=uint8, transfer-property=PENDING
          signal CAN3_IVI_Time_Minute_toNidec: start 21, 6 bit, big-endian, i-signal-type=PRIMITIVE, init-value=constant-reference=Init_CAN3_IVI_Time_Minute_toNidec, base-type=uint8, implementation-data-type=uint8, transfer-property=PENDING
          signal CAN3_IVI_Time_Month_toNidec: start 51, 4 bit, big-endian, i-signal-type=PRIMITIVE, init-value=constant-reference=Init_CAN3_IVI_Time_Month_toNidec, base-type=uint8, implementation-data-type=uint8, transfer-property=PENDING
          signal CAN3_IVI_Time_Second_toNidec: start 29, 6 bit, big-endian, i-signal-type=PRIMITIVE, init-value=constant-reference=Init_CAN3_IVI_Time_Second_toNidec, base-type=uint8, implementation-data-type=uint8, transfer-property=PENDING
      frame CAN3_MCU_B_F1: id 0x191, frame-length=32, can-addressing-mode=STANDARD, can-fd-frame-support=true, can-frame-rx-behavior=CAN-FD, can-frame-tx-behavior=CAN-FD
        pdu CAN3_MCU_B_F1: length=32, minimum-delay=0.0, transmission-mode-true-timing=cyclic-timing=time-period=0.01, unused-bit-pattern=0
          mapping CAN3_SG_MCU_B_F1: i-signal-group=CAN3_SG_MCU_B_F1, start-position=0, transfer-property=PENDING
          signal CAN3_Fr_ActvDmpDisabSta: start 201, 1 bit, big-endian, i-signal-type=PRIMITIVE, init-value=constant-reference=Init_CAN3_Fr_ActvDmpDisabSta, base-type=uint8, implementation-data-type=uint8, transfer-property=PENDING
          signal CAN3_Fr_EDUDrtSta: start 202, 1 bit, big-endian, i-signal-type=PRIMITIVE, init-value=constant-reference=Init_CAN3_Fr_EDUDrtSta, base-type=uint8, implementation-data-type=uint8, transfer-property=PENDING
          signal CAN3_Fr_EDUOpratingSta: start 245, 1 bit, big-endian, i-signal-type=PRIMITIVE, init-value=constant-reference=Init_CAN3_Fr_EDUOpratingSta, base-type=uint8, implementation-data-type=uint8, transfer-property=PENDING
          signal CAN3_Fr_EDURealTMTq: start 227, 12 bit, big-endian, i-signal-type=PRIMITIVE, init-value=constant-reference=Init_CAN3_Fr_EDURealTMTq, base-type=uint16, implementation-data-type=uint16, transfer-property=PENDING
          signal CAN3_Fr_EDURotateDirction: start 247, 2 bit, big-endian, i-signal-type=PRIMITIVE, init-value=constant-reference=Init_CAN3_Fr_EDURotateDirction, base-type=uint8, implementation-data-type=uint8, transfer-property=PENDING
          signal CAN3_Fr_EDUTqReqFbk: start 243, 12 bit, big-endian, i-signal-type=PRIMITIVE, init-value=constant-reference=Init_CAN3_Fr_EDUTqReqFbk, base-type=uint16, implementation-data-type=uint16, transfer-property=PENDING
          signal CAN3_Fr_MCU1Chksum: start 7, 8 bit, big-endian, i-signal-type=PRIMITIVE, init-value=constant-reference=Init_CAN3_Fr_MCU1Chksum, base-type=uint8, implementation-data-type=uint8, transfer-property=PENDING
          signal CAN3_Fr_MCU1RolCnt: start 11, 4 bit, big-endian, i-signal-type=PRIMITIVE, init-value=constant-reference=Init_CAN3_Fr_MCU1RolCnt, base-type=uint8, implementation-data-type=uint8, transfer-property=PENDING
          signal CAN3_Fr_MCUBAT: start 71, 8 bit, big-endian, i-signal-type=PRIMITIVE, init-value=constant-reference=Init_CAN3_Fr_MCUBAT, base-type=uint8, implementation-data-type=uint8, transfer-property=PENDING
          signal CAN3_Fr_MCUDCBusCurr: start 174, 15 bit, big-endian, i-signal-type=PRIMITIVE, init-value=constant-reference=Init_CAN3_Fr_MCUDCBusCurr, base-type=uint16, implementation-data-type=uint16, transfer-property=PENDING
          signal CAN3_Fr_MCUDCBusVolt: start 191, 16 bit, big-endian, i-signal-type=PRIMITIVE, init-value=constant-reference=Init_CAN3_Fr_MCUDCBusVolt, base-type=uint16, implementation-data-type=uint16, transfer-property=PENDING
          signal CAN3_Fr_MCUDischrgSta: start 203, 1 bit, big-endian, i-signal-type=PRIMITIVE, init-value=constant-reference=Init_CAN3_Fr_MCUDischrgSta, base-type=uint8, implementation-data-type=uint8, transfer-property=PENDING
          signal CAN3_Fr_MCUEnaSta: start 244, 1 bit, big-endian, i-signal-type=PRIMITIVE, init-value=constant-reference=Init_CAN3_Fr_MCUEnaSta, base-type=uint8, implementation-data-type=uint8, transfer-property=PENDING
          signal CAN3_Fr_MCUErr: start 143, 8 bit, big-endian, i-signal-type=PRIMITIVE, init-value=constant-reference=Init_CAN3_Fr_MCUErr, base-type=uint8, implementation-data-type=uint8, transfer-property=PENDING
          signal CAN3_Fr_MCUIGN_sta: start 72, 1 bit, big-endian, i-signal-type=PRIMITIVE, init-value=constant-reference=Init_CAN3_Fr_MCUIGN_sta, base-type=uint8, implementation-data-type=uint8, transfer-property=PENDING
          signal CAN3_Fr_MCUReady: start 63, 1 bit, big-endian, i-signal-type=PRIMITIVE, init-value=constant-reference=Init_CAN3_Fr_MCUReady, base-type=uint8, implementation-data-type=uint8, transfer-property=PENDING
          signal CAN3_Fr_MCUReady4Pre: start 200, 1 bit, big-endian, i-signal-type=PRIMITIVE, init-value=constant-reference=Init_CAN3_Fr_MCUReady4Pre, base-type=uint8, implementation-data-type=uint8, transfer-property=PENDING
          signal CAN3_Fr_MCUSysSta: start 59, 4 bit, big-endian, i-signal-type=PRIMITIVE, init-value=constant-reference=Init_CAN3_Fr_MCUSysSta, base-type=uint8, implementation-data-type=uint8, transfer-property=PENDING
          signal CAN3_Fr_MCUTemp: start 167, 9 bit, big-endian, i-signal-type=PRIMITIVE, init-value=constant-reference=Init_CAN3_Fr_MCUTemp, base-type=uint16, implementation-data-type=uint16, transfer-property=PENDING
          signal CAN3_Fr_MotorAvailTq: start 91, 12 bit, big-endian, i-signal-type=PRIMITIVE, init-value=constant-reference=Init_CAN3_Fr_MotorAvailTq, base-type=uint16, implementation-data-type=uint16, transfer-property=PENDING
          signal CAN3_Fr_RegenAvailTq: start 87, 12 bit, big-endian, i-signal-type=PRIMITIVE, init-value=constant-reference=Init_CAN3_Fr_RegenAvailTq, base-type=uint16, implementation-data-type=uint16, transfer-property=PENDING
          signal CAN3_Fr_Reserved_bits: start 79, 7 bit, big-endian, i-signal-type=PRIMITIVE, init-value=constant-reference=Init_CAN3_Fr_Reserved_bits, base-type=uint8, implementation-data-type=uint8, transfer-property=PENDING
          signal CAN3_Fr_TMSpd: start 215, 16 bit, big-endian, i-signal-type=PRIMITIVE, init-value=constant-reference=Init_CAN3_Fr_TMSpd, base-type=uint16, implementation-data-type=uint16, transfer-property=PENDING
          signal CAN3_Fr_TMTemp: start 144, 9 bit, big-endian, i-signal-type=PRIMITIVE, init-value=constant-reference=Init_CAN3_Fr_TMTemp, base-type=uint16, implementation-data-type=uint16, transfer-property=PENDING
          signal CAN3_Fr_TMid: start 126, 15 bit, big-endian, i-signal-type=PRIMITIVE, init-value=constant-reference=Init_CAN3_Fr_TMid, base-type=uint16, implementation-data-type=uint16, transfer-property=PENDING
          signal CAN3_Fr_TMiq: start 110, 15 bit, big-endian, i-signal-type=PRIMITIVE, init-value=constant-reference=Init_CAN3_Fr_TMiq, base-type=uint16, implementation-data-type=uint16, transfer-property=PENDING
          signal CAN3_MCUWarn_F: start 62, 3 bit, big-endian, i-signal-type=PRIMITIVE, init-value=constant-reference=Init_CAN3_MCUWarn_F, base-type=uint8, implementation-data-type=uint8, transfer-property=PENDING
      frame CAN3_MCU_B_F2: id 0x194, frame-length=16, can-addressing-mode=STANDARD, can-fd-frame-support=true, can-frame-rx-behavior=CAN-FD, can-frame-tx-behavior=CAN-FD
        pdu CAN3_MCU_B_F2: length=16, minimum-delay=0.0, transmission-mode-true-timing=cyclic-timing=time-period=0.01, unused-bit-pattern=0
          mapping CAN3_SG_MCU_B_F2: i-signal-group=CAN3_SG_MCU_B_F2, start-position=0, transfer-property=PENDING
          signal CAN3_Fr_CoolanttempReq: start 24, 9 bit, big-endian, i-signal-type=PRIMITIVE, init-value=constant-reference=Init_CAN3_Fr_CoolanttempReq, base-type=uint16, implementation-data-type=uint16, transfer-property=PENDING
          signal CAN3_Fr_Failcode1: start 63, 8 bit, big-endian, i-signal-type=PRIMITIVE, init-value=constant-reference=Init_CAN3_Fr_Failcode1, base-type=uint8, implementation-data-type=uint8, transfer-property=PENDING
          signal CAN3_Fr_Failcode2: start 55, 8 bit, big-endian, i-signal-type=PRIMITIVE, init-value=constant-reference=Init_CAN3_Fr_Failcode2, base-type=uint8, implementation-data-type=uint8, transfer-property=PENDING
          signal CAN3_Fr_Failcodehistory1: start 41, 2 bit, big-endian, i-signal-type=PRIMITIVE, init-value=constant-reference=Init_CAN3_Fr_Failcodehistory1, base-type=uint8, implementation-data-type=uint8, transfer-property=PENDING
          signal CAN3_Fr_Failcodehistory2: start 43, 2 bit, big-endian, i-signal-type=PRIMITIVE, init-value=constant-reference=Init_CAN3_Fr_Failcodehistory2, base-type=uint8, implementation-data-type=uint8, transfer-property=PENDING
          signal CAN3_Fr_LLCTemp: start 80, 9 bit, big-endian, i-signal-type=PRIMITIVE, init-value=constant-reference=Init_CAN3_Fr_LLCTemp, base-type=uint16, implementation-data-type=uint16, transfer-property=PENDING
          signal CAN3_Fr_LLCflowReq: start 21, 6 bit, big-endian, i-signal-type=PRIMITIVE, init-value=constant-reference=Init_CAN3_Fr_LLCflowReq, base-type=uint8, implementation-data-type=uint8, transfer-property=PENDING
          signal CAN3_Fr_MCU2Chksum: start 7, 8 bit, big-endian, i-signal-type=PRIMITIVE, init-value=constant-reference=Init_CAN3_Fr_MCU2Chksum, base-type=uint8, implementation-data-type=uint8, transfer-property=PENDING
          signal CAN3_Fr_MCU2RolCnt: start 11, 4 bit, big-endian, i-signal-type=PRIMITIVE, init-value=constant-reference=Init_CAN3_Fr_MCU2RolCnt, base-type=uint8, implementation-data-type=uint8, transfer-property=PENDING
          signal CAN3_Fr_MCUTempWarn: start 47, 2 bit, big-endian, i-signal-type=PRIMITIVE, init-value=constant-reference=Init_CAN3_Fr_MCUTempWarn, base-type=uint8, implementation-data-type=uint8, transfer-property=PENDING
          signal CAN3_Fr_MCU_HW_Ver: start 103, 16 bit, big-endian, i-signal-type=PRIMITIVE, init-value=constant-reference=Init_CAN3_Fr_MCU_HW_Ver, base-type=uint16, implementation-data-type=uint16, transfer-property=PENDING
          signal CAN3_Fr_MCU_SW_Ver: start 119, 16 bit, big-endian, i-signal-type=PRIMITIVE, init-value=constant-reference=Init_CAN3_Fr_MCU_SW_Ver, base-type=uint16, implementation-data-type=uint16, transfer-property=PENDING
          signal CAN3_Fr_TMTempWarn: start 45, 2 bit, big-endian, i-signal-type=PRIMITIVE, init-value=constant-reference=Init_CAN3_Fr_TMTempWarn, base-type=uint8, implementation-data-type=uint8, transfer-property=PENDING
          signal CAN3_MCU_B_F_FailLv_Sta: start 27, 3 bit, big-endian, i-signal-type=PRIMITIVE, init-value=constant-reference=Init_CAN3_MCU_B_F_FailLv_Sta, base-type=uint8, implementation-data-type=uint8, transfer-property=PENDING
          signal CAN3_MCU_B_F_LLCTempWarn_Sta: start 23, 2 bit, big-endian, i-signal-type=PRIMITIVE, init-value=constant-reference=Init_CAN3_MCU_B_F_LLCTempWarn_Sta, base-type=uint8, implementation-data-type=uint8, transfer-property=PENDING
      frame CAN3_MCU_B_R1: id 0x190, frame-length=32, can-addressing-mode=STANDARD, can-fd-frame-support=true, can-frame-rx-behavior=CAN-FD, can-frame-tx-behavior=CAN-FD
        pdu CAN3_MCU_B_R1: length=32, minimum-delay=0.0, transmission-mode-true-timing=cyclic-timing=time-period=0.01, unused-bit-pattern=0
          mapping CAN3_SG_MCU_B_R1: i-signal-group=CAN3_SG_MCU_B_R1, start-position=0, transfer-property=PENDING
          signal CAN3_MCUWarn_R: start 62, 3 bit, big-endian, i-signal-type=PRIMITIVE, init-value=constant-reference=Init_CAN3_MCUWarn_R, base-type=uint8, implementation-data-type=uint8, transfer-property=PENDING
          signal CAN3_Rr_ActvDmpDisabSta: start 201, 1 bit, big-endian, i-signal-type=PRIMITIVE, init-value=constant-reference=Init_CAN3_Rr_ActvDmpDisabSta, base-type=uint8, implementation-data-type=uint8, transfer-property=PENDING
          signal CAN3_Rr_EDUDrtSta: start 202, 1 bit, big-endian, i-signal-type=PRIMITIVE, init-value=constant-reference=Init_CAN3_Rr_EDUDrtSta, base-type=uint8, implementation-data-type=uint8, transfer-property=PENDING
          signal CAN3_Rr_EDUOpratingSta: start 245, 1 bit, big-endian, i-signal-type=PRIMITIVE, init-value=constant-reference=Init_CAN3_Rr_EDUOpratingSta, base-type=uint8, implementation-data-type=uint8, transfer-property=PENDING
          signal CAN3_Rr_EDURealTMTq: start 227, 12 bit, big-endian, i-signal-type=PRIMITIVE, init-value=constant-reference=Init_CAN3_Rr_EDURealTMTq, base-type=uint16, implementation-data-type=uint16, transfer-property=PENDING
          signal CAN3_Rr_EDURotateDirction: start 247, 2 bit, big-endian, i-signal-type=PRIMITIVE, init-value=constant-reference=Init_CAN3_Rr_EDURotateDirction, base-type=uint8, implementation-data-type=uint8, transfer-property=PENDING
          signal CAN3_Rr_EDUTqReqFbk: start 243, 12 bit, big-endian, i-signal-type=PRIMITIVE, init-value=constant-reference=Init_CAN3_Rr_EDUTqReqFbk, base-type=uint16, implementation-data-type=uint16, transfer-property=PENDING
          signal CAN3_Rr_MCU1Chksum: start 7, 8 bit, big-endian, i-signal-type=PRIMITIVE, init-value=constant-reference=Init_CAN3_Rr_MCU1Chksum, base-type=uint8, implementation-data-type=uint8, transfer-property=PENDING
          signal CAN3_Rr_MCU1RolCnt: start 11, 4 bit, big-endian, i-signal-type=PRIMITIVE, init-value=constant-reference=Init_CAN3_Rr_MCU1RolCnt, base-type=uint8, implementation-data-type=uint8, transfer-property=PENDING
          signal CAN3_Rr_MCUBAT: start 71, 8 bit, big-endian, i-signal-type=PRIMITIVE, init-value=constant-reference=Init_CAN3_Rr_MCUBAT, base-type=uint8, implementation-data-type=uint8, transfer-property=PENDING
          signal CAN3_Rr_MCUDCBusCurr: start 174, 15 bit, big-endian, i-signal-type=PRIMITIVE, init-value=constant-reference=Init_CAN3_Rr_MCUDCBusCurr, base-type=uint16, implementation-data-type=uint16, transfer-property=PENDING
          signal CAN3_Rr_MCUDCBusVolt: start 191, 16 bit, big-endian, i-signal-type=PRIMITIVE, init-value=constant-reference=Init_CAN3_Rr_MCUDCBusVolt, base-type=uint16, implementation-data-type=uint16, transfer-property=PENDING
          signal CAN3_Rr_MCUDischrgSta: start 203, 1 bit, big-endian, i-signal-type=PRIMITIVE, init-value=constant-reference=Init_CAN3_Rr_MCUDischrgSta, base-type=uint8, implementation-data-type=uint8, transfer-property=PENDING
          signal CAN3_Rr_MCUEnaSta: start 244, 1 bit, big-endian, i-signal-type=PRIMITIVE, init-value=constant-reference=Init_CAN3_Rr_MCUEnaSta, base-type=uint8, implementation-data-type=uint8, transfer-property=PENDING
          signal CAN3_Rr_MCUErr: start 143, 8 bit, big-endian, i-signal-type=PRIMITIVE, init-value=constant-reference=Init_CAN3_Rr_MCUErr, base-type=uint8, implementation-data-type=uint8, transfer-property=PENDING
          signal CAN3_Rr_MCUIGN_sta: start 72, 1 bit, big-endian, i-signal-type=PRIMITIVE, init-value=constant-reference=Init_CAN3_Rr_MCUIGN_sta, base-type=uint8, implementation-data-type=uint8, transfer-property=PENDING
          signal CAN3_Rr_MCUReady: start 63, 1 bit, big-endian, i-signal-type=PRIMITIVE, init-value=constant-reference=Init_CAN3_Rr_MCUReady, base-type=uint8, implementation-data-type=uint8, transfer-property=PENDING
          signal CAN3_Rr_MCUReady4Pre: start 200, 1 bit, big-endian, i-signal-type=PRIMITIVE, init-value=constant-reference=Init_CAN3_Rr_MCUReady4Pre, base-type=uint8, implementation-data-type=uint8, transfer-property=PENDING
          signal CAN3_Rr_MCUSysSta: start 59, 4 bit, big-endian, i-signal-type=PRIMITIVE, init-value=constant-reference=Init_CAN3_Rr_MCUSysSta, base-type=uint8, implementation-data-type=uint8, transfer-property=PENDING
          signal CAN3_Rr_MCUTemp: start 167, 9 bit, big-endian, i-signal-type=PRIMITIVE, init-value=constant-reference=Init_CAN3_Rr_MCUTemp, base-type=uint16, implementation-data-type=uint16, transfer-property=PENDING
          signal CAN3_Rr_MotorAvailTq: start 91, 12 bit, big-endian, i-signal-type=PRIMITIVE, init-value=constant-reference=Init_CAN3_Rr_MotorAvailTq, base-type=uint16, implementation-data-type=uint16, transfer-property=PENDING
          signal CAN3_Rr_RegenAvailTq: start 87, 12 bit, big-endian, i-signal-type=PRIMITIVE, init-value=constant-reference=Init_CAN3_Rr_RegenAvailTq, base-type=uint16, implementation-data-type=uint16, transfer-property=PENDING
          signal CAN3_Rr_Reserved_bits: start 79, 7 bit, big-endian, i-signal-type=PRIMITIVE, init-value=constant-reference=Init_CAN3_Rr_Reserved_bits, base-type=uint8, implementation-data-type=uint8, transfer-property=PENDING
          signal CAN3_Rr_TMSpd: start 215, 16 bit, big-endian, i-signal-type=PRIMITIVE, init-value=constant-reference=Init_CAN3_Rr_TMSpd, base-type=uint16, implementation-data-type=uint16, transfer-property=PENDING
          signal CAN3_Rr_TMTemp: start 144, 9 bit, big-endian, i-signal-type=PRIMITIVE, init-value=constant-reference=Init_CAN3_Rr_TMTemp, base-type=uint16, implementation-data-type=uint16, transfer-property=PENDING
          signal CAN3_Rr_TMid: start 126, 15 bit, big-endian, i-signal-type=PRIMITIVE, init-value=constant-reference=Init_CAN3_Rr_TMid, base-type=uint16, implementation-data-type=uint16, transfer-property=PENDING
          signal CAN3_Rr_TMiq: start 110, 15 bit, big-endian, i-signal-type=PRIMITIVE, init-value=constant-reference=Init_CAN3_Rr_TMiq, base-type=uint16, implementation-data-type=uint16, transfer-property=PENDING
      frame CAN3_MCU_B_R2: id 0x193, frame-length=16, can-addressing-mode=STANDARD, can-fd-frame-support=true, can-frame-rx-behavior=CAN-FD, can-frame-tx-behavior=CAN-FD
        pdu CAN3_MCU_B_R2: length=16, minimum-delay=0.0, transmission-mode-true-timing=cyclic-timing=time-period=0.01, unused-bit-pattern=0
          mapping CAN3_SG_MCU_B_R2: i-signal-group=CAN3_SG_MCU_B_R2, start-position=0, transfer-property=PENDING
          signal CAN3_MCU_B_R_FailLv_Sta: start 27, 3 bit, big-endian, i-signal-type=PRIMITIVE, init-value=constant-reference=Init_CAN3_MCU_B_R_FailLv_Sta, base-type=uint8, implementation-data-type=uint8, transfer-property=PENDING
          signal CAN3_MCU_B_R_LLCTempWarn_Sta: start 23, 2 bit, big-endian, i-signal-type=PRIMITIVE, init-value=constant-reference=Init_CAN3_MCU_B_R_LLCTempWarn_Sta, base-type=uint8, implementation-data-type=uint8, transfer-property=PENDING
          signal CAN3_Rr_CoolanttempReq: start 24, 9 bit, big-endian, i-signal-type=PRIMITIVE, init-value=constant-reference=Init_CAN3_Rr_CoolanttempReq, base-type=uint16, implementation-data-type=uint16, transfer-property=PENDING
          signal CAN3_Rr_Failcode1: start 63, 8 bit, big-endian, i-signal-type=PRIMITIVE, init-value=constant-reference=Init_CAN3_Rr_Failcode1, base-type=uint8, implementation-data-type=uint8, transfer-property=PENDING
          signal CAN3_Rr_Failcode2: start 55, 8 bit, big-endian, i-signal-type=PRIMITIVE, init-value=constant-reference=Init_CAN3_Rr_Failcode2, base-type=uint8, implementation-data-type=uint8, transfer-property=PENDING
          signal CAN3_Rr_Failcodehistory1: start 41, 2 bit, big-endian, i-signal-type=PRIMITIVE, init-value=constant-reference=Init_CAN3_Rr_Failcodehistory1, base-type=uint8, implementation-data-type=uint8, transfer-property=PENDING
          signal CAN3_Rr_Failcodehistory2: start 43, 2 bit, big-endian, i-signal-type=PRIMITIVE, init-value=constant-reference=Init_CAN3_Rr_Failcodehistory2, base-type=uint8, implementation-data-type=uint8, transfer-property=PENDING
          signal CAN3_Rr_LLCTemp: start 80, 9 bit, big-endian, i-signal-type=PRIMITIVE, init-value=constant-reference=Init_CAN3_Rr_LLCTemp, base-type=uint16, implementation-data-type=uint16, transfer-property=PENDING
          signal CAN3_Rr_LLCflowReq: start 21, 6 bit, big-endian, i-signal-type=PRIMITIVE, init-value=constant-reference=Init_CAN3_Rr_LLCflowReq, base-type=uint8, implementation-data-type=uint8, transfer-property=PENDING
          signal CAN3_Rr_MCU2Chksum: start 7, 8 bit, big-endian, i-signal-type=PRIMITIVE, init-value=constant-reference=Init_CAN3_Rr_MCU2Chksum, base-type=uint8, implementation-data-type=uint8, transfer-property=PENDING
          signal CAN3_Rr_MCU2RolCnt: start 11, 4 bit, big-endian, i-signal-type=PRIMITIVE, init-value=constant-reference=Init_CAN3_Rr_MCU2RolCnt, base-type=uint8, implementation-data-type=uint8, transfer-property=PENDING
          signal CAN3_Rr_MCU3_HW_Ver: start 103, 16 bit, big-endian, i-signal-type=PRIMITIVE, init-value=constant-reference=Init_CAN3_Rr_MCU3_HW_Ver, base-type=uint16, implementation-data-type=uint16, transfer-property=PENDING
          signal CAN3_Rr_MCU3_SW_Ver: start 119, 16 bit, big-endian, i-signal-type=PRIMITIVE, init-value=constant-reference=Init_CAN3_Rr_MCU3_SW_Ver, base-type=uint16, implementation-data-type=uint16, transfer-property=PENDING
          signal CAN3_Rr_MCUTempWarn: start 47, 2 bit, big-endian, i-signal-type=PRIMITIVE, init-value=constant-reference=Init_CAN3_Rr_MCUTempWarn, base-type=uint8, implementation-data-type=uint8, transfer-property=PENDING
          signal CAN3_Rr_TMTempWarn: start 45, 2 bit, big-endian, i-signal-type=PRIMITIVE, init-value=constant-reference=Init_CAN3_Rr_TMTempWarn, base-type=uint8, implementation-data-type=uint8, transfer-property=PENDING
      frame CAN3_MCU_N_F1: id 0x196, frame-length=32, can-addressing-mode=STANDARD, can-fd-frame-support=true, can-frame-rx-behavior=CAN-FD, can-frame-tx-behavior=CAN-FD
        pdu CAN3_MCU_N_F1: length=32, minimum-delay=0.0, transmission-mode-true-timing=cyclic-timing=time-period=0.1, unused-bit-pattern=0
          mapping CAN3_SG_MCU_N_F1: i-signal-group=CAN3_SG_MCU_N_F1, start-position=0, transfer-property=PENDING
          signal CAN3_Fr_ActvDmpDisabSta_Nidec: start 201, 1 bit, big-endian, i-signal-type=PRIMITIVE, init-value=constant-reference=Init_CAN3_Fr_ActvDmpDisabSta_Nidec, base-type=uint8, implementation-data-type=uint8, transfer-property=PENDING
          signal CAN3_Fr_EDUDrtSta_Nidec: start 202, 1 bit, big-endian, i-signal-type=PRIMITIVE, init-value=constant-reference=Init_CAN3_Fr_EDUDrtSta_Nidec, base-type=uint8, implementation-data-type=uint8, transfer-property=PENDING
          signal CAN3_Fr_EDUOpratingSta_Nidec: start 245, 1 bit, big-endian, i-signal-type=PRIMITIVE, init-value=constant-reference=Init_CAN3_Fr_EDUOpratingSta_Nidec, base-type=uint8, implementation-data-type=uint8, transfer-property=PENDING
          signal CAN3_Fr_EDURealTMTq_Nidec: start 227, 12 bit, big-endian, i-signal-type=PRIMITIVE, init-value=constant-reference=Init_CAN3_Fr_EDURealTMTq_Nidec, base-type=uint16, implementation-data-type=uint16, transfer-property=PENDING
          signal CAN3_Fr_EDURotateDirction_Nidec: start 247, 2 bit, big-endian, i-signal-type=PRIMITIVE, init-value=constant-reference=Init_CAN3_Fr_EDURotateDirction_Nidec, base-type=uint8, implementation-data-type=uint8, transfer-property=PENDING
          signal CAN3_Fr_EDUTqReqFbk_Nidec: start 243, 12 bit, big-endian, i-signal-type=PRIMITIVE, init-value=constant-reference=Init_CAN3_Fr_EDUTqReqFbk_Nidec, base-type=uint16, implementation-data-type=uint16, transfer-property=PENDING
          signal CAN3_Fr_MCU1Chksum_Nidec: start 7, 8 bit, big-endian, i-signal-type=PRIMITIVE, init-value=constant-reference=Init_CAN3_Fr_MCU1Chksum_Nidec, base-type=uint8, implementation-data-type=uint8, transfer-property=PENDING
          signal CAN3_Fr_MCU1RolCnt_Nidec: start 15, 4 bit, big-endian, i-signal-type=PRIMITIVE, init-value=constant-reference=Init_CAN3_Fr_MCU1RolCnt_Nidec, base-type=uint8, implementation-data-type=uint8, transfer-property=PENDING
          signal CAN3_Fr_MCUBAT_Nidec: start 71, 8 bit, big-endian, i-signal-type=PRIMITIVE, init-value=constant-reference=Init_CAN3_Fr_MCUBAT_Nidec, base-type=uint8, implementation-data-type=uint8, transfer-property=PENDING
          signal CAN3_Fr_MCUDCBusCurr_Nidec: start 174, 15 bit, big-endian, i-signal-type=PRIMITIVE, init-value=constant-reference=Init_CAN3_Fr_MCUDCBusCurr_Nidec, base-type=uint16, implementation-data-type=uint16, transfer-property=PENDING
          signal CAN3_Fr_MCUDCBusVolt_Nidec: start 191, 16 bit, big-endian, i-signal-type=PRIMITIVE, init-value=constant-reference=Init_CAN3_Fr_MCUDCBusVolt_Nidec, base-type=uint16, implementation-data-type=uint16, transfer-property=PENDING
          signal CAN3_Fr_MCUDischrgSta_Nidec: start 203, 1 bit, big-endian, i-signal-type=PRIMITIVE, init-value=constant-reference=Init_CAN3_Fr_MCUDischrgSta_Nidec, base-type=uint8, implementation-data-type=uint8, transfer-property=PENDING
          signal CAN3_Fr_MCUEnaSta_Nidec: start 244, 1 bit, big-endian, i-signal-type=PRIMITIVE, init-value=constant-reference=Init_CAN3_Fr_MCUEnaSta_Nidec, base-type=uint8, implementation-data-type=uint8, transfer-property=PENDING
          signal CAN3_Fr_MCUErr_Nidec: start 143, 8 bit, big-endian, i-signal-type=PRIMITIVE, init-value=constant-reference=Init_CAN3_Fr_MCUErr_Nidec, base-type=uint8, implementation-data-type=uint8, transfer-property=PENDING
          signal CAN3_Fr_MCUIGN_sta_Nidec: start 72, 1 bit, big-endian, i-signal-type=PRIMITIVE, init-value=constant-reference=Init_CAN3_Fr_MCUIGN_sta_Nidec, base-type=uint8, implementation-data-type=uint8, transfer-property=PENDING
          signal CAN3_Fr_MCUReady4Pre_Nidec: start 200, 1 bit, big-endian, i-signal-type=PRIMITIVE, init-value=constant-reference=Init_CAN3_Fr_MCUReady4Pre_Nidec, base-type=uint8, implementation-data-type=uint8, transfer-property=PENDING
          signal CAN3_Fr_MCUReady_Nidec: start 11, 1 bit, big-endian, i-signal-type=PRIMITIVE, init-value=constant-reference=Init_CAN3_Fr_MCUReady_Nidec, base-type=uint8, implementation-data-type=uint8, transfer-property=PENDING
          signal CAN3_Fr_MCUSysSta_Nidec: start 59, 4 bit, big-endian, i-signal-type=PRIMITIVE, init-value=constant-reference=Init_CAN3_Fr_MCUSysSta_Nidec, base-type=uint8, implementation-data-type=uint8, transfer-property=PENDING
          signal CAN3_Fr_MCUTemp_Nidec: start 167, 9 bit, big-endian, i-signal-type=PRIMITIVE, init-value=constant-reference=Init_CAN3_Fr_MCUTemp_Nidec, base-type=uint16, implementation-data-type=uint16, transfer-property=PENDING
          signal CAN3_Fr_MotorAvailTq_Nidec: start 91, 12 bit, big-endian, i-signal-type=PRIMITIVE, init-value=constant-reference=Init_CAN3_Fr_MotorAvailTq_Nidec, base-type=uint16, implementation-data-type=uint16, transfer-property=PENDING
          signal CAN3_Fr_RegenAvailTq_Nidec: start 87, 12 bit, big-endian, i-signal-type=PRIMITIVE, init-value=constant-reference=Init_CAN3_Fr_RegenAvailTq_Nidec, base-type=uint16, implementation-data-type=uint16, transfer-property=PENDING
          signal CAN3_Fr_Reserved_bits_Nidec: start 79, 7 bit, big-endian, i-signal-type=PRIMITIVE, init-value=constant-reference=Init_CAN3_Fr_Reserved_bits_Nidec, base-type=uint8, implementation-data-type=uint8, transfer-property=PENDING
          signal CAN3_Fr_TMSpd_Nidec: start 215, 16 bit, big-endian, i-signal-type=PRIMITIVE, init-value=constant-reference=Init_CAN3_Fr_TMSpd_Nidec, base-type=uint16, implementation-data-type=uint16, transfer-property=PENDING
          signal CAN3_Fr_TMTemp_Nidec: start 144, 9 bit, big-endian, i-signal-type=PRIMITIVE, init-value=constant-reference=Init_CAN3_Fr_TMTemp_Nidec, base-type=uint16, implementation-data-type=uint16, transfer-property=PENDING
          signal CAN3_Fr_TMid_Nidec: start 126, 15 bit, big-endian, i-signal-type=PRIMITIVE, init-value=constant-reference=Init_CAN3_Fr_TMid_Nidec, base-type=uint16, implementation-data-type=uint16, transfer-property=PENDING
          signal CAN3_Fr_TMiq_Nidec: start 110, 15 bit, big-endian, i-signal-type=PRIMITIVE, init-value=constant-reference=Init_CAN3_Fr_TMiq_Nidec, base-type=uint16, implementation-data-type=uint16, transfer-property=PENDING
          signal CAN3_MCUWarn_F_Nidec: start 10, 3 bit, big-endian, i-signal-type=PRIMITIVE, init-value=constant-reference=Init_CAN3_MCUWarn_F_Nidec, base-type=uint8, implementation-data-type=uint8, transfer-property=PENDING
      frame CAN3_MCU_N_F2: id 0x198, frame-length=12, can-addressing-mode=STANDARD, can-fd-frame-support=true, can-frame-rx-behavior=CAN-FD, can-frame-tx-behavior=CAN-FD
        pdu CAN3_MCU_N_F2: length=12, minimum-delay=0.0, transmission-mode-true-timing=cyclic-timing=time-period=0.2, unused-bit-pattern=0
          mapping CAN3_SG_MCU_N_F2: i-signal-group=CAN3_SG_MCU_N_F2, start-position=0, transfer-property=PENDING
          signal CAN3_Fr_CoolanttempReq_Nidec: start 24, 9 bit, big-endian, i-signal-type=PRIMITIVE, init-value=constant-reference=Init_CAN3_Fr_CoolanttempReq_Nidec, base-type=uint16, implementation-data-type=uint16, transfer-property=PENDING
          signal CAN3_Fr_EOP_SpdSet_Nidec: start 67, 12 bit, big-endian, i-signal-type=PRIMITIVE, init-value=constant-reference=Init_CAN3_Fr_EOP_SpdSet_Nidec, base-type=uint16, implementation-data-type=uint16, transfer-property=PENDING
          signal CAN3_Fr_Failcode1_Nidec: start 63, 8 bit, big-endian, i-signal-type=PRIMITIVE, init-value=constant-reference=Init_CAN3_Fr_Failcode1_Nidec, base-type=uint8, implementation-data-type=uint8, transfer-property=PENDING
          signal CAN3_Fr_Failcode2_Nidec: start 55, 8 bit, big-endian, i-signal-type=PRIMITIVE, init-value=constant-reference=Init_CAN3_Fr_Failcode2_Nidec, base-type=uint8, implementation-data-type=uint8, transfer-property=PENDING
          signal CAN3_Fr_Failcodehistory1_Nidec: start 41, 2 bit, big-endian, i-signal-type=PRIMITIVE, init-value=constant-reference=Init_CAN3_Fr_Failcodehistory1_Nidec, base-type=uint8, implementation-data-type=uint8, transfer-property=PENDING
          signal CAN3_Fr_Failcodehistory2_Nidec: start 43, 2 bit, big-endian, i-signal-type=PRIMITIVE, init-value=constant-reference=Init_CAN3_Fr_Failcodehistory2_Nidec, base-type=uint8, implementation-data-type=uint8, transfer-property=PENDING
          signal CAN3_Fr_LLCTemp_Nidec: start 80, 9 bit, big-endian, i-signal-type=PRIMITIVE, init-value=constant-reference=Init_CAN3_Fr_LLCTemp_Nidec, base-type=uint16, implementation-data-type=uint16, transfer-property=PENDING
          signal CAN3_Fr_LLCflowReq_Nidec: start 87, 6 bit, big-endian, i-signal-type=PRIMITIVE, init-value=constant-reference=Init_CAN3_Fr_LLCflowReq_Nidec, base-type=uint8, implementation-data-type=uint8, transfer-property=PENDING
          signal CAN3_Fr_MCU2Chksum_Nidec: start 7, 8 bit, big-endian, i-signal-type=PRIMITIVE, init-value=constant-reference=Init_CAN3_Fr_MCU2Chksum_Nidec, base-type=uint8, implementation-data-type=uint8, transfer-property=PENDING
          signal CAN3_Fr_MCU2RolCnt_Nidec: start 15, 4 bit, big-endian, i-signal-type=PRIMITIVE, init-value=constant-reference=Init_CAN3_Fr_MCU2RolCnt_Nidec, base-type=uint8, implementation-data-type=uint8, transfer-property=PENDING
          signal CAN3_Fr_MCUTempWarn_Nidec: start 47, 2 bit, big-endian, i-signal-type=PRIMITIVE, init-value=constant-reference=Init_CAN3_Fr_MCUTempWarn_Nidec, base-type=uint8, implementation-data-type=uint8, transfer-property=PENDING
          signal CAN3_Fr_TMTempWarn_Nidec: start 45, 2 bit, big-endian, i-signal-type=PRIMITIVE, init-value=constant-reference=Init_CAN3_Fr_TMTempWarn_Nidec, base-type=uint8, implementation-data-type=uint8, transfer-property=PENDING
          signal CAN3_MCU_F_ResetCnt_Sta: start 23, 8 bit, big-endian, i-signal-type=PRIMITIVE, init-value=constant-reference=Init_CAN3_MCU_F_ResetCnt_Sta, base-type=uint8, implementation-data-type=uint8, transfer-property=PENDING
      frame CAN3_MCU_N_F3: id 0x399, frame-length=8, can-addressing-mode=STANDARD, can-fd-frame-support=true, can-frame-rx-behavior=CAN-FD, can-frame-tx-behavior=CAN-FD
        pdu CAN3_MCU_N_F3: length=8, minimum-delay=0.0, transmission-mode-true-timing=cyclic-timing=time-period=1, unused-bit-pattern=0
          mapping CAN3_SG_MCU_N_F3: i-signal-group=CAN3_SG_MCU_N_F3, start-position=0, transfer-property=PENDING
          signal CAN3_Fr_MCU_HW_Ver_Nidec: start 39, 16 bit, big-endian, i-signal-type=PRIMITIVE, init-value=constant-reference=Init_CAN3_Fr_MCU_HW_Ver_Nidec, base-type=uint16, implementation-data-type=uint16, transfer-property=PENDING
          signal CAN3_Fr_MCU_SW_Ver_Nidec: start 55, 16 bit, big-endian, i-signal-type=PRIMITIVE, init-value=constant-reference=Init_CAN3_Fr_MCU_SW_Ver_Nidec, base-type=uint16, implementation-data-type=uint16, transfer-property=PENDING
      frame CAN3_MCU_N_R1: id 0x192, frame-length=32, can-addressing-mode=STANDARD, can-fd-frame-support=true, can-frame-rx-behavior=CAN-FD, can-frame-tx-behavior=CAN-FD
        pdu CAN3_MCU_N_R1: length=32, minimum-delay=0.0, transmission-mode-true-timing=cyclic-timing=time-period=0.01, unused-bit-pattern=0
          mapping CAN3_SG_MCU_N_R1: i-signal-group=CAN3_SG_MCU_N_R1, start-position=0, transfer-property=PENDING
          signal CAN3_MCUWarn_R_Nidec: start 10, 3 bit, big-endian, i-signal-type=PRIMITIVE, init-value=constant-reference=Init_CAN3_MCUWarn_R_Nidec, base-type=uint8, implementation-data-type=uint8, transfer-property=PENDING
          signal CAN3_Rr_ActvDmpDisabSta_Nidec: start 201, 1 bit, big-endian, i-signal-type=PRIMITIVE, init-value=constant-reference=Init_CAN3_Rr_ActvDmpDisabSta_Nidec, base-type=uint8, implementation-data-type=uint8, transfer-property=PENDING
          signal CAN3_Rr_EDUDrtSta_Nidec: start 202, 1 bit, big-endian, i-signal-type=PRIMITIVE, init-value=constant-reference=Init_CAN3_Rr_EDUDrtSta_Nidec, base-type=uint8, implementation-data-type=uint8, transfer-property=PENDING
          signal CAN3_Rr_EDUOpratingSta_Nidec: start 245, 1 bit, big-endian, i-signal-type=PRIMITIVE, init-value=constant-reference=Init_CAN3_Rr_EDUOpratingSta_Nidec, base-type=uint8, implementation-data-type=uint8, transfer-property=PENDING
          signal CAN3_Rr_EDURealTMTq_Nidec: start 227, 12 bit, big-endian, i-signal-type=PRIMITIVE, init-value=constant-reference=Init_CAN3_Rr_EDURealTMTq_Nidec, base-type=uint16, implementation-data-type=uint16, transfer-property=PENDING
          signal CAN3_Rr_EDURotateDirction_Nidec: start 247, 2 bit, big-endian, i-signal-type=PRIMITIVE, init-value=constant-reference=Init_CAN3_Rr_EDURotateDirction_Nidec, base-type=uint8, implementation-data-type=uint8, transfer-property=PENDING
          signal CAN3_Rr_EDUTqReqFbk_Nidec: start 243, 12 bit, big-endian, i-signal-type=PRIMITIVE, init-value=constant-reference=Init_CAN3_Rr_EDUTqReqFbk_Nidec, base-type=uint16, implementation-data-type=uint16, transfer-property=PENDING
          signal CAN3_Rr_MCU1Chksum_Nidec: start 7, 8 bit, big-endian, i-signal-type=PRIMITIVE, init-value=constant-reference=Init_CAN3_Rr_MCU1Chksum_Nidec, base-type=uint8, implementation-data-type=uint8, transfer-property=PENDING
          signal CAN3_Rr_MCU1RolCnt_Nidec: start 15, 4 bit, big-endian, i-signal-type=PRIMITIVE, init-value=constant-reference=Init_CAN3_Rr_MCU1RolCnt_Nidec, base-type=uint8, implementation-data-type=uint8, transfer-property=PENDING
          signal CAN3_Rr_MCUBAT_Nidec: start 71, 8 bit, big-endian, i-signal-type=PRIMITIVE, init-value=constant-reference=Init_CAN3_Rr_MCUBAT_Nidec, base-type=uint8, implementation-data-type=uint8, transfer-property=PENDING
          signal CAN3_Rr_MCUDCBusCurr_Nidec: start 174, 15 bit, big-endian, i-signal-type=PRIMITIVE, init-value=constant-reference=Init_CAN3_Rr_MCUDCBusCurr_Nidec, base-type=uint16, implementation-data-type=uint16, transfer-property=PENDING
          signal CAN3_Rr_MCUDCBusVolt_Nidec: start 191, 16 bit, big-endian, i-signal-type=PRIMITIVE, init-value=constant-reference=Init_CAN3_Rr_MCUDCBusVolt_Nidec, base-type=uint16, implementation-data-type=uint16, transfer-property=PENDING
          signal CAN3_Rr_MCUDischrgSta_Nidec: start 203, 1 bit, big-endian, i-signal-type=PRIMITIVE, init-value=constant-reference=Init_CAN3_Rr_MCUDischrgSta_Nidec, base-type=uint8, implementation-data-type=uint8, transfer-property=PENDING
          signal CAN3_Rr_MCUEnaSta_Nidec: start 244, 1 bit, big-endian, i-signal-type=PRIMITIVE, init-value=constant-reference=Init_CAN3_Rr_MCUEnaSta_Nidec, base-type=uint8, implementation-data-type=uint8, transfer-property=PENDING
          signal CAN3_Rr_MCUErr_Nidec: start 143, 8 bit, big-endian, i-signal-type=PRIMITIVE, init-value=constant-reference=Init_CAN3_Rr_MCUErr_Nidec, base-type=uint8, implementation-data-type=uint8, transfer-property=PENDING
          signal CAN3_Rr_MCUIGN_sta_Nidec: start 72, 1 bit, big-endian, i-signal-type=PRIMITIVE, init-value=constant-reference=Init_CAN3_Rr_MCUIGN_sta_Nidec, base-type=uint8, implementation-data-type=uint8, transfer-property=PENDING
          signal CAN3_Rr_MCUReady4Pre_Nidec: start 200, 1 bit, big-endian, i-signal-type=PRIMITIVE, init-value=constant-reference=Init_CAN3_Rr_MCUReady4Pre_Nidec, base-type=uint8, implementation-data-type=uint8, transfer-property=PENDING
          signal CAN3_Rr_MCUReady_Nidec: start 207, 1 bit, big-endian, i-signal-type=PRIMITIVE, init-value=constant-reference=Init_CAN3_Rr_MCUReady_Nidec, base-type=uint8, implementation-data-type=uint8, transfer-property=PENDING
          signal CAN3_Rr_MCUSysSta_Nidec: start 59, 4 bit, big-endian, i-signal-type=PRIMITIVE, init-value=constant-reference=Init_CAN3_Rr_MCUSysSta_Nidec, base-type=uint8, implementation-data-type=uint8, transfer-property=PENDING
          signal CAN3_Rr_MCUTemp_Nidec: start 167, 9 bit, big-endian, i-signal-type=PRIMITIVE, init-value=constant-reference=Init_CAN3_Rr_MCUTemp_Nidec, base-type=uint16, implementation-data-type=uint16, transfer-property=PENDING
          signal CAN3_Rr_MotorAvailTq_Nidec: start 91, 12 bit, big-endian, i-signal-type=PRIMITIVE, init-value=constant-reference=Init_CAN3_Rr_MotorAvailTq_Nidec, base-type=uint16, implementation-data-type=uint16, transfer-property=PENDING
          signal CAN3_Rr_RegenAvailTq_Nidec: start 87, 12 bit, big-endian, i-signal-type=PRIMITIVE, init-value=constant-reference=Init_CAN3_Rr_RegenAvailTq_Nidec, base-type=uint16, implementation-data-type=uint16, transfer-property=PENDING
          signal CAN3_Rr_Reserved_bits_Nidec: start 79, 7 bit, big-endian, i-signal-type=PRIMITIVE, init-value=constant-reference=Init_CAN3_Rr_Reserved_bits_Nidec, base-type=uint8, implementation-data-type=uint8, transfer-property=PENDING
          signal CAN3_Rr_TMSpd_Nidec: start 215, 16 bit, big-endian, i-signal-type=PRIMITIVE, init-value=constant-reference=Init_CAN3_Rr_TMSpd_Nidec, base-type=uint16, implementation-data-type=uint16, transfer-property=PENDING
          signal CAN3_Rr_TMTemp_Nidec: start 144, 9 bit, big-endian, i-signal-type=PRIMITIVE, init-value=constant-reference=Init_CAN3_Rr_TMTemp_Nidec, base-type=uint16, implementation-data-type=uint16, transfer-property=PENDING
          signal CAN3_Rr_TMid_Nidec: start 126, 15 bit, big-endian, i-signal-type=PRIMITIVE, init-value=constant-reference=Init_CAN3_Rr_TMid_Nidec, base-type=uint16, implementation-data-type=uint16, transfer-property=PENDING
          signal CAN3_Rr_TMiq_Nidec: start 110, 15 bit, big-endian, i-signal-type=PRIMITIVE, init-value=constant-reference=Init_CAN3_Rr_TMiq_Nidec, base-type=uint16, implementation-data-type=uint16, transfer-property=PENDING
      frame CAN3_MCU_N_R2: id 0x19C, frame-length=12, can-addressing-mode=STANDARD, can-fd-frame-support=true, can-frame-rx-behavior=CAN-FD, can-frame-tx-behavior=CAN-FD
        pdu CAN3_MCU_N_R2: length=12, minimum-delay=0.0, transmission-mode-true-timing=cyclic-timing=time-period=0.2, unused-bit-pattern=0
          mapping CAN3_SG_MCU_N_R2: i-signal-group=CAN3_SG_MCU_N_R2, start-position=0, transfer-property=PENDING
          signal CAN3_MCU_R_ResetCnt_Sta: start 23, 8 bit, big-endian, i-signal-type=PRIMITIVE, init-value=constant-reference=Init_CAN3_MCU_R_ResetCnt_Sta, base-type=uint8, implementation-data-type=uint8, transfer-property=PENDING
          signal CAN3_Rr_CoolanttempReq_Nidec: start 24, 9 bit, big-endian, i-signal-type=PRIMITIVE, init-value=constant-reference=Init_CAN3_Rr_CoolanttempReq_Nidec, base-type=uint16, implementation-data-type=uint16, transfer-property=PENDING
          signal CAN3_Rr_EOP_SpdSet_Nidec: start 67, 12 bit, big-endian, i-signal-type=PRIMITIVE, init-value=constant-reference=Init_CAN3_Rr_EOP_SpdSet_Nidec, base-type=uint16, implementation-data-type=uint16, transfer-property=PENDING
          signal CAN3_Rr_Failcode1_Nidec: start 63, 8 bit, big-endian, i-signal-type=PRIMITIVE, init-value=constant-reference=Init_CAN3_Rr_Failcode1_Nidec, base-type=uint8, implementation-data-type=uint8, transfer-property=PENDING
          signal CAN3_Rr_Failcode2_Nidec: start 55, 8 bit, big-endian, i-signal-type=PRIMITIVE, init-value=constant-reference=Init_CAN3_Rr_Failcode2_Nidec, base-type=uint8, implementation-data-type=uint8, transfer-property=PENDING
          signal CAN3_Rr_Failcodehistory1_Nidec: start 41, 2 bit, big-endian, i-signal-type=PRIMITIVE, init-value=constant-reference=Init_CAN3_Rr_Failcodehistory1_Nidec, base-type=uint8, implementation-data-type=uint8, transfer-property=PENDING
          signal CAN3_Rr_Failcodehistory2_Nidec: start 43, 2 bit, big-endian, i-signal-type=PRIMITIVE, init-value=constant-reference=Init_CAN3_Rr_Failcodehistory2_Nidec, base-type=uint8, implementation-data-type=uint8, transfer-property=PENDING
          signal CAN3_Rr_LLCTemp_Nidec: start 80, 9 bit, big-endian, i-signal-type=PRIMITIVE, init-value=constant-reference=Init_CAN3_Rr_LLCTemp_Nidec, base-type=uint16, implementation-data-type=uint16, transfer-property=PENDING
          signal CAN3_Rr_LLCflowReq_Nidec: start 87, 6 bit, big-endian, i-signal-type=PRIMITIVE, init-value=constant-reference=Init_CAN3_Rr_LLCflowReq_Nidec, base-type=uint8, implementation-data-type=uint8, transfer-property=PENDING
          signal CAN3_Rr_MCU2Chksum_Nidec: start 7, 8 bit, big-endian, i-signal-type=PRIMITIVE, init-value=constant-reference=Init_CAN3_Rr_MCU2Chksum_Nidec, base-type=uint8, implementation-data-type=uint8, transfer-property=PENDING
          signal CAN3_Rr_MCU2RolCnt_Nidec: start 15, 4 bit, big-endian, i-signal-type=PRIMITIVE, init-value=constant-reference=Init_CAN3_Rr_MCU2RolCnt_Nidec, base-type=uint8, implementation-data-type=uint8, transfer-property=PENDING
          signal CAN3_Rr_MCUTempWarn_Nidec: start 47, 2 bit, big-endian, i-signal-type=PRIMITIVE, init-value=constant-reference=Init_CAN3_Rr_MCUTempWarn_Nidec, base-type=uint8, implementation-data-type=uint8, transfer-property=PENDING
          signal CAN3_Rr_TMTempWarn_Nidec: start 45, 2 bit, big-endian, i-signal-type=PRIMITIVE, init-value=constant-reference=Init_CAN3_Rr_TMTempWarn_Nidec, base-type=uint8, implementation-data-type=uint8, transfer-property=PENDING
      frame CAN3_MCU_N_R3: id 0x39D, frame-length=8, can-addressing-mode=STANDARD, can-fd-frame-support=true, can-frame-rx-behavior=CAN-FD, can-frame-tx-behavior=CAN-FD
        pdu CAN3_MCU_N_R3: length=8, minimum-delay=0.0, transmission-mode-true-timing=cyclic-timing=time-period=1, unused-bit-pattern=0
          mapping CAN3_SG_MCU_N_R3: i-signal-group=CAN3_SG_MCU_N_R3, start-position=0, transfer-property=PENDING
          signal CAN3_Rr_MCU3_HW_Ver_Nidec: start 39, 16 bit, big-endian, i-signal-type=PRIMITIVE, init-value=constant-reference=Init_CAN3_Rr_MCU3_HW_Ver_Nidec, base-type=uint16, implementation-data-type=uint16, transfer-property=PENDING
          signal CAN3_Rr_MCU3_SW_Ver_Nidec: start 55, 16 bit, big-endian, i-signal-type=PRIMITIVE, init-value=constant-reference=Init_CAN3_Rr_MCU3_SW_Ver_Nidec, base-type=uint16, implementation-data-type=uint16, transfer-property=PENDING
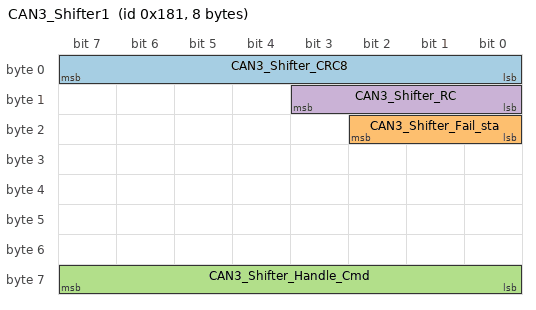
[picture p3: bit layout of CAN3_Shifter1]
      frame CAN3_Shifter1: id 0x181, frame-length=8, can-addressing-mode=STANDARD, can-fd-frame-support=true, can-frame-rx-behavior=CAN-FD, can-frame-tx-behavior=CAN-FD
        pdu CAN3_Shifter1: length=8, minimum-delay=0.0, transmission-mode-true-timing={cyclic-timing=time-period=0.1, event-controlled-timing={number-of-repetitions=0, repetition-period=0}}, unused-bit-pattern=0
          mapping CAN3_SG_Shifter1: i-signal-group=CAN3_SG_Shifter1, start-position=0, transfer-property=TRIGGERED-ON-CHANGE
          signal CAN3_Shifter_CRC8: start 7, 8 bit, big-endian, i-signal-type=PRIMITIVE, init-value=constant-reference=Init_CAN3_Shifter_CRC8, base-type=uint8, implementation-data-type=uint8, transfer-property=TRIGGERED-ON-CHANGE
          signal CAN3_Shifter_Fail_sta: start 18, 3 bit, big-endian, i-signal-type=PRIMITIVE, init-value=constant-reference=Init_CAN3_Shifter_Fail_sta, base-type=uint8, implementation-data-type=uint8, transfer-property=TRIGGERED-ON-CHANGE
          signal CAN3_Shifter_Handle_Cmd: start 63, 8 bit, big-endian, i-signal-type=PRIMITIVE, init-value=constant-reference=Init_CAN3_Shifter_Handle_Cmd, base-type=uint8, implementation-data-type=uint8, transfer-property=TRIGGERED-ON-CHANGE
          signal CAN3_Shifter_RC: start 11, 4 bit, big-endian, i-signal-type=PRIMITIVE, init-value=constant-reference=Init_CAN3_Shifter_RC, base-type=uint8, implementation-data-type=uint8, transfer-property=TRIGGERED-ON-CHANGE
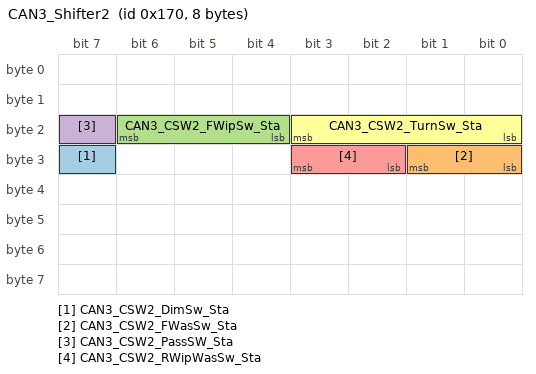
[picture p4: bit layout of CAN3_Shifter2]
      frame CAN3_Shifter2: id 0x170, frame-length=8, can-addressing-mode=STANDARD, can-fd-frame-support=true, can-frame-rx-behavior=CAN-FD, can-frame-tx-behavior=CAN-FD
        pdu CAN3_Shifter2: length=8, minimum-delay=0.0, transmission-mode-true-timing={cyclic-timing=time-period=0.1, event-controlled-timing={number-of-repetitions=0, repetition-period=0}}, unused-bit-pattern=0
          mapping CAN3_SG_Shifter2: i-signal-group=CAN3_SG_Shifter2, start-position=0, transfer-property=TRIGGERED-ON-CHANGE
          signal CAN3_CSW2_DimSw_Sta: start 31, 1 bit, big-endian, i-signal-type=PRIMITIVE, init-value=constant-reference=Init_CAN3_CSW2_DimSw_Sta, base-type=uint8, implementation-data-type=uint8, transfer-property=TRIGGERED-ON-CHANGE
          signal CAN3_CSW2_FWasSw_Sta: start 25, 2 bit, big-endian, i-signal-type=PRIMITIVE, init-value=constant-reference=Init_CAN3_CSW2_FWasSw_Sta, base-type=uint8, implementation-data-type=uint8, transfer-property=TRIGGERED-ON-CHANGE
          signal CAN3_CSW2_FWipSw_Sta: start 22, 3 bit, big-endian, i-signal-type=PRIMITIVE, init-value=constant-reference=Init_CAN3_CSW2_FWipSw_Sta, base-type=uint8, implementation-data-type=uint8, transfer-property=TRIGGERED-ON-CHANGE
          signal CAN3_CSW2_PassSW_Sta: start 23, 1 bit, big-endian, i-signal-type=PRIMITIVE, init-value=constant-reference=Init_CAN3_CSW2_PassSW_Sta, base-type=uint8, implementation-data-type=uint8, transfer-property=TRIGGERED-ON-CHANGE
          signal CAN3_CSW2_RWipWasSw_Sta: start 27, 2 bit, big-endian, i-signal-type=PRIMITIVE, init-value=constant-reference=Init_CAN3_CSW2_RWipWasSw_Sta, base-type=uint8, implementation-data-type=uint8, transfer-property=TRIGGERED-ON-CHANGE
          signal CAN3_CSW2_TurnSw_Sta: start 19, 4 bit, big-endian, i-signal-type=PRIMITIVE, init-value=constant-reference=Init_CAN3_CSW2_TurnSw_Sta, base-type=uint8, implementation-data-type=uint8, transfer-property=TRIGGERED-ON-CHANGE
      frame CAN3_NMm_FUSION_TX: id 0x500, frame-length=8, can-addressing-mode=STANDARD, can-fd-frame-support=false, can-frame-rx-behavior=CAN-20, can-frame-tx-behavior=CAN-20
        nm pdu CAN3_NMm_FUSION_TX: length=8, unused-bit-pattern=0
      frame CAN3_NMm_FUSION_RX: id 0x500, frame-length=8, can-addressing-mode=STANDARD, can-fd-frame-support=false, can-frame-rx-behavior=CAN-20, can-frame-tx-behavior=CAN-20
        nm pdu CAN3_NMm_FUSION_RX: length=8, unused-bit-pattern=0
